VERSION ""

NS_ :

BS_:

BU_: BCMB_AUXM FCIM MRCMA_RSCM SCMJ BCMB_ALCM SCMB_PSM SCMD SCMC HVAC_RCCM MRCMB MRCMA DASM GFM_FTRM BCMB_CAPM DCMH SFMB SFMA SOBDMD_AHCM_FOH TRM GWM _delete BCMB_ABM SODL SCMF RTM RHVAC PDM DCMG DCMF DCME SCMH SCMG HSWM RSM SODR DDM RBM RGTM DSM SCME GENERIC TSTR

BO_ 1861 TesterPhysicalReqDASM: 8 TSTR
 SG_ TesterPhysicalReqDASM : 7|64@0+ (1,0) [0|1.84467E+019] "unitless"  DASM

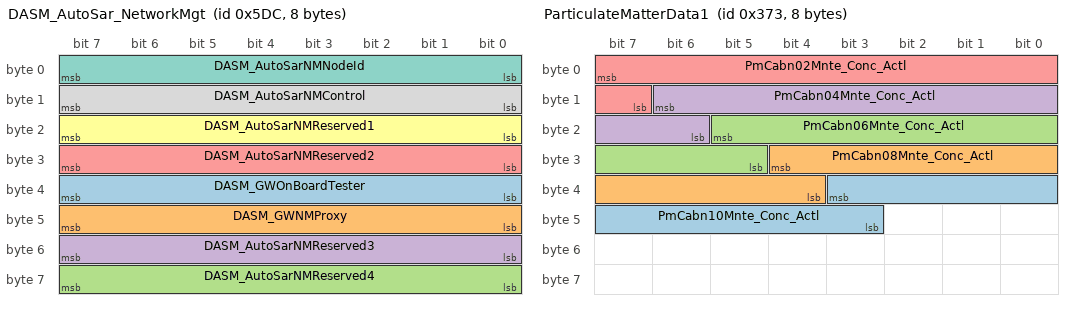
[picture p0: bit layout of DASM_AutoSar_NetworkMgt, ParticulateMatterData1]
BO_ 1500 DASM_AutoSar_NetworkMgt: 8 DASM
 SG_ DASM_GWOnBoardTester : 39|8@0+ (1,0) [0|255] "unitless"  GWM
 SG_ DASM_GWNMProxy : 47|8@0+ (1,0) [0|255] "unitless"  GWM
 SG_ DASM_AutoSarNMReserved4 : 63|8@0+ (1,0) [0|255] "unitless"  GWM
 SG_ DASM_AutoSarNMReserved3 : 55|8@0+ (1,0) [0|255] "unitless"  GWM
 SG_ DASM_AutoSarNMReserved2 : 31|8@0+ (1,0) [0|255] "unitless"  GWM
 SG_ DASM_AutoSarNMReserved1 : 23|8@0+ (1,0) [0|255] "unitless"  GWM
 SG_ DASM_AutoSarNMNodeId : 7|8@0+ (1,0) [0|255] "unitless"  GWM
 SG_ DASM_AutoSarNMControl : 15|8@0+ (1,0) [0|255] "unitless"  GWM

BO_ 1799 TesterPhysicalReqGFM3_MS1: 8 TSTR
 SG_ TesterPhysicalReqGFM3_FSLM : 7|64@0+ (1,0) [0|1.84467E+019] "unitless" Vector__XXX

BO_ 883 ParticulateMatterData1: 8 HVAC_RCCM
 SG_ PmCabn10Mnte_Conc_Actl : 35|9@0+ (1,0) [0|509] "parts/million"  GWM
 SG_ PmCabn08Mnte_Conc_Actl : 28|9@0+ (1,0) [0|509] "parts/million"  GWM
 SG_ PmCabn06Mnte_Conc_Actl : 21|9@0+ (1,0) [0|509] "parts/million"  GWM
 SG_ PmCabn04Mnte_Conc_Actl : 14|9@0+ (1,0) [0|509] "parts/million"  GWM
 SG_ PmCabn02Mnte_Conc_Actl : 7|9@0+ (1,0) [0|509] "parts/million"  GWM

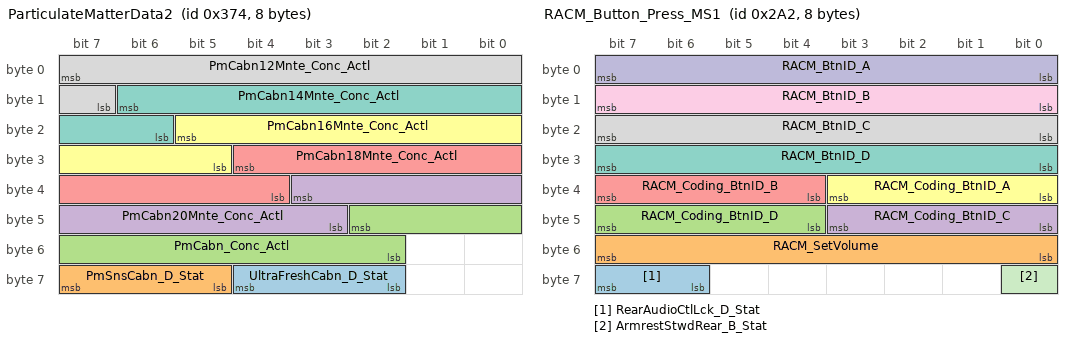
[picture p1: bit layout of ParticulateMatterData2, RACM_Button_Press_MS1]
BO_ 884 ParticulateMatterData2: 8 HVAC_RCCM
 SG_ UltraFreshCabn_D_Stat : 60|3@0+ (1,0) [0|7] "SED"  GWM
 SG_ PmSnsCabn_D_Stat : 63|3@0+ (1,0) [0|7] "SED"  GWM
 SG_ PmCabn_Conc_Actl : 42|9@0+ (1,0) [0|509] "parts/million"  GWM
 SG_ PmCabn20Mnte_Conc_Actl : 35|9@0+ (1,0) [0|509] "parts/million"  GWM
 SG_ PmCabn18Mnte_Conc_Actl : 28|9@0+ (1,0) [0|509] "parts/million"  GWM
 SG_ PmCabn16Mnte_Conc_Actl : 21|9@0+ (1,0) [0|509] "parts/million"  GWM
 SG_ PmCabn14Mnte_Conc_Actl : 14|9@0+ (1,0) [0|509] "parts/million"  GWM
 SG_ PmCabn12Mnte_Conc_Actl : 7|9@0+ (1,0) [0|509] "parts/million"  GWM

BO_ 674 RACM_Button_Press_MS1: 8 GWM
 SG_ RearAudioCtlLck_D_Stat : 63|2@0+ (1,0) [0|3] "SED"  GENERIC
 SG_ RACM_SetVolume : 55|8@0+ (1,-30) [-30|30] "unitless"  GENERIC
 SG_ RACM_Coding_BtnID_D : 47|4@0+ (1,0) [0|15] "SED"  GENERIC
 SG_ RACM_Coding_BtnID_C : 43|4@0+ (1,0) [0|15] "SED"  GENERIC
 SG_ RACM_Coding_BtnID_B : 39|4@0+ (1,0) [0|15] "SED"  GENERIC
 SG_ RACM_Coding_BtnID_A : 35|4@0+ (1,0) [0|15] "SED"  GENERIC
 SG_ RACM_BtnID_D : 31|8@0+ (1,0) [0|255] "unitless"  GENERIC
 SG_ RACM_BtnID_C : 23|8@0+ (1,0) [0|255] "unitless"  GENERIC
 SG_ RACM_BtnID_B : 15|8@0+ (1,0) [0|255] "unitless"  GENERIC
 SG_ RACM_BtnID_A : 7|8@0+ (1,0) [0|255] "unitless"  GENERIC
 SG_ ArmrestStwdRear_B_Stat : 56|1@0+ (1,0) [0|1] "SED"  RHVAC

BO_ 2611177688 PARSEDPhysGWM_ECGtoRTM: 8 GWM
 SG_ PARSEDPhysGWM_ECGtoRTM : 7|29@0+ (1,0) [0|536870911] "unitless"  RTM

BO_ 2611175642 PARSEDPhysRTMtoGWM_ECG: 8 RTM
 SG_ PARSEDPhysRTMtoGWM_ECG : 7|29@0+ (1,0) [0|536870911] "unitless"  GWM

BO_ 2612224218 PARSEDPushRTMtoGWM_ECG: 8 RTM
 SG_ PARSEDPushRTMtoGWM_ECG : 7|29@0+ (1,0) [0|536870911] "unitless"  GWM

BO_ 1349 RBM_Network_MgmtM: 8 RBM
 SG_ RBM_Network_Mgmt : 7|64@0+ (1,0) [0|1.84467440737096E+019] "unitless"  GENERIC

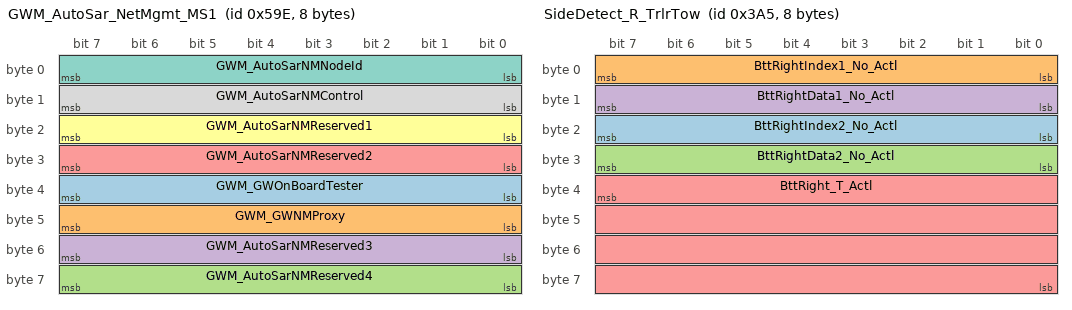
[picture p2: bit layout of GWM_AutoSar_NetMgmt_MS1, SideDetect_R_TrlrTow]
BO_ 1438 GWM_AutoSar_NetMgmt_MS1: 8 GWM
 SG_ GWM_GWOnBoardTester : 39|8@0+ (1,0) [0|255] "unitless"  RHVAC,FCIM,GFM_FTRM,RTM,DCMH,DCMG,DCMF,DCME,HVAC_RCCM,SCMJ,DDM,PDM,RGTM
 SG_ GWM_GWNMProxy : 47|8@0+ (1,0) [0|255] "unitless"  RHVAC,FCIM,GFM_FTRM,RTM,DCMH,DCMG,DCMF,DCME,HVAC_RCCM,SCMJ,DDM,PDM,RGTM
 SG_ GWM_AutoSarNMReserved4 : 63|8@0+ (1,0) [0|255] "unitless"  RHVAC,FCIM,GFM_FTRM,RTM,DCMH,DCMG,DCMF,DCME,HVAC_RCCM,SCMJ,DDM,PDM,RGTM
 SG_ GWM_AutoSarNMReserved3 : 55|8@0+ (1,0) [0|255] "unitless"  RHVAC,FCIM,GFM_FTRM,RTM,DCMH,DCMG,DCMF,DCME,HVAC_RCCM,SCMJ,DDM,PDM,RGTM
 SG_ GWM_AutoSarNMReserved2 : 31|8@0+ (1,0) [0|255] "unitless"  RHVAC,FCIM,GFM_FTRM,RTM,DCMH,DCMG,DCMF,DCME,HVAC_RCCM,SCMJ,DDM,PDM,RGTM
 SG_ GWM_AutoSarNMReserved1 : 23|8@0+ (1,0) [0|255] "unitless"  RHVAC,FCIM,GFM_FTRM,RTM,DCMH,DCMG,DCMF,DCME,HVAC_RCCM,SCMJ,DDM,PDM,RGTM
 SG_ GWM_AutoSarNMNodeId : 7|8@0+ (1,0) [0|255] "unitless"  RHVAC,FCIM,GFM_FTRM,DCMH,DCMG,DCMF,DCME,RTM,HVAC_RCCM,SCMJ,DDM,PDM,RGTM
 SG_ GWM_AutoSarNMControl : 15|8@0+ (1,0) [0|255] "unitless"  RHVAC,FCIM,GFM_FTRM,DCMH,DCMG,DCMF,DCME,RTM,HVAC_RCCM,SCMJ,DDM,PDM,RGTM

BO_ 933 SideDetect_R_TrlrTow: 8 SODR
 SG_ BttRightIndex2_No_Actl : 23|8@0+ (1,0) [0|255] "unitless"  GWM,SODL
 SG_ BttRightIndex1_No_Actl : 7|8@0+ (1,0) [0|255] "unitless"  GWM,SODL
 SG_ BttRightData2_No_Actl : 31|8@0+ (1,0) [0|255] "unitless"  GWM,SODL
 SG_ BttRightData1_No_Actl : 15|8@0+ (1,0) [0|255] "unitless"  GWM,SODL
 SG_ BttRight_T_Actl : 39|32@0+ (1,0) [0|4294967295] "ms"  GWM,SODL

BO_ 841 FuelOpHeater_Stat2: 8 SOBDMD_AHCM_FOH
 SG_ FohStrtDateDay_No_Stat : 7|16@0+ (1,0) [0|65535] "julian day"  GWM
 SG_ FohStrtDateYr_No_Stat : 23|8@0+ (1,2000) [2000|2255] "year"  GWM
 SG_ FohAddHeater_D_Stat : 31|2@0+ (1,0) [0|3] "SED"  GWM

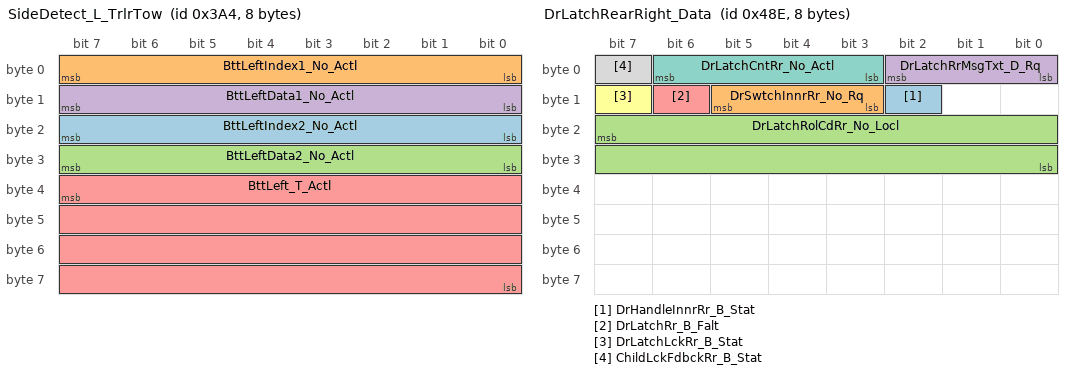
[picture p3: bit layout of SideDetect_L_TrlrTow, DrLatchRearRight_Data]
BO_ 932 SideDetect_L_TrlrTow: 8 SODL
 SG_ BttLeftIndex2_No_Actl : 23|8@0+ (1,0) [0|255] "unitless"  GWM,SODR
 SG_ BttLeftIndex1_No_Actl : 7|8@0+ (1,0) [0|255] "unitless"  GWM,SODR
 SG_ BttLeftData2_No_Actl : 31|8@0+ (1,0) [0|255] "unitless"  GWM,SODR
 SG_ BttLeftData1_No_Actl : 15|8@0+ (1,0) [0|255] "unitless"  GWM,SODR
 SG_ BttLeft_T_Actl : 39|32@0+ (1,0) [0|4294967295] "ms"  GWM,SODR

BO_ 1075 BodyGatewayData_3_MS1: 8 GWM
 SG_ ACU_RadioSeekMode2_St : 60|5@0+ (1,0) [0|31] "SED"  DCMH,DCMG,DDM,PDM,RGTM
 SG_ ACU_CurrTUBand_St : 45|4@0+ (1,0) [0|15] "SED"  DCMH,DCMG,DDM,PDM,RGTM
 SG_ ACU_CurrentFreq_St : 55|11@0+ (1,0) [0|1557] "unitless"  DCMH,DCMG,DDM,PDM,RGTM
 SG_ ACU_RadioSeekMode2_St_UB : 41|1@0+ (1,0) [0|1] "SED"  DCMH,DCMG,DDM,PDM,RGTM
 SG_ ACU_CurrTUBand_St_UB : 32|1@0+ (1,0) [0|1] "SED"  DCMH,DCMG,DDM,PDM,RGTM
 SG_ ACU_CurrentFreq_St_UB : 33|1@0+ (1,0) [0|1] "SED"  DCMH,DCMG,DDM,PDM,RGTM
 SG_ CtaBrk_D_Stat_UB : 40|1@0+ (1,0) [0|1] "SED"  SODR,SODL
 SG_ CtaBrk_D_Stat : 47|2@0+ (1,0) [0|3] "SED"  SODR,SODL
 SG_ SelDrvMdePt_D_Rq_UB : 34|1@0+ (1,0) [0|1] "SED"  FCIM,HVAC_RCCM
 SG_ SelDrvMdePt_D_Rq : 39|5@0+ (1,0) [0|31] "SED"  FCIM,HVAC_RCCM
 SG_ PrkAidSnsRrCrnr_D_Stat : 19|4@0+ (1,0) [0|15] "SED"  SODR,SODL
 SG_ PrkAidSnsRrCntr_D_Stat : 31|4@0+ (1,0) [0|15] "SED"  SODR,SODL
 SG_ PrkAidSnsRlCrnr_D_Stat : 13|4@0+ (1,0) [0|15] "SED"  SODR,SODL
 SG_ PrkAidSnsRlCntr_D_Stat : 23|4@0+ (1,0) [0|15] "SED"  SODR,SODL
 SG_ PrkAidSnsRrCrnr_D_Stat_UB : 27|1@0+ (1,0) [0|1] "SED"  SODR,SODL
 SG_ PrkAidSnsRrCntr_D_Stat_UB : 26|1@0+ (1,0) [0|1] "SED"  SODR,SODL
 SG_ PrkAidSnsRlCntr_D_Stat_UB : 8|1@0+ (1,0) [0|1] "SED"  SODR,SODL
 SG_ PrkAidSnsRlCrnr_D_Stat_UB : 9|1@0+ (1,0) [0|1] "SED"  SODR,SODL
 SG_ BttOn_B_Rq_UB : 14|1@0+ (1,0) [0|1] "SED"  SODR,SODL
 SG_ Btt_L_Actl_UB : 0|1@0+ (1,0) [0|1] "SED"  SODR,SODL
 SG_ BttOn_B_Rq : 15|1@0+ (1,0) [0|1] "SED"  SODR,SODL
 SG_ Btt_L_Actl : 7|7@0+ (0.1,0) [0|12.5] "meter"  SODR,SODL
 SG_ ArmrestStwdRear_B_Stat_UB : 24|1@0+ (1,0) [0|1] "SED"  RHVAC
 SG_ ArmrestStwdRear_B_Stat : 25|1@0+ (1,0) [0|1] "SED"  RHVAC

BO_ 1166 DrLatchRearRight_Data: 8 DCMH
 SG_ DrHandleInnrRr_B_Stat : 10|1@0+ (1,0) [0|1] "SED"  GWM
 SG_ DrSwtchInnrRr_No_Rq : 13|3@0+ (1,0) [0|7] "unitless"  GWM
 SG_ DrLatchRolCdRr_No_Locl : 23|16@0+ (1,0) [0|65535] "unitless"  GWM
 SG_ DrLatchRrMsgTxt_D_Rq : 2|3@0+ (1,0) [0|7] "SED"  GWM
 SG_ DrLatchRr_B_Falt : 14|1@0+ (1,0) [0|1] "SED"  GWM
 SG_ DrLatchLckRr_B_Stat : 15|1@0+ (1,0) [0|1] "SED"  GWM
 SG_ DrLatchCntRr_No_Actl : 6|4@0+ (1,0) [0|15] "unitless"  GWM
 SG_ ChildLckFdbckRr_B_Stat : 7|1@0+ (1,0) [0|1] "SED"  GWM

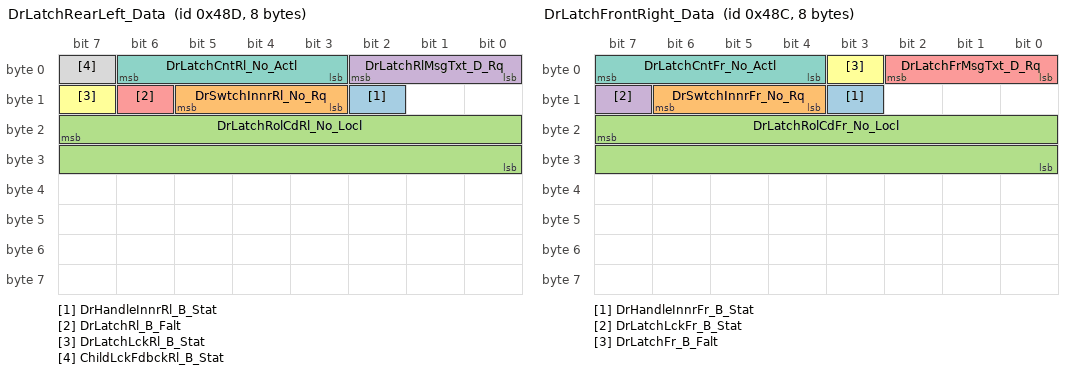
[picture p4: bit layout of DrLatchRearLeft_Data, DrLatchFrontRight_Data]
BO_ 1165 DrLatchRearLeft_Data: 8 DCMG
 SG_ DrHandleInnrRl_B_Stat : 10|1@0+ (1,0) [0|1] "SED"  GWM
 SG_ DrSwtchInnrRl_No_Rq : 13|3@0+ (1,0) [0|7] "unitless"  GWM
 SG_ DrLatchRolCdRl_No_Locl : 23|16@0+ (1,0) [0|65535] "unitless"  GWM
 SG_ DrLatchRlMsgTxt_D_Rq : 2|3@0+ (1,0) [0|7] "SED"  GWM
 SG_ DrLatchRl_B_Falt : 14|1@0+ (1,0) [0|1] "SED"  GWM
 SG_ DrLatchLckRl_B_Stat : 15|1@0+ (1,0) [0|1] "SED"  GWM
 SG_ DrLatchCntRl_No_Actl : 6|4@0+ (1,0) [0|15] "unitless"  GWM
 SG_ ChildLckFdbckRl_B_Stat : 7|1@0+ (1,0) [0|1] "SED"  GWM

BO_ 1164 DrLatchFrontRight_Data: 8 DCMF
 SG_ DrHandleInnrFr_B_Stat : 11|1@0+ (1,0) [0|1] "SED"  GWM
 SG_ DrSwtchInnrFr_No_Rq : 14|3@0+ (1,0) [0|7] "unitless"  GWM
 SG_ DrLatchRolCdFr_No_Locl : 23|16@0+ (1,0) [0|65535] "unitless"  GWM
 SG_ DrLatchLckFr_B_Stat : 15|1@0+ (1,0) [0|1] "SED"  GWM
 SG_ DrLatchFrMsgTxt_D_Rq : 2|3@0+ (1,0) [0|7] "SED"  GWM
 SG_ DrLatchFr_B_Falt : 3|1@0+ (1,0) [0|1] "SED"  GWM
 SG_ DrLatchCntFr_No_Actl : 7|4@0+ (1,0) [0|15] "unitless"  GWM

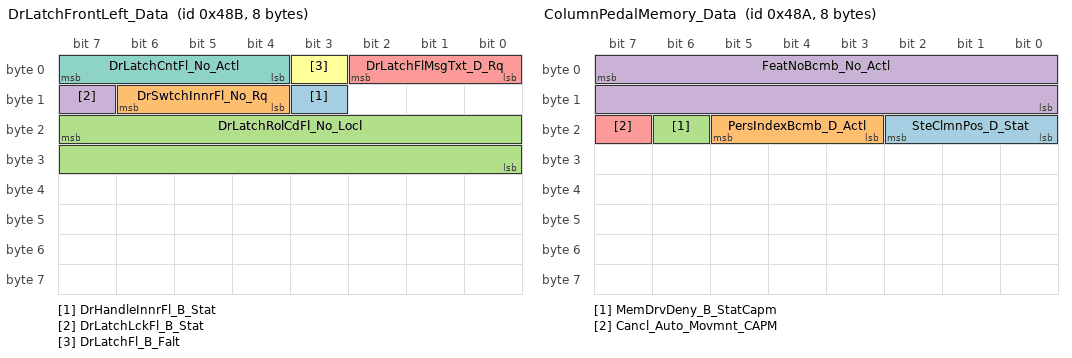
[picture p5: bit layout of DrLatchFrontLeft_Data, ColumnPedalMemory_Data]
BO_ 1163 DrLatchFrontLeft_Data: 8 DCME
 SG_ DrHandleInnrFl_B_Stat : 11|1@0+ (1,0) [0|1] "SED"  GWM
 SG_ DrSwtchInnrFl_No_Rq : 14|3@0+ (1,0) [0|7] "unitless"  GWM
 SG_ DrLatchRolCdFl_No_Locl : 23|16@0+ (1,0) [0|65535] "unitless"  GWM
 SG_ DrLatchLckFl_B_Stat : 15|1@0+ (1,0) [0|1] "SED"  GWM
 SG_ DrLatchFlMsgTxt_D_Rq : 2|3@0+ (1,0) [0|7] "SED"  GWM
 SG_ DrLatchFl_B_Falt : 3|1@0+ (1,0) [0|1] "SED"  GWM
 SG_ DrLatchCntFl_No_Actl : 7|4@0+ (1,0) [0|15] "unitless"  GWM

BO_ 1162 ColumnPedalMemory_Data: 8 BCMB_CAPM
 SG_ SteClmnPos_D_Stat : 18|3@0+ (1,0) [0|7] "SED"  DSM
 SG_ PersIndexBcmb_D_Actl : 21|3@0+ (1,0) [0|7] "SED"  DSM
 SG_ MemDrvDeny_B_StatCapm : 22|1@0+ (1,0) [0|1] "SED"  DSM
 SG_ FeatNoBcmb_No_Actl : 7|16@0+ (1,0) [0|65535] "Number"  DSM
 SG_ Cancl_Auto_Movmnt_CAPM : 23|1@0+ (1,0) [0|1] "SED"  DSM

BO_ 1961 TesterPhysicalResGFM_FTRM: 8 GFM_FTRM
 SG_ TesterPhysicalResGFM_FTRM : 7|64@0+ (1,0) [0|1.84467E+019] "unitless"  TSTR

BO_ 1954 TesterPhysicalReqDCME: 8 TSTR
 SG_ TesterPhysicalReqDCME : 7|64@0+ (1,0) [0|1.84467E+019] "unitless"  DCME

BO_ 1972 TesterPhysicalReqDCMH: 8 TSTR
 SG_ TesterPhysicalReqDCMH : 7|64@0+ (1,0) [0|1.84467E+019] "unitless"  DCMH

BO_ 1963 TesterPhysicalResSCMB_PSM: 8 SCMB_PSM
 SG_ TesterPhysicalResSCMB_PSM : 7|64@0+ (1,0) [0|1.84467E+019] "unitless"  TSTR

BO_ 1955 TesterPhysicalReqSCMB_PSM: 8 TSTR
 SG_ TesterPhysicalReqSCMB_PSM : 7|64@0+ (1,0) [0|1.84467E+019] "unitless"  SCMB_PSM

BO_ 1953 TesterPhysicalReqGFM_FTRM: 8 TSTR
 SG_ TesterPhysicalReqGFM_FTRM : 7|64@0+ (1,0) [0|1.84467E+019] "unitless"  GFM_FTRM,GENERIC

BO_ 1891 TesterPhysicalReqSCMD: 8 TSTR
 SG_ TesterPhysicalReqSCMD : 7|64@0+ (1,0) [0|1.84467E+019] "unitless"  SCMD

BO_ 1794 TesterPhysicalReqSCMC: 8 TSTR
 SG_ TesterPhysicalReqSCMC : 7|64@0+ (1,0) [0|1.84467E+019] "unitless"  SCMC

BO_ 1356 MRCMB_Network_MgmtM: 8 MRCMB
 SG_ MRCMB_Network_Mgmt : 7|64@0+ (1,0) [0|1.84467440737096E+019] "unitless"  GENERIC

BO_ 978 ConvertibleTop_Slave: 8 MRCMB
 SG_ CnvtTopTWarn_B_Falt : 25|1@0+ (1,0) [0|1] "SED"  MRCMA
 SG_ CnvtTopTOvr_B_Falt : 26|1@0+ (1,0) [0|1] "SED"  MRCMA
 SG_ CnvtTopTDir_B_Falt : 27|1@0+ (1,0) [0|1] "SED"  MRCMA
 SG_ CnvtTopStall_B_Falt : 28|1@0+ (1,0) [0|1] "SED"  MRCMA
 SG_ CnvtTopSns_B_Falt : 29|1@0+ (1,0) [0|1] "SED"  MRCMA
 SG_ CnvtTopRvrse_B_Stat : 30|1@0+ (1,0) [0|1] "SED"  MRCMA
 SG_ CnvtTopRngOpen_B_Stat : 31|1@0+ (1,0) [0|1] "SED"  MRCMA
 SG_ CnvtTopRngClose_B_Stat : 16|1@0+ (1,0) [0|1] "SED"  MRCMA
 SG_ CnvtTopRestrc_B_Falt : 17|1@0+ (1,0) [0|1] "SED"  MRCMA
 SG_ CnvtTopRdy_B_Stat : 18|1@0+ (1,0) [0|1] "SED"  MRCMA
 SG_ CnvtTopPosSet_B_Stat : 19|1@0+ (1,0) [0|1] "SED"  MRCMA
 SG_ CnvtTopPos_No_Actl : 39|16@0+ (1,0) [0|65535] "unitless"  MRCMA
 SG_ CnvtTopPos_D_Stat : 23|4@0+ (1,0) [0|15] "SED"  MRCMA
 SG_ CnvtTopPos_B_Falt : 8|1@0+ (1,0) [0|1] "SED"  MRCMA
 SG_ CnvtTopOut_B_Falt : 9|1@0+ (1,0) [0|1] "SED"  MRCMA
 SG_ CnvtTopOpen_D_Stat : 11|2@0+ (1,0) [0|3] "SED"  MRCMA
 SG_ CnvtTopOpen_B_Stat : 12|1@0+ (1,0) [0|1] "SED"  MRCMA
 SG_ CnvtTopNom_B_Stat : 13|1@0+ (1,0) [0|1] "SED"  MRCMA
 SG_ CnvtTopDir_B_Falt : 0|1@0+ (1,0) [0|1] "SED"  MRCMA
 SG_ CnvtTopComplt_No_Cnt : 15|2@0+ (1,0) [0|3] "unitless"  MRCMA
 SG_ CnvtTopComplt_D_Stat : 3|3@0+ (1,0) [0|7] "SED"  MRCMA
 SG_ CnvtTopCnfm_B_Stat : 4|1@0+ (1,0) [0|1] "SED"  MRCMA
 SG_ CnvtTopClose_D_Stat : 6|2@0+ (1,0) [0|3] "SED"  MRCMA
 SG_ CnvtTopActv_B_Stat : 7|1@0+ (1,0) [0|1] "SED"  MRCMA
 SG_ TonneuCapMde_D_Stat : 55|2@0+ (1,0) [0|3] "SED"  MRCMA

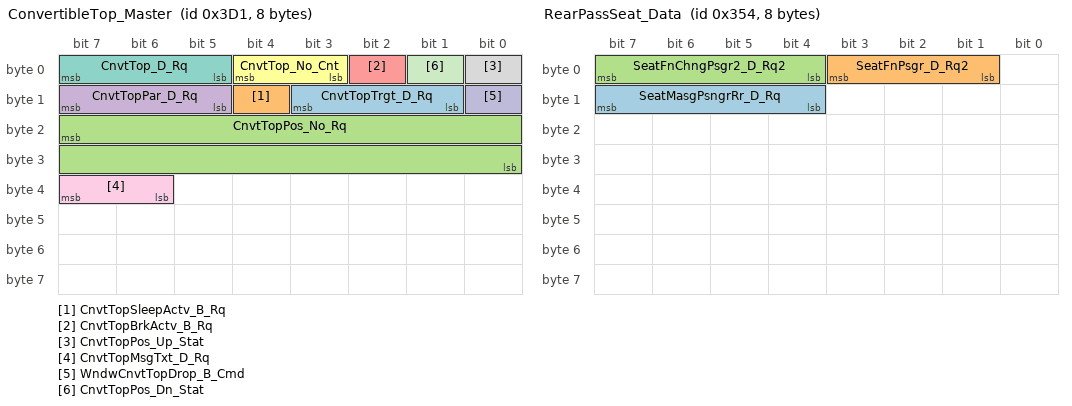
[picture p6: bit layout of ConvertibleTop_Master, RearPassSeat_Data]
BO_ 977 ConvertibleTop_Master: 8 MRCMA
 SG_ CnvtTopTrgt_D_Rq : 11|3@0+ (1,0) [0|7] "SED"  MRCMB
 SG_ CnvtTopSleepActv_B_Rq : 12|1@0+ (1,0) [0|1] "SED"  MRCMB
 SG_ CnvtTopPos_No_Rq : 23|16@0+ (1,0) [0|65535] "unitless"  MRCMB
 SG_ CnvtTopPar_D_Rq : 15|3@0+ (1,0) [0|7] "SED"  MRCMB
 SG_ CnvtTopBrkActv_B_Rq : 2|1@0+ (1,0) [0|1] "SED"  MRCMB
 SG_ CnvtTop_No_Cnt : 4|2@0+ (1,0) [0|3] "unitless"  MRCMB
 SG_ CnvtTop_D_Rq : 7|3@0+ (1,0) [0|7] "SED"  MRCMB
 SG_ CnvtTopPos_Up_Stat : 0|1@0+ (1,0) [0|1] "SED"  BCMB_ABM,GWM
 SG_ CnvtTopMsgTxt_D_Rq : 39|2@0+ (1,0) [0|3] "SED"  GWM
 SG_ WndwCnvtTopDrop_B_Cmd : 8|1@0+ (1,0) [0|1] "SED"  BCMB_ABM
 SG_ CnvtTopPos_Dn_Stat : 1|1@0+ (1,0) [0|1] "SED"  BCMB_ABM,GWM

BO_ 1976 TesterPhysicalResMRCMB: 8 MRCMB
 SG_ TesterPhysicalResMRCMB : 7|64@0+ (1,0) [0|1.84467E+019] "unitless"  TSTR

BO_ 1944 TesterPhysicalResMRCMA: 8 MRCMA
 SG_ TesterPhysicalResMRCMA : 7|64@0+ (1,0) [0|1.84467E+019] "unitless"  TSTR

BO_ 1968 TesterPhysicalReqMRCMB: 8 TSTR
 SG_ TesterPhysicalReqMRCMB : 7|64@0+ (1,0) [0|1.84467E+019] "unitless"  MRCMB

BO_ 1936 TesterPhysicalReqMRCMA: 8 TSTR
 SG_ TesterPhysicalReqMRCMA : 7|64@0+ (1,0) [0|1.84467E+019] "unitless"  MRCMA_RSCM,MRCMA

BO_ 968 Cluster_Lighting_Rq_MS1: 8 GWM
 SG_ BrkDrvMde_D_Rq : 18|3@0+ (1,0) [0|7] "SED"  GENERIC
 SG_ LnchCtl_N_Rq : 55|8@0+ (50,0) [0|12750] "rpm"  GENERIC
 SG_ LnchCtl_D_Rq : 63|2@0+ (1,0) [0|3] "SED"  GENERIC
 SG_ SlMde_D_Rq : 27|2@0+ (1,0) [0|3] "SED"  GENERIC
 SG_ IsaOffst_D_Rq : 31|4@0+ (1,0) [0|15] "SED"  GENERIC
 SG_ CurrentColor_CmdGage : 43|4@0+ (1,0) [0|15] "SED"  GENERIC
 SG_ BlendedColor_CmdGage : 25|2@0+ (1,0) [0|3] "SED"  GENERIC
 SG_ BlendColorRed_CmdGage : 47|4@0+ (1,0) [0|15] "SED"  GENERIC
 SG_ BlendColorGrn_CmdGage : 35|4@0+ (1,0) [0|15] "SED"  GENERIC
 SG_ BlendColorBlue_CmdGage : 39|4@0+ (1,0) [0|15] "SED"  GENERIC
 SG_ Dimming_Level_Cmd : 1|2@0+ (1,0) [0|3] "SED"  BCMB_ABM,BCMB_ALCM
 SG_ Current_Color_Cmd : 23|4@0+ (1,0) [0|15] "SED"  BCMB_ABM,BCMB_ALCM
 SG_ BlendedColorRed_Cmd : 11|4@0+ (1,0) [0|15] "SED"  BCMB_ABM,BCMB_ALCM
 SG_ BlendedColorGreen_Cmd : 15|4@0+ (1,0) [0|15] "SED"  BCMB_ABM,BCMB_ALCM
 SG_ BlendedColorBlue_Cmd : 5|4@0+ (1,0) [0|15] "SED"  BCMB_ABM,BCMB_ALCM
 SG_ BlendedColor_Cmd : 7|2@0+ (1,0) [0|3] "SED"  BCMB_ABM,BCMB_ALCM
 SG_ SuspDrvMde_D_Rq : 61|3@0+ (1,0) [0|7] "SED"  GENERIC

BO_ 1971 TesterPhysicalReqDCMG: 8 TSTR
 SG_ TesterPhysicalReqDCMG : 7|64@0+ (1,0) [0|1.84467E+019] "unitless"  DCMG

BO_ 1890 TesterPhysicalReqDCMF: 8 TSTR
 SG_ TesterPhysicalReqDCMF : 7|64@0+ (1,0) [0|1.84467E+019] "unitless"  DCMF

BO_ 1980 TesterPhysicalResDCMH: 8 DCMH
 SG_ TesterPhysicalResDCMH : 7|64@0+ (1,0) [0|1.84467E+019] "unitless"  TSTR

BO_ 1979 TesterPhysicalResDCMG: 8 DCMG
 SG_ TesterPhysicalResDCMG : 7|64@0+ (1,0) [0|1.84467E+019] "unitless"  TSTR

BO_ 852 RearPassSeat_Data: 8 SFMB
 SG_ SeatMasgPsngrRr_D_Rq : 15|4@0+ (1,0) [0|15] "SED"  SCMD
 SG_ SeatFnPsgr_D_Rq2 : 3|3@0+ (1,0) [0|7] "SED"  SCMD
 SG_ SeatFnChngPsgr2_D_Rq2 : 7|4@0+ (1,0) [0|15] "SED"  SCMD

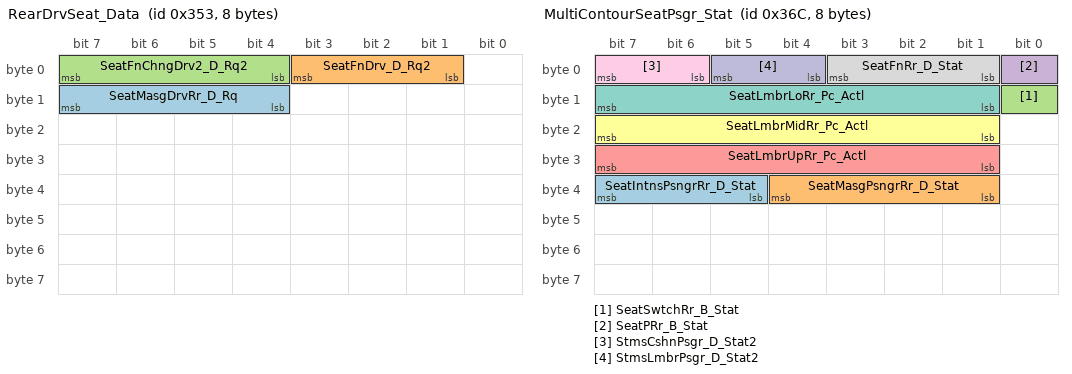
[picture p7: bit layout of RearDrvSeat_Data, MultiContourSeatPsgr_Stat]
BO_ 851 RearDrvSeat_Data: 8 SFMA
 SG_ SeatMasgDrvRr_D_Rq : 15|4@0+ (1,0) [0|15] "SED"  SCMC
 SG_ SeatFnDrv_D_Rq2 : 3|3@0+ (1,0) [0|7] "SED"  SCMC
 SG_ SeatFnChngDrv2_D_Rq2 : 7|4@0+ (1,0) [0|15] "SED"  SCMC

BO_ 876 MultiContourSeatPsgr_Stat: 8 SCMD
 SG_ SeatIntnsPsngrRr_D_Stat : 39|3@0+ (1,0) [0|7] "SED"  GWM
 SG_ SeatMasgPsngrRr_D_Stat : 36|4@0+ (1,0) [0|15] "SED"  GWM
 SG_ SeatSwtchRr_B_Stat : 8|1@0+ (1,0) [0|1] "SED"  GWM
 SG_ SeatPRr_B_Stat : 0|1@0+ (1,0) [0|1] "SED"  GWM
 SG_ SeatLmbrUpRr_Pc_Actl : 31|7@0+ (1,0) [0|127] "Percent"  GWM
 SG_ SeatLmbrMidRr_Pc_Actl : 23|7@0+ (1,0) [0|127] "Percent"  GWM
 SG_ SeatLmbrLoRr_Pc_Actl : 15|7@0+ (1,0) [0|127] "Percent"  GWM
 SG_ SeatFnRr_D_Stat : 3|3@0+ (1,0) [0|7] "SED"  GWM
 SG_ StmsCshnPsgr_D_Stat2 : 7|2@0+ (1,0) [0|3] "SED"  GWM,SFMB
 SG_ StmsLmbrPsgr_D_Stat2 : 5|2@0+ (1,0) [0|3] "SED"  SFMB,GWM

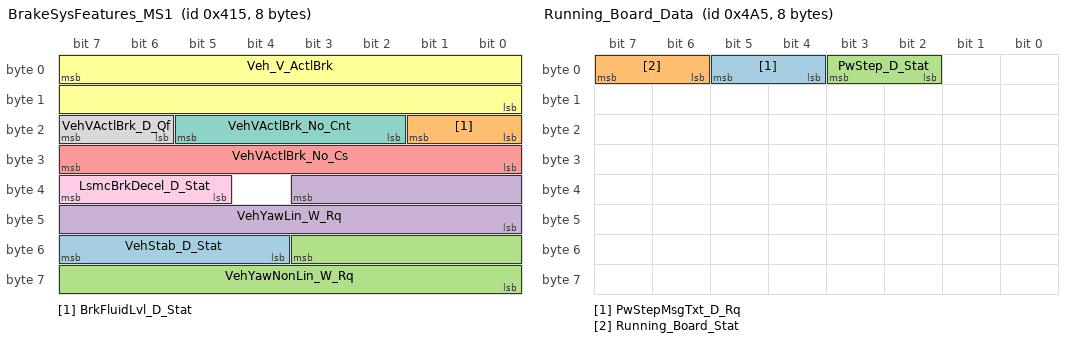
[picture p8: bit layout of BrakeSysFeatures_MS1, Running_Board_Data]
BO_ 1045 BrakeSysFeatures_MS1: 8 GWM
 SG_ VehStab_D_Stat : 55|4@0+ (1,0) [0|15] "SED"  GENERIC
 SG_ BrkFluidLvl_D_Stat : 17|2@0+ (1,0) [0|3] "SED"  GENERIC
 SG_ VehYawNonLin_W_Rq : 51|12@0+ (0.03663,-75) [-75|74.92659] "deg/s"  GENERIC
 SG_ VehYawLin_W_Rq : 35|12@0+ (0.03663,-75) [-75|74.92659] "deg/s"  GENERIC
 SG_ VehVActlBrk_No_Cs : 31|8@0+ (1,0) [0|255] "Unitless"  GFM_FTRM,DSM,TRM
 SG_ Veh_V_ActlBrk : 7|16@0+ (0.01,0) [0|655.35] "kph"  GFM_FTRM,DSM,TRM
 SG_ VehVActlBrk_No_Cnt : 21|4@0+ (1,0) [0|15] "Unitless"  GFM_FTRM,DSM,TRM
 SG_ VehVActlBrk_D_Qf : 23|2@0+ (1,0) [0|3] "SED"  GFM_FTRM,DSM,TRM
 SG_ LsmcBrkDecel_D_Stat : 39|3@0+ (1,0) [0|7] "SED"  GENERIC

BO_ 1189 Running_Board_Data: 8 RBM
 SG_ PwStepMsgTxt_D_Rq : 5|2@0+ (1,0) [0|3] "SED"  GWM
 SG_ Running_Board_Stat : 7|2@0+ (1,0) [0|3] "SED"  GWM
 SG_ PwStep_D_Stat : 3|2@0+ (1,0) [0|3] "SED"  GWM

BO_ 858 Rear_Climate_Data: 8 RHVAC
 SG_ ClimtSyncRear_B_Stat : 58|1@0+ (1,0) [0|1] "SED"  GWM,HVAC_RCCM
 SG_ ClimtSeatHeatRr_B_Stat : 54|1@0+ (1,0) [0|1] "SED"  GWM,HVAC_RCCM
 SG_ ClimtSeatHeatRl_B_Stat : 55|1@0+ (1,0) [0|1] "SED"  GWM,HVAC_RCCM
 SG_ ClimtSeatCoolRr_B_Stat : 52|1@0+ (1,0) [0|1] "SED"  GWM,HVAC_RCCM
 SG_ ClimtSeatCoolRl_B_Stat : 53|1@0+ (1,0) [0|1] "SED"  GWM,HVAC_RCCM
 SG_ ClimtRearTe3rd_D_Stat : 51|2@0+ (1,0) [0|3] "SED"  GWM,HVAC_RCCM
 SG_ ClimtRearPw3rd_B_Stat : 59|1@0+ (1,0) [0|1] "SED"  GWM,HVAC_RCCM
 SG_ ClimtRearPnl3rd_B_Stat : 62|1@0+ (1,0) [0|1] "SED"  GWM,HVAC_RCCM
 SG_ ClimtRearPf3rd_B_Stat : 63|1@0+ (1,0) [0|1] "SED"  GWM,HVAC_RCCM
 SG_ ClimtRearFlr3rd_B_Stat : 61|1@0+ (1,0) [0|1] "SED"  GWM,HVAC_RCCM
 SG_ ClimtRearBlwr3rd_D_Stat : 49|2@0+ (1,0) [0|3] "SED"  GWM,HVAC_RCCM
 SG_ ClimtRearAuto3rd_B_Stat : 60|1@0+ (1,0) [0|1] "SED"  GWM,HVAC_RCCM
 SG_ ClimtRearViewR_D_Stat : 57|2@0+ (1,0) [0|3] "SED"  GWM,HVAC_RCCM
 SG_ ClimtRearTe_D_Stat : 11|2@0+ (1,0) [0|3] "SED"  FCIM,GWM,HVAC_RCCM
 SG_ ClimtRearTe_An_Actl : 7|9@0+ (1,0) [0|510] "degrees"  FCIM,GWM,HVAC_RCCM
 SG_ ClimtRearPw_B_Stat : 29|1@0+ (1,0) [0|1] "SED"  FCIM,GWM,HVAC_RCCM
 SG_ ClimtRearPnlFlr_B_Stat : 13|1@0+ (1,0) [0|1] "SED"  FCIM,GWM,HVAC_RCCM
 SG_ ClimtRearPnl_B_Stat : 14|1@0+ (1,0) [0|1] "SED"  FCIM,GWM,HVAC_RCCM
 SG_ ClimtRearFlr_B_Stat : 12|1@0+ (1,0) [0|1] "SED"  FCIM,GWM,HVAC_RCCM
 SG_ ClimtRearBlwr_D_Stat : 9|2@0+ (1,0) [0|3] "SED"  FCIM,GWM,HVAC_RCCM
 SG_ ClimtRearBlwr_An_Actl : 23|9@0+ (1,0) [0|510] "degrees"  FCIM,GWM,HVAC_RCCM
 SG_ ClimtRearAuto_B_Stat : 30|1@0+ (1,0) [0|1] "SED"  FCIM,GWM,HVAC_RCCM

BO_ 1925 TesterPhysicalReqRHVAC: 8 TSTR
 SG_ TesterPhysicalReqRHVAC : 7|64@0+ (1,0) [0|1.84467E+019] "unitless"  RHVAC

BO_ 1933 TesterPhysicalResRHVAC: 8 RHVAC
 SG_ TesterPhysicalResRHVAC : 7|64@0+ (1,0) [0|1.84467E+019] "unitless"  TSTR

BO_ 2611120344 PARSEDPhysGWM_ECGtoDSM: 8 GWM
 SG_ PARSEDPhysGWM_ECGtoDSM : 7|29@0+ (1,0) [0|536870911] "unitless"  DSM

BO_ 2611175586 PARSEDPhysDSMtoGWM_ECG: 8 DSM
 SG_ PARSEDPhysDSMtoGWM_ECG : 7|29@0+ (1,0) [0|536870911] "unitless"  GWM

BO_ 2612224162 PARSEDPushDSMtoGWM_ECG: 8 DSM
 SG_ PARSEDPushDSMtoGWM_ECG : 7|29@0+ (1,0) [0|536870911] "unitless"  GWM

BO_ 2610129112 OTAPhysGWM_ECGtoRTM: 8 GWM
 SG_ OTAPhysGWM_ECGtoRTM : 7|29@0+ (1,0) [0|536870911] "unitless"  RTM

BO_ 2610127066 OTAPhysRTMoGWM_ECG: 8 RTM
 SG_ OTAPhysRTMtoGWM_ECG : 7|29@0+ (1,0) [0|536870911] "unitless"  GWM

BO_ 2610071768 OTAPhysGWM_ECGtoDSM: 8 GWM
 SG_ OTAPhysGWM_ECGtoDSM : 7|29@0+ (1,0) [0|536870911] "unitless"  DSM

BO_ 2610127010 OTAPhysDSMtoGWM_ECG: 8 DSM
 SG_ OTAPhysDSMtoGWM_ECG : 7|29@0+ (1,0) [0|536870911] "unitless"  GWM

BO_ 2611110104 PARSEDPhysGWMECGtoHVACRCCM: 8 GWM
 SG_ PARSEDPhysGWMECGtoHVACRCCM : 7|29@0+ (1,0) [0|536870911] "unitless"  HVAC_RCCM

BO_ 2612224152 PARSEDPushHVACRCCMtoGWM: 8 HVAC_RCCM
 SG_ PARSEPushHVACRCCMtoGWM : 7|29@0+ (1,0) [0|536870911] "unitless"  GWM

BO_ 2611175576 PARSEDPhysHVACRCCMtoGWMECG: 8 HVAC_RCCM
 SG_ PARSEDPhysHVACRCCMtoGWMECG : 7|29@0+ (1,0) [0|536870911] "unitless"  GWM

BO_ 2610061528 OTAPhysGWM_ECGtoHVAC_RCCM: 8 GWM
 SG_ OTAPhysGWM_ECGtoHVAC_RCCM : 7|29@0+ (1,0) [0|536870911] "unitless"  HVAC_RCCM

BO_ 2610127000 OTAPhysHVAC_RCCMtoGWM_ECG: 8 HVAC_RCCM
 SG_ OTAPhysHVAC_RCCMtoGWM_ECG : 7|29@0+ (1,0) [0|536870911] "unitless"  GWM

BO_ 959 GatewayData6_MS1: 8 GWM
 SG_ TrnPrkSys_D_Actl_UB : 3|1@0+ (1,0) [0|1] "SED"  GENERIC
 SG_ TrnPrkSys_D_Actl : 7|4@0+ (1,0) [0|15] "SED"  GENERIC

BO_ 2610126913 OTAPhysSCMJtoGWM_ECG: 8 SCMJ
 SG_ OTAPhysSCMJtoGWM_ECG : 7|29@0+ (1,0) [0|536870911] "unitless"  GWM

BO_ 2612002008 PARSEDFuncGWM_ECG_MS1: 8 GWM
 SG_ PARSEDFuncGWM_ECG : 7|29@0+ (1,0) [0|536870911] "unitless"  RGTM,RSM,HVAC_RCCM,MRCMA_RSCM,DSM,RTM,SCMJ,DDM,PDM

BO_ 2610953432 OTAFuncGWM_ECG_MS1: 8 GWM
 SG_ OTAFuncGWM_ECG : 7|29@0+ (1,0) [0|536870911] "unitless"  RGTM,RSM,HVAC_RCCM,MRCMA_RSCM,SCMJ,DDM,PDM,DSM,RTM

BO_ 2611175489 PARSEDPhysSCMJtoGWM_ECG: 8 SCMJ
 SG_ PARSEDPhysSCMJtoGWM_ECG : 7|29@0+ (1,0) [0|536870911] "Unitless"  GWM

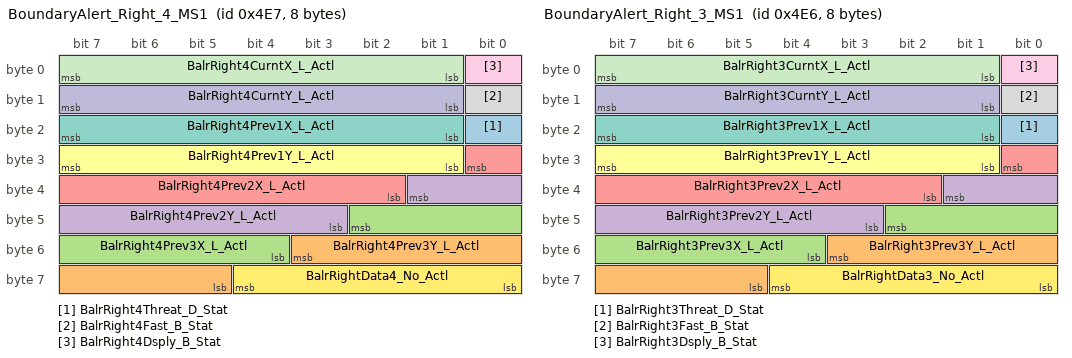
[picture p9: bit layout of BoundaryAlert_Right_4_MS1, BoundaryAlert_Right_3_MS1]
BO_ 1255 BoundaryAlert_Right_4_MS1: 8 SODR
 SG_ BalrRight4Threat_D_Stat : 16|1@0+ (1,0) [0|1] "SED"  GWM,SODL
 SG_ BalrRight4Prev3Y_L_Actl : 51|7@0+ (0.5,-32) [-32|31.5] "meter"  GWM,SODL
 SG_ BalrRight4Prev3X_L_Actl : 42|7@0+ (0.5,-32) [-32|31.5] "meter"  GWM,SODL
 SG_ BalrRight4Prev2Y_L_Actl : 33|7@0+ (0.5,-32) [-32|31.5] "meter"  GWM,SODL
 SG_ BalrRight4Prev2X_L_Actl : 24|7@0+ (0.5,-32) [-32|31.5] "meter"  GWM,SODL
 SG_ BalrRight4Prev1Y_L_Actl : 31|7@0+ (0.5,-32) [-32|31.5] "meter"  GWM,SODL
 SG_ BalrRight4Prev1X_L_Actl : 23|7@0+ (0.5,-32) [-32|31.5] "meter"  GWM,SODL
 SG_ BalrRight4Fast_B_Stat : 8|1@0+ (1,0) [0|1] "SED"  GWM,SODL
 SG_ BalrRight4Dsply_B_Stat : 0|1@0+ (1,0) [0|1] "SED"  GWM,SODL
 SG_ BalrRight4CurntY_L_Actl : 15|7@0+ (0.5,-32) [-32|31.5] "meter"  GWM,SODL
 SG_ BalrRight4CurntX_L_Actl : 7|7@0+ (0.5,-32) [-32|31.5] "meter"  GWM,SODL
 SG_ BalrRightData4_No_Actl : 60|5@0+ (1,0) [0|31] "unitless"  GWM,SODL

BO_ 1254 BoundaryAlert_Right_3_MS1: 8 SODR
 SG_ BalrRight3Threat_D_Stat : 16|1@0+ (1,0) [0|1] "SED"  GWM,SODL
 SG_ BalrRight3Prev3Y_L_Actl : 51|7@0+ (0.5,-32) [-32|31.5] "meter"  GWM,SODL
 SG_ BalrRight3Prev3X_L_Actl : 42|7@0+ (0.5,-32) [-32|31.5] "meter"  GWM,SODL
 SG_ BalrRight3Prev2Y_L_Actl : 33|7@0+ (0.5,-32) [-32|31.5] "meter"  GWM,SODL
 SG_ BalrRight3Prev2X_L_Actl : 24|7@0+ (0.5,-32) [-32|31.5] "meter"  GWM,SODL
 SG_ BalrRight3Prev1Y_L_Actl : 31|7@0+ (0.5,-32) [-32|31.5] "meter"  GWM,SODL
 SG_ BalrRight3Prev1X_L_Actl : 23|7@0+ (0.5,-32) [-32|31.5] "meter"  GWM,SODL
 SG_ BalrRight3Fast_B_Stat : 8|1@0+ (1,0) [0|1] "SED"  GWM,SODL
 SG_ BalrRight3Dsply_B_Stat : 0|1@0+ (1,0) [0|1] "SED"  GWM,SODL
 SG_ BalrRight3CurntY_L_Actl : 15|7@0+ (0.5,-32) [-32|31.5] "meter"  GWM,SODL
 SG_ BalrRight3CurntX_L_Actl : 7|7@0+ (0.5,-32) [-32|31.5] "meter"  GWM,SODL
 SG_ BalrRightData3_No_Actl : 60|5@0+ (1,0) [0|31] "unitless"  GWM,SODL

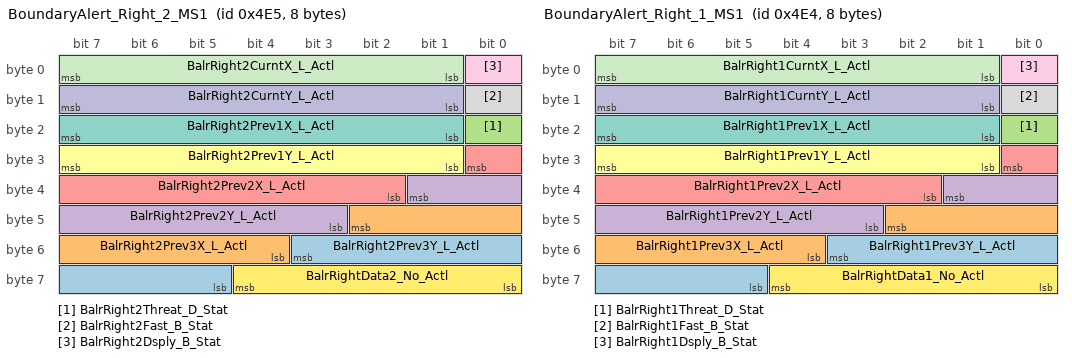
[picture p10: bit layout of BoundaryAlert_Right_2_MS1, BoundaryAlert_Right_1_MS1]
BO_ 1253 BoundaryAlert_Right_2_MS1: 8 SODR
 SG_ BalrRight2Prev3Y_L_Actl : 51|7@0+ (0.5,-32) [-32|31.5] "meter"  GWM,SODL
 SG_ BalrRight2Prev3X_L_Actl : 42|7@0+ (0.5,-32) [-32|31.5] "meter"  GWM,SODL
 SG_ BalrRight2Threat_D_Stat : 16|1@0+ (1,0) [0|1] "SED"  GWM,SODL
 SG_ BalrRight2Prev2Y_L_Actl : 33|7@0+ (0.5,-32) [-32|31.5] "meter"  GWM,SODL
 SG_ BalrRight2Prev2X_L_Actl : 24|7@0+ (0.5,-32) [-32|31.5] "meter"  GWM,SODL
 SG_ BalrRight2Prev1Y_L_Actl : 31|7@0+ (0.5,-32) [-32|31.5] "meter"  GWM,SODL
 SG_ BalrRight2Prev1X_L_Actl : 23|7@0+ (0.5,-32) [-32|31.5] "meter"  GWM,SODL
 SG_ BalrRight2Fast_B_Stat : 8|1@0+ (1,0) [0|1] "SED"  GWM,SODL
 SG_ BalrRight2Dsply_B_Stat : 0|1@0+ (1,0) [0|1] "SED"  GWM,SODL
 SG_ BalrRight2CurntY_L_Actl : 15|7@0+ (0.5,-32) [-32|31.5] "meter"  GWM,SODL
 SG_ BalrRight2CurntX_L_Actl : 7|7@0+ (0.5,-32) [-32|31.5] "meter"  GWM,SODL
 SG_ BalrRightData2_No_Actl : 60|5@0+ (1,0) [0|31] "unitless"  GWM,SODL

BO_ 1252 BoundaryAlert_Right_1_MS1: 8 SODR
 SG_ BalrRight1Prev3Y_L_Actl : 51|7@0+ (0.5,-32) [-32|31.5] "meter"  GWM,SODL
 SG_ BalrRight1Prev3X_L_Actl : 42|7@0+ (0.5,-32) [-32|31.5] "meter"  GWM,SODL
 SG_ BalrRight1Threat_D_Stat : 16|1@0+ (1,0) [0|1] "SED"  GWM,SODL
 SG_ BalrRight1Prev2Y_L_Actl : 33|7@0+ (0.5,-32) [-32|31.5] "meter"  GWM,SODL
 SG_ BalrRight1Prev2X_L_Actl : 24|7@0+ (0.5,-32) [-32|31.5] "meter"  GWM,SODL
 SG_ BalrRight1Prev1Y_L_Actl : 31|7@0+ (0.5,-32) [-32|31.5] "meter"  GWM,SODL
 SG_ BalrRight1Prev1X_L_Actl : 23|7@0+ (0.5,-32) [-32|31.5] "meter"  GWM,SODL
 SG_ BalrRight1Fast_B_Stat : 8|1@0+ (1,0) [0|1] "SED"  GWM,SODL
 SG_ BalrRight1Dsply_B_Stat : 0|1@0+ (1,0) [0|1] "SED"  GWM,SODL
 SG_ BalrRight1CurntY_L_Actl : 15|7@0+ (0.5,-32) [-32|31.5] "meter"  GWM,SODL
 SG_ BalrRight1CurntX_L_Actl : 7|7@0+ (0.5,-32) [-32|31.5] "meter"  GWM,SODL
 SG_ BalrRightData1_No_Actl : 60|5@0+ (1,0) [0|31] "unitless"  GWM,SODL

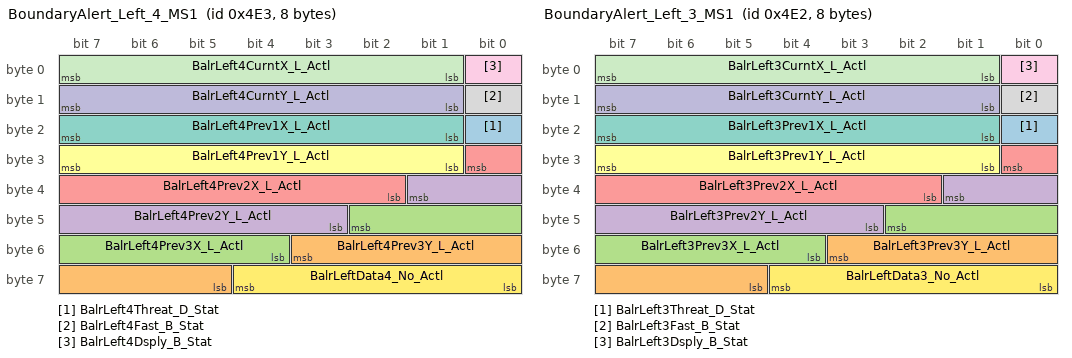
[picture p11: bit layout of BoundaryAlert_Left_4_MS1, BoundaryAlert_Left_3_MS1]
BO_ 1251 BoundaryAlert_Left_4_MS1: 8 SODL
 SG_ BalrLeft4Threat_D_Stat : 16|1@0+ (1,0) [0|1] "SED"  GWM,SODR
 SG_ BalrLeft4Prev3Y_L_Actl : 51|7@0+ (0.5,-32) [-32|31.5] "meter"  GWM,SODR
 SG_ BalrLeft4Prev3X_L_Actl : 42|7@0+ (0.5,-32) [-32|31.5] "meter"  GWM,SODR
 SG_ BalrLeft4Prev2Y_L_Actl : 33|7@0+ (0.5,-32) [-32|31.5] "meter"  GWM,SODR
 SG_ BalrLeft4Prev2X_L_Actl : 24|7@0+ (0.5,-32) [-32|31.5] "meter"  GWM,SODR
 SG_ BalrLeft4Prev1Y_L_Actl : 31|7@0+ (0.5,-32) [-32|31.5] "meter"  GWM,SODR
 SG_ BalrLeft4Prev1X_L_Actl : 23|7@0+ (0.5,-32) [-32|31.5] "meter"  GWM,SODR
 SG_ BalrLeft4Fast_B_Stat : 8|1@0+ (1,0) [0|1] "SED"  GWM,SODR
 SG_ BalrLeft4Dsply_B_Stat : 0|1@0+ (1,0) [0|1] "SED"  GWM,SODR
 SG_ BalrLeft4CurntY_L_Actl : 15|7@0+ (0.5,-32) [-32|31.5] "meter"  GWM,SODR
 SG_ BalrLeft4CurntX_L_Actl : 7|7@0+ (0.5,-32) [-32|31.5] "meter"  GWM,SODR
 SG_ BalrLeftData4_No_Actl : 60|5@0+ (1,0) [0|31] "unitless"  GWM,SODR

BO_ 1250 BoundaryAlert_Left_3_MS1: 8 SODL
 SG_ BalrLeft3Threat_D_Stat : 16|1@0+ (1,0) [0|1] "SED"  GWM,SODR
 SG_ BalrLeft3Prev3Y_L_Actl : 51|7@0+ (0.5,-32) [-32|31.5] "meter"  GWM,SODR
 SG_ BalrLeft3Prev3X_L_Actl : 42|7@0+ (0.5,-32) [-32|31.5] "meter"  GWM,SODR
 SG_ BalrLeft3Prev2Y_L_Actl : 33|7@0+ (0.5,-32) [-32|31.5] "meter"  GWM,SODR
 SG_ BalrLeft3Prev2X_L_Actl : 24|7@0+ (0.5,-32) [-32|31.5] "meter"  GWM,SODR
 SG_ BalrLeft3Prev1Y_L_Actl : 31|7@0+ (0.5,-32) [-32|31.5] "meter"  GWM,SODR
 SG_ BalrLeft3Prev1X_L_Actl : 23|7@0+ (0.5,-32) [-32|31.5] "meter"  GWM,SODR
 SG_ BalrLeft3Fast_B_Stat : 8|1@0+ (1,0) [0|1] "SED"  GWM,SODR
 SG_ BalrLeft3Dsply_B_Stat : 0|1@0+ (1,0) [0|1] "SED"  GWM,SODR
 SG_ BalrLeft3CurntY_L_Actl : 15|7@0+ (0.5,-32) [-32|31.5] "meter"  GWM,SODR
 SG_ BalrLeft3CurntX_L_Actl : 7|7@0+ (0.5,-32) [-32|31.5] "meter"  GWM,SODR
 SG_ BalrLeftData3_No_Actl : 60|5@0+ (1,0) [0|31] "unitless"  GWM,SODR

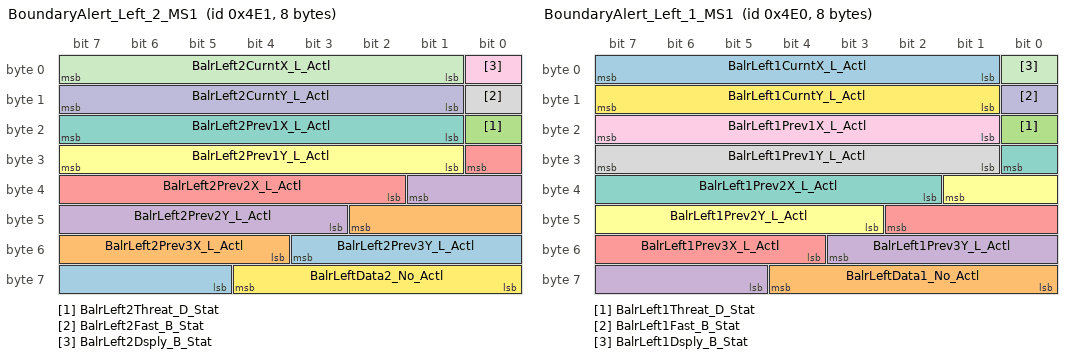
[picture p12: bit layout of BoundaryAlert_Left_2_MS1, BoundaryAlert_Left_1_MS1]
BO_ 1249 BoundaryAlert_Left_2_MS1: 8 SODL
 SG_ BalrLeft2Prev3Y_L_Actl : 51|7@0+ (0.5,-32) [-32|31.5] "meter"  GWM,SODR
 SG_ BalrLeft2Prev3X_L_Actl : 42|7@0+ (0.5,-32) [-32|31.5] "meter"  GWM,SODR
 SG_ BalrLeft2Threat_D_Stat : 16|1@0+ (1,0) [0|1] "SED"  GWM,SODR
 SG_ BalrLeft2Prev2Y_L_Actl : 33|7@0+ (0.5,-32) [-32|31.5] "meter"  GWM,SODR
 SG_ BalrLeft2Prev2X_L_Actl : 24|7@0+ (0.5,-32) [-32|31.5] "meter"  GWM,SODR
 SG_ BalrLeft2Prev1Y_L_Actl : 31|7@0+ (0.5,-32) [-32|31.5] "meter"  GWM,SODR
 SG_ BalrLeft2Prev1X_L_Actl : 23|7@0+ (0.5,-32) [-32|31.5] "meter"  GWM,SODR
 SG_ BalrLeft2Fast_B_Stat : 8|1@0+ (1,0) [0|1] "SED"  GWM,SODR
 SG_ BalrLeft2Dsply_B_Stat : 0|1@0+ (1,0) [0|1] "SED"  GWM,SODR
 SG_ BalrLeft2CurntY_L_Actl : 15|7@0+ (0.5,-32) [-32|31.5] "meter"  GWM,SODR
 SG_ BalrLeft2CurntX_L_Actl : 7|7@0+ (0.5,-32) [-32|31.5] "meter"  GWM,SODR
 SG_ BalrLeftData2_No_Actl : 60|5@0+ (1,0) [0|31] "unitless"  GWM,SODR

BO_ 1248 BoundaryAlert_Left_1_MS1: 8 SODL
 SG_ BalrLeft1CurntX_L_Actl : 7|7@0+ (0.5,-32) [-32|31.5] "meter"  GWM,SODR
 SG_ BalrLeftData1_No_Actl : 60|5@0+ (1,0) [0|31] "unitless"  GWM,SODR
 SG_ BalrLeft1Threat_D_Stat : 16|1@0+ (1,0) [0|1] "SED"  GWM,SODR
 SG_ BalrLeft1Prev3Y_L_Actl : 51|7@0+ (0.5,-32) [-32|31.5] "meter"  GWM,SODR
 SG_ BalrLeft1Prev3X_L_Actl : 42|7@0+ (0.5,-32) [-32|31.5] "meter"  GWM,SODR
 SG_ BalrLeft1Prev2Y_L_Actl : 33|7@0+ (0.5,-32) [-32|31.5] "meter"  GWM,SODR
 SG_ BalrLeft1Prev2X_L_Actl : 24|7@0+ (0.5,-32) [-32|31.5] "meter"  GWM,SODR
 SG_ BalrLeft1Prev1Y_L_Actl : 31|7@0+ (0.5,-32) [-32|31.5] "meter"  GWM,SODR
 SG_ BalrLeft1Prev1X_L_Actl : 23|7@0+ (0.5,-32) [-32|31.5] "meter"  GWM,SODR
 SG_ BalrLeft1Fast_B_Stat : 8|1@0+ (1,0) [0|1] "SED"  GWM,SODR
 SG_ BalrLeft1Dsply_B_Stat : 0|1@0+ (1,0) [0|1] "SED"  GWM,SODR
 SG_ BalrLeft1CurntY_L_Actl : 15|7@0+ (0.5,-32) [-32|31.5] "meter"  GWM,SODR

BO_ 1998 TesterPhysicalResSODR_MS1: 8 SODR
 SG_ TesterPhysicalResSODR : 7|64@0+ (1,0) [0|1.84467E+019] "unitless"  TSTR

BO_ 1996 TesterPhysicalResSODL_MS1: 8 SODL
 SG_ TesterPhysicalResSODL : 7|64@0+ (1,0) [0|1.84467E+019] "unitless"  TSTR

BO_ 1990 TesterPhysicalReqSODR_MS1: 8 TSTR
 SG_ TesterPhysicalReqSODR : 7|64@0+ (1,0) [0|1.84467E+019] "unitless"  SODR

BO_ 1988 TesterPhysicalReqSODL_MS1: 8 TSTR
 SG_ TesterPhysicalReqSODL : 7|64@0+ (1,0) [0|1.84467E+019] "unitless"  SODL

BO_ 798 GatewayData5_MS1: 8 GWM
 SG_ EmPrflNo_D_Rq_UB : 46|1@0+ (1,0) [0|1] "SED"  DDM
 SG_ EmPrflNo_D_Rq : 34|3@0+ (1,0) [0|7] "SED"  DDM
 SG_ EmPrflKeyAssoc_D_Rq_UB : 47|1@0+ (1,0) [0|1] "SED"  DDM
 SG_ EmPrflKeyAssoc_D_Rq : 37|3@0+ (1,0) [0|7] "SED"  DDM
 SG_ ExitNotClrRight_B_Stat_UB : 38|1@0+ (1,0) [0|1] "SED"  DCME,DCMF,DCMG,DCMH
 SG_ ExitNotClrLeft_B_Stat_UB : 39|1@0+ (1,0) [0|1] "SED"  DCME,DCMF,DCMG,DCMH
 SG_ ExitNotClrRight_B_Stat : 24|1@0+ (1,0) [0|1] "SED"  DCME,DCMF,DCMG,DCMH
 SG_ ExitNotClrLeft_B_Stat : 25|1@0+ (1,0) [0|1] "SED"  DCME,DCMF,DCMG,DCMH
 SG_ ClimtCool_D_RqPt_UB : 16|1@0+ (1,0) [0|1] "SED"  FCIM,HVAC_RCCM
 SG_ ClimtCool_D_RqPt : 27|2@0+ (1,0) [0|3] "SED"  FCIM,HVAC_RCCM
 SG_ PudSptLghtRight_D_Rq_UB : 2|1@0+ (1,0) [0|1] "SED"  DDM,PDM
 SG_ PudSptLghtLeft_D_Rq_UB : 3|1@0+ (1,0) [0|1] "SED"  DDM,PDM
 SG_ PudSptLghtRight_D_Rq : 5|2@0+ (1,0) [0|3] "SED"  DDM,PDM
 SG_ PwRnngBoardPoll_D_Stat_UB : 20|1@0+ (1,0) [0|1] "SED"  DDM,PDM,DSM
 SG_ PwRnngBoardPoll_D_Stat : 22|2@0+ (1,0) [0|3] "SED"  DDM,PDM,DSM
 SG_ AirCondRec_B_RqVehEl_UB : 18|1@0+ (1,0) [0|1] "SED"  HVAC_RCCM
 SG_ AirCondRec_B_RqVehEl : 19|1@0+ (1,0) [0|1] "SED"  HVAC_RCCM
 SG_ RmtCtl_D_Stat : 31|4@0+ (1,0) [0|15] "SED"  DDM,PDM
 SG_ RmtCtl_D_Stat_UB : 17|1@0+ (1,0) [0|1] "SED"  DDM,PDM
 SG_ PudSptLghtLeft_D_Rq : 7|2@0+ (1,0) [0|3] "SED"  DDM,PDM
 SG_ PoliceDmngLvl_D_Stat : 10|3@0+ (1,0) [0|7] "SED"  DDM,HVAC_RCCM,PDM
 SG_ VehWlcmFrwlMde_D_Stat_UB : 11|1@0+ (1,0) [0|1] "SED"  DDM,PDM,DCME,DCMF,DCMG,DCMH
 SG_ VehWlcmFrwl_D_Stat_UB : 12|1@0+ (1,0) [0|1] "SED"  DDM,PDM
 SG_ VehWlcmFrwlMde_D_Stat : 15|3@0+ (1,0) [0|7] "SED"  DDM,PDM,DCME,DCMF,DCMG,DCMH
 SG_ VehWlcmFrwl_D_Stat : 1|2@0+ (1,0) [0|3] "SED"  DDM,PDM
 SG_ PoliceDmngLvl_D_Stat_UB : 23|1@0+ (1,0) [0|1] "SED"  DDM,HVAC_RCCM,PDM

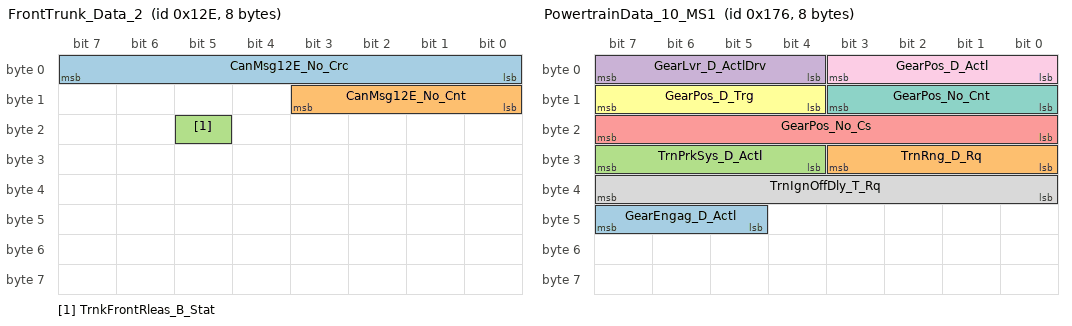
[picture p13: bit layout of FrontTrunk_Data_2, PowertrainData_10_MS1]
BO_ 302 FrontTrunk_Data_2: 8 GFM_FTRM
 SG_ CanMsg12E_No_Crc : 7|8@0+ (1,0) [0|255] "Unitless"  GWM
 SG_ CanMsg12E_No_Cnt : 11|4@0+ (1,0) [0|15] "Unitless"  GWM
 SG_ TrnkFrontRleas_B_Stat : 21|1@0+ (1,0) [0|1] "SED"  GWM

BO_ 374 PowertrainData_10_MS1: 8 GWM
 SG_ GearEngag_D_Actl : 47|3@0+ (1,0) [0|7] "SED"  GENERIC
 SG_ TrnRng_D_Rq : 27|4@0+ (1,0) [0|15] "SED"  GFM_FTRM
 SG_ TrnPrkSys_D_Actl : 31|4@0+ (1,0) [0|15] "SED"  GFM_FTRM
 SG_ GearLvr_D_ActlDrv : 7|4@0+ (1,0) [0|15] "SED"  GFM_FTRM
 SG_ GearPos_No_Cs : 23|8@0+ (1,0) [0|255] "unitless"  GFM_FTRM
 SG_ GearPos_D_Trg : 15|4@0+ (1,0) [0|15] "SED"  GFM_FTRM
 SG_ GearPos_No_Cnt : 11|4@0+ (1,0) [0|15] "unitless"  GFM_FTRM
 SG_ TrnIgnOffDly_T_Rq : 39|8@0+ (4,0) [0|1020] "ms"  GENERIC
 SG_ GearPos_D_Actl : 3|4@0+ (1,0) [0|15] "SED"  GFM_FTRM

BO_ 300 RollerShutterControlData: 8 MRCMA_RSCM
 SG_ TrukBedLght_B_Stat2 : 7|1@0+ (1,0) [0|1] "SED"  GWM

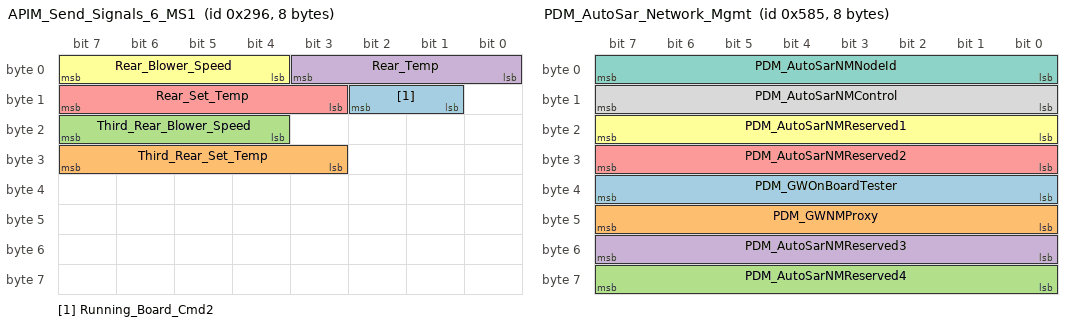
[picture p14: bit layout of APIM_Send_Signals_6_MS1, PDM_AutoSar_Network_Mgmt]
BO_ 662 APIM_Send_Signals_6_MS1: 8 GWM
 SG_ Running_Board_Cmd2 : 10|2@0+ (1,0) [0|3] "SED"  RBM
 SG_ Third_Rear_Set_Temp : 31|5@0+ (1,0) [0|31] "SED"  FCIM,HVAC_RCCM
 SG_ Third_Rear_Blower_Speed : 23|4@0+ (1,0) [0|15] "SED"  FCIM,HVAC_RCCM
 SG_ Rear_Temp : 3|4@0+ (1,0) [0|15] "SED"  FCIM,HVAC_RCCM
 SG_ Rear_Set_Temp : 15|5@0+ (1,0) [0|31] "SED"  FCIM,HVAC_RCCM
 SG_ Rear_Blower_Speed : 7|4@0+ (1,0) [0|15] "SED"  FCIM,HVAC_RCCM

BO_ 670 Driver_Dr_Stat2: 8 DDM
 SG_ DrHandleOuterRl_D_Stat : 4|3@0+ (1,0) [0|7] "SED"  GWM
 SG_ DrHandleOuterFl_D_Stat : 7|3@0+ (1,0) [0|7] "SED"  GWM

BO_ 669 Pass_Dr_Stat2: 8 PDM
 SG_ DrHandleOuterRr_D_Stat : 4|3@0+ (1,0) [0|7] "SED"  GWM
 SG_ DrHandleOuterFr_D_Stat : 7|3@0+ (1,0) [0|7] "SED"  GWM

BO_ 2612224065 PARSEDPushSCMJtoGWM_ECG: 8 SCMJ
 SG_ PARSEDPushSCMJtoGWM_ECG : 7|29@0+ (1,0) [0|536870911] "unitless"  GWM

BO_ 2612069592 PARSEDPushFcGWMtoSCMJ: 8 GWM
 SG_ PARSEDPushFcGWM_ECGtoSCMJ : 7|29@0+ (1,0) [0|536870911] "unitless"  SCMJ

BO_ 1413 PDM_AutoSar_Network_Mgmt: 8 PDM
 SG_ PDM_GWOnBoardTester : 39|8@0+ (1,0) [0|255] "unitless"  GWM
 SG_ PDM_GWNMProxy : 47|8@0+ (1,0) [0|255] "unitless"  GWM
 SG_ PDM_AutoSarNMReserved4 : 63|8@0+ (1,0) [0|255] "unitless"  GWM
 SG_ PDM_AutoSarNMReserved3 : 55|8@0+ (1,0) [0|255] "unitless"  GWM
 SG_ PDM_AutoSarNMReserved2 : 31|8@0+ (1,0) [0|255] "unitless"  GWM
 SG_ PDM_AutoSarNMReserved1 : 23|8@0+ (1,0) [0|255] "unitless"  GWM
 SG_ PDM_AutoSarNMNodeId : 7|8@0+ (1,0) [0|255] "unitless"  GWM
 SG_ PDM_AutoSarNMControl : 15|8@0+ (1,0) [0|255] "unitless"  GWM

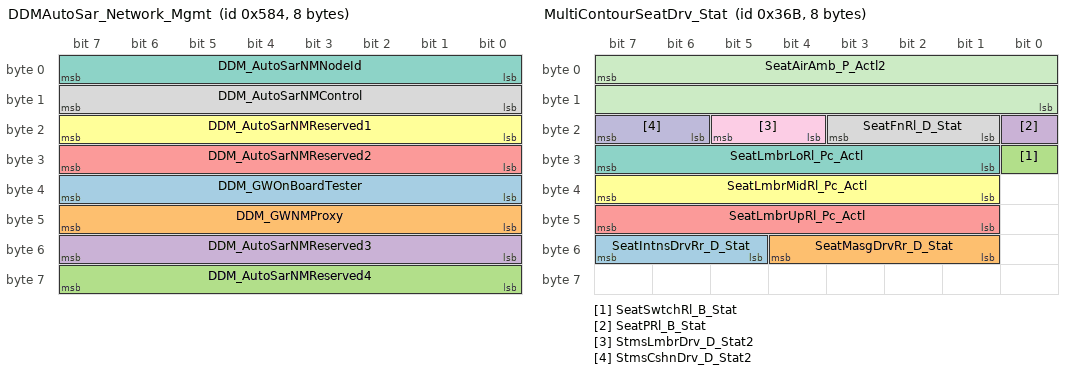
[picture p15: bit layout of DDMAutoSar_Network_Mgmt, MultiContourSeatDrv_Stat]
BO_ 1412 DDMAutoSar_Network_Mgmt: 8 DDM
 SG_ DDM_GWOnBoardTester : 39|8@0+ (1,0) [0|255] "unitless"  GWM
 SG_ DDM_GWNMProxy : 47|8@0+ (1,0) [0|255] "unitless"  GWM
 SG_ DDM_AutoSarNMReserved4 : 63|8@0+ (1,0) [0|255] "unitless"  GWM
 SG_ DDM_AutoSarNMReserved3 : 55|8@0+ (1,0) [0|255] "unitless"  GWM
 SG_ DDM_AutoSarNMReserved2 : 31|8@0+ (1,0) [0|255] "unitless"  GWM
 SG_ DDM_AutoSarNMReserved1 : 23|8@0+ (1,0) [0|255] "unitless"  GWM
 SG_ DDM_AutoSarNMNodeId : 7|8@0+ (1,0) [0|255] "unitless"  GWM
 SG_ DDM_AutoSarNMControl : 15|8@0+ (1,0) [0|255] "unitless"  GWM

BO_ 1079 GatewayData2_MS1: 8 GWM
 SG_ ApaMde_D_Stat_UB : 25|1@0+ (1,0) [0|1] "SED"  SODR,SODL
 SG_ ApaMde_D_Stat : 39|3@0+ (1,0) [0|7] "SED"  SODR,SODL
 SG_ TrlrAidEnbl_D2_Stat_UB : 58|1@0+ (1,0) [0|1] "SED"  TRM
 SG_ TrlrAidEnbl_D2_Stat : 61|3@0+ (1,0) [0|7] "SED"  TRM
 SG_ PoliceAux4Swtch_B_Stat_UB : 62|1@0+ (1,0) [0|1] "SED"  TRM
 SG_ PoliceAux3Swtch_B_Stat_UB : 63|1@0+ (1,0) [0|1] "SED"  TRM
 SG_ PoliceAux2Swtch_B_Stat_UB : 48|1@0+ (1,0) [0|1] "SED"  TRM
 SG_ PoliceAux1Swtch_B_Stat_UB : 49|1@0+ (1,0) [0|1] "SED"  TRM
 SG_ PoliceAux4Swtch_B_Stat : 50|1@0+ (1,0) [0|1] "SED"  TRM
 SG_ PoliceAux3Swtch_B_Stat : 51|1@0+ (1,0) [0|1] "SED"  TRM
 SG_ PoliceAux2Swtch_B_Stat : 52|1@0+ (1,0) [0|1] "SED"  TRM
 SG_ PoliceAux1Swtch_B_Stat : 40|1@0+ (1,0) [0|1] "SED"  TRM
 SG_ GenericSwtch3_No_Actl_UB : 41|1@0+ (1,0) [0|1] "SED"  TRM
 SG_ GenericSwtch3_No_Actl : 55|3@0+ (1,0) [0|7] "unitless"  TRM
 SG_ GenericSwtch2_No_Actl_UB : 32|1@0+ (1,0) [0|1] "SED"  TRM
 SG_ GenericSwtch2_No_Actl : 44|3@0+ (1,0) [0|7] "unitless"  TRM
 SG_ GenericSwtch1_No_Actl_UB : 33|1@0+ (1,0) [0|1] "SED"  TRM
 SG_ GenericSwtch1_No_Actl : 47|3@0+ (1,0) [0|7] "unitless"  TRM
 SG_ RbaSys_D_Stat_UB : 8|1@0+ (1,0) [0|1] "SED"  SODR,SODL
 SG_ RbaSys_D_Stat : 4|2@0+ (1,0) [0|3] "SED"  SODR,SODL
 SG_ HybMdeStat_D_Dsply_UB : 9|1@0+ (1,0) [0|1] "SED"  FCIM,HVAC_RCCM
 SG_ Rba_D_Stat : 12|2@0+ (1,0) [0|3] "SED"  SODR,SODL
 SG_ Rba_D_Stat_UB : 10|1@0+ (1,0) [0|1] "SED"  SODR,SODL
 SG_ BalrMde_D_Rq_UB : 20|1@0+ (1,0) [0|1] "SED"  SODR,SODL
 SG_ BalrSwtch_D_Stat_UB : 17|1@0+ (1,0) [0|1] "SED"  SODR,SODL
 SG_ BalrMde_D_Rq : 22|2@0+ (1,0) [0|3] "SED"  SODR,SODL
 SG_ ChrgGoTTouchEnbl_B_Rq : 1|1@0+ (1,0) [0|1] "SED"  FCIM,HVAC_RCCM
 SG_ ChrgGoTExtHtrEnbl_B_Rq : 2|1@0+ (1,0) [0|1] "SED"  FCIM,HVAC_RCCM
 SG_ ChrgGoTTouchEnbl_B_Rq_UB : 23|1@0+ (1,0) [0|1] "SED"  FCIM,HVAC_RCCM
 SG_ ChrgGoTExtHtrEnbl_B_Rq_UB : 0|1@0+ (1,0) [0|1] "SED"  FCIM,HVAC_RCCM
 SG_ LcwaAlrtRight_B_Rq_UB : 34|1@0+ (1,0) [0|1] "SED"  SODR
 SG_ LcwaAlrtLeft_B_Rq_UB : 36|1@0+ (1,0) [0|1] "SED"  SODL
 SG_ LcwaAlrtRight_B_Rq : 35|1@0+ (1,0) [0|1] "SED"  SODR
 SG_ LcwaAlrtLeft_B_Rq : 24|1@0+ (1,0) [0|1] "SED"  SODL
 SG_ ApaSteScanMde_D_Stat : 15|2@0+ (1,0) [0|3] "SED"  SODR,SODL
 SG_ ApaSteScanMde_D_Stat_UB : 13|1@0+ (1,0) [0|1] "SED"  SODR,SODL
 SG_ BattTracClimtDis_B_Stat_UB : 56|1@0+ (1,0) [0|1] "SED"  HVAC_RCCM
 SG_ BattTracClimtDis_B_Stat : 57|1@0+ (1,0) [0|1] "SED"  HVAC_RCCM
 SG_ BalrSwtch_D_Stat : 19|2@0+ (1,0) [0|3] "SED"  SODR,SODL
 SG_ TrlrAidMsgTxt_D2_Rq_UB : 16|1@0+ (1,0) [0|1] "SED"  TRM
 SG_ TrlrAidMsgTxt_D2_Rq : 31|6@0+ (1,0) [0|63] "SED"  TRM
 SG_ HybMdeStat_D_Dsply : 7|3@0+ (1,0) [0|7] "SED"  FCIM,HVAC_RCCM

BO_ 875 MultiContourSeatDrv_Stat: 8 SCMC
 SG_ SeatIntnsDrvRr_D_Stat : 55|3@0+ (1,0) [0|7] "SED"  GWM
 SG_ SeatMasgDrvRr_D_Stat : 52|4@0+ (1,0) [0|15] "SED"  GWM
 SG_ SeatSwtchRl_B_Stat : 24|1@0+ (1,0) [0|1] "SED"  GWM
 SG_ SeatPRl_B_Stat : 16|1@0+ (1,0) [0|1] "SED"  GWM
 SG_ SeatLmbrUpRl_Pc_Actl : 47|7@0+ (1,0) [0|127] "Percent"  GWM
 SG_ SeatLmbrMidRl_Pc_Actl : 39|7@0+ (1,0) [0|127] "Percent"  GWM
 SG_ SeatLmbrLoRl_Pc_Actl : 31|7@0+ (1,0) [0|127] "Percent"  GWM
 SG_ SeatFnRl_D_Stat : 19|3@0+ (1,0) [0|7] "SED"  GWM
 SG_ StmsLmbrDrv_D_Stat2 : 21|2@0+ (1,0) [0|3] "SED"  GWM,SFMA
 SG_ StmsCshnDrv_D_Stat2 : 23|2@0+ (1,0) [0|3] "SED"  GWM,SFMA
 SG_ SeatAirAmb_P_Actl2 : 7|16@0+ (0.01,0) [0|655.35] "kilopascal"  SCMD,GWM

BO_ 1797 TesterPhysicalReqSFMB: 8 TSTR
 SG_ TesterPhysicalReqSFMB : 7|64@0+ (1,0) [0|1.84467E+019] "unitless"  SFMB

BO_ 941 Extended_CTA_Data_Right: 8 SODR
 SG_ CtaTrgtRightY_V_Actl : 55|16@0+ (0.001526,-50) [-50|50.00641] "meters/sec"  SODL
 SG_ CtaTrgtRightY_L_Actl : 23|16@0+ (0.0030519,-100) [-100|100.0062665] "meter"  SODL
 SG_ CtaTrgtRightX_V_Actl : 39|16@0+ (0.001526,-50) [-50|50.00641] "meters/sec"  SODL
 SG_ CtaTrgtRightX_L_Actl : 7|16@0+ (0.0021363,-120) [-120|20.0024205] "meter"  SODL

BO_ 940 Extended_CTA_Data_Left: 8 SODL
 SG_ CtaTrgtLeftY_V_Actl : 55|16@0+ (0.001526,-50) [-50|50.00641] "meters/sec"  GWM,SODR
 SG_ CtaTrgtLeftY_L_Actl : 23|16@0+ (0.0030519,-100) [-100|100.0062665] "meter"  GWM,SODR
 SG_ CtaTrgtLeftX_V_Actl : 39|16@0+ (0.001526,-50) [-50|50.00641] "meters/sec"  GWM,SODR
 SG_ CtaTrgtLeftX_L_Actl : 7|16@0+ (0.0021363,-120) [-120|20.0024205] "meter"  GWM,SODR

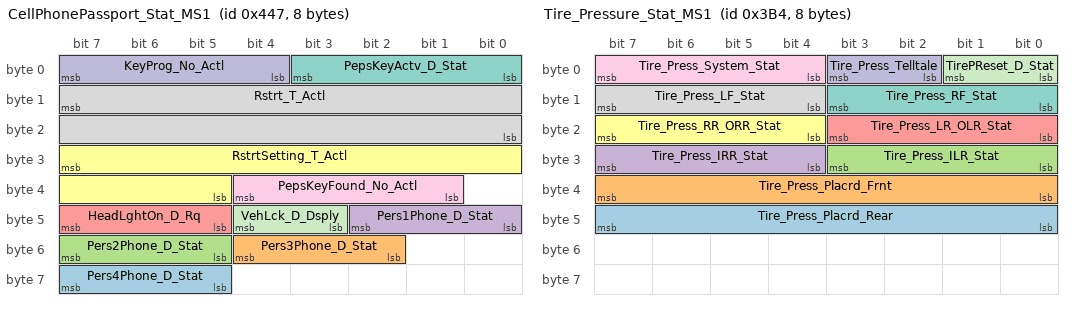
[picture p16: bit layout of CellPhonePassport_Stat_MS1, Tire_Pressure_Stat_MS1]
BO_ 1095 CellPhonePassport_Stat_MS1: 8 GWM
 SG_ Pers4Phone_D_Stat : 63|3@0+ (1,0) [0|7] "SED"  GENERIC
 SG_ Pers3Phone_D_Stat : 52|3@0+ (1,0) [0|7] "SED"  GENERIC
 SG_ Pers2Phone_D_Stat : 55|3@0+ (1,0) [0|7] "SED"  GENERIC
 SG_ Pers1Phone_D_Stat : 42|3@0+ (1,0) [0|7] "SED"  GENERIC
 SG_ HeadLghtOn_D_Rq : 47|3@0+ (1,0) [0|7] "SED"  BCMB_ALCM
 SG_ RstrtSetting_T_Actl : 31|11@0+ (1,0) [0|2047] "second"  RSM
 SG_ PepsKeyActv_D_Stat : 3|4@0+ (1,0) [0|15] "SED"  GENERIC
 SG_ Rstrt_T_Actl : 15|16@0+ (1,0) [0|65535] "seconds"  RSM
 SG_ PepsKeyFound_No_Actl : 36|4@0+ (1,0) [0|15] "unitless"  GENERIC
 SG_ KeyProg_No_Actl : 7|4@0+ (1,0) [0|15] "unitless"  GENERIC
 SG_ VehLck_D_Dsply : 44|2@0+ (1,0) [0|3] "SED"  DCME,DCMF,DCMG,DCMH

BO_ 948 Tire_Pressure_Stat_MS1: 8 GWM
 SG_ Tire_Press_Placrd_Rear : 47|8@0+ (1,0) [0|255] "pounds/inch^2"  GENERIC
 SG_ Tire_Press_Placrd_Frnt : 39|8@0+ (1,0) [0|255] "pounds/inch^2"  GENERIC
 SG_ Tire_Press_ILR_Stat : 27|4@0+ (1,0) [0|15] "SED"  RTM
 SG_ Tire_Press_IRR_Stat : 31|4@0+ (1,0) [0|15] "SED"  RTM
 SG_ Tire_Press_LR_OLR_Stat : 19|4@0+ (1,0) [0|15] "SED"  RTM
 SG_ Tire_Press_RR_ORR_Stat : 23|4@0+ (1,0) [0|15] "SED"  RTM
 SG_ Tire_Press_RF_Stat : 11|4@0+ (1,0) [0|15] "SED"  RTM
 SG_ Tire_Press_LF_Stat : 15|4@0+ (1,0) [0|15] "SED"  RTM
 SG_ Tire_Press_System_Stat : 7|4@0+ (1,0) [0|15] "SED"  RTM
 SG_ Tire_Press_Telltale : 3|2@0+ (1,0) [0|3] "SED"  RTM
 SG_ TirePReset_D_Stat : 1|2@0+ (1,0) [0|3] "Discrete"  RTM

BO_ 1361 BCMB_Network_MgmtM: 8 BCMB_ABM
 SG_ BCMB_Network_Mgmt : 7|64@0+ (1,0) [0|1.84467440737096E+019] "unitless"  GENERIC

BO_ 840 FoH_Day_Req_MS1: 8 GWM
 SG_ FohAddHeater_D_Rq : 9|2@0+ (1,0) [0|3] "SED"  SOBDMD_AHCM_FOH
 SG_ FohStrtDateYr_No_Rq : 39|8@0+ (1,2000) [2000|2255] "year"  SOBDMD_AHCM_FOH
 SG_ FohStrtDateDay_No_Rq : 23|16@0+ (1,0) [0|65535] "julian day"  SOBDMD_AHCM_FOH
 SG_ FohT2Friday_T_Rq : 0|1@0+ (1,0) [0|1] "SED"  SOBDMD_AHCM_FOH
 SG_ FohT1Friday_T_Rq : 7|1@0+ (1,0) [0|1] "SED"  SOBDMD_AHCM_FOH
 SG_ FohT2Wednesday_T_Rq : 10|1@0+ (1,0) [0|1] "SED"  SOBDMD_AHCM_FOH
 SG_ FohT2Tuesday_T_Rq : 11|1@0+ (1,0) [0|1] "SED"  SOBDMD_AHCM_FOH
 SG_ FohT2Thursday_T_Rq : 12|1@0+ (1,0) [0|1] "SED"  SOBDMD_AHCM_FOH
 SG_ FohT2Sunday_T_Rq : 13|1@0+ (1,0) [0|1] "SED"  SOBDMD_AHCM_FOH
 SG_ FohT2Saturday_T_Rq : 14|1@0+ (1,0) [0|1] "SED"  SOBDMD_AHCM_FOH
 SG_ FohT2Monday_T_Rq : 15|1@0+ (1,0) [0|1] "SED"  SOBDMD_AHCM_FOH
 SG_ FohT1Wednesday_T_Rq : 1|1@0+ (1,0) [0|1] "SED"  SOBDMD_AHCM_FOH
 SG_ FohT1Tuesday_T_Rq : 2|1@0+ (1,0) [0|1] "SED"  SOBDMD_AHCM_FOH
 SG_ FohT1Thursday_T_Rq : 3|1@0+ (1,0) [0|1] "SED"  SOBDMD_AHCM_FOH
 SG_ FohT1Sunday_T_Rq : 4|1@0+ (1,0) [0|1] "SED"  SOBDMD_AHCM_FOH
 SG_ FohT1Saturday_T_Rq : 5|1@0+ (1,0) [0|1] "SED"  SOBDMD_AHCM_FOH
 SG_ FohT1Monday_T_Rq : 6|1@0+ (1,0) [0|1] "SED"  SOBDMD_AHCM_FOH

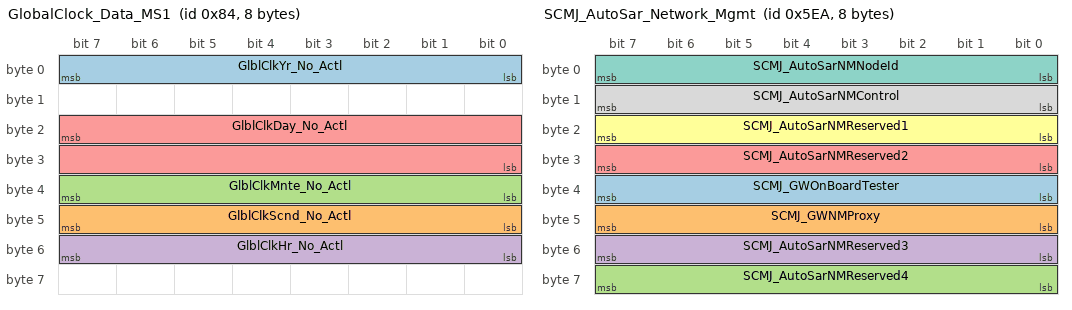
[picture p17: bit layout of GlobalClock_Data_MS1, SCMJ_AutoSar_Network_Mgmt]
BO_ 132 GlobalClock_Data_MS1: 8 GWM
 SG_ GlblClkYr_No_Actl : 7|8@0+ (1,2000) [2000|2255] "year"  TRM,SOBDMD_AHCM_FOH
 SG_ GlblClkScnd_No_Actl : 47|8@0+ (1,0) [0|255] "second"  TRM,SOBDMD_AHCM_FOH
 SG_ GlblClkMnte_No_Actl : 39|8@0+ (1,0) [0|255] "minute"  TRM,SOBDMD_AHCM_FOH
 SG_ GlblClkHr_No_Actl : 55|8@0+ (1,0) [0|255] "hour"  TRM,SOBDMD_AHCM_FOH
 SG_ GlblClkDay_No_Actl : 23|16@0+ (1,0) [0|65535] "julian day"  TRM,SOBDMD_AHCM_FOH

BO_ 1796 TesterPhysicalReqSFMA: 8 TSTR
 SG_ TesterPhysicalReqSFMA : 7|64@0+ (1,0) [0|1.84467E+019] "unitless"  SFMA

BO_ 1927 TesterPhysicalReqSCMJ: 8 TSTR
 SG_ TesterPhysicalReqSCMJ : 7|64@0+ (1,0) [0|1.84467E+019] "unitless"  SCMJ

BO_ 1935 TesterPhysicalResSCMJ: 8 SCMJ
 SG_ TesterPhysicalResSCMJ : 7|64@0+ (1,0) [0|1.84467E+019] "unitless"  TSTR

BO_ 1514 SCMJ_AutoSar_Network_Mgmt: 8 SCMJ
 SG_ SCMJ_GWOnBoardTester : 39|8@0+ (1,0) [0|255] "unitless"  GWM
 SG_ SCMJ_GWNMProxy : 47|8@0+ (1,0) [0|255] "unitless"  GWM
 SG_ SCMJ_AutoSarNMReserved4 : 63|8@0+ (1,0) [0|255] "unitless"  GWM
 SG_ SCMJ_AutoSarNMReserved3 : 55|8@0+ (1,0) [0|255] "unitless"  GWM
 SG_ SCMJ_AutoSarNMReserved2 : 31|8@0+ (1,0) [0|255] "unitless"  GWM
 SG_ SCMJ_AutoSarNMReserved1 : 23|8@0+ (1,0) [0|255] "unitless"  GWM
 SG_ SCMJ_AutoSarNMNodeId : 7|8@0+ (1,0) [0|255] "unitless"  GWM
 SG_ SCMJ_AutoSarNMControl : 15|8@0+ (1,0) [0|255] "unitless"  GWM

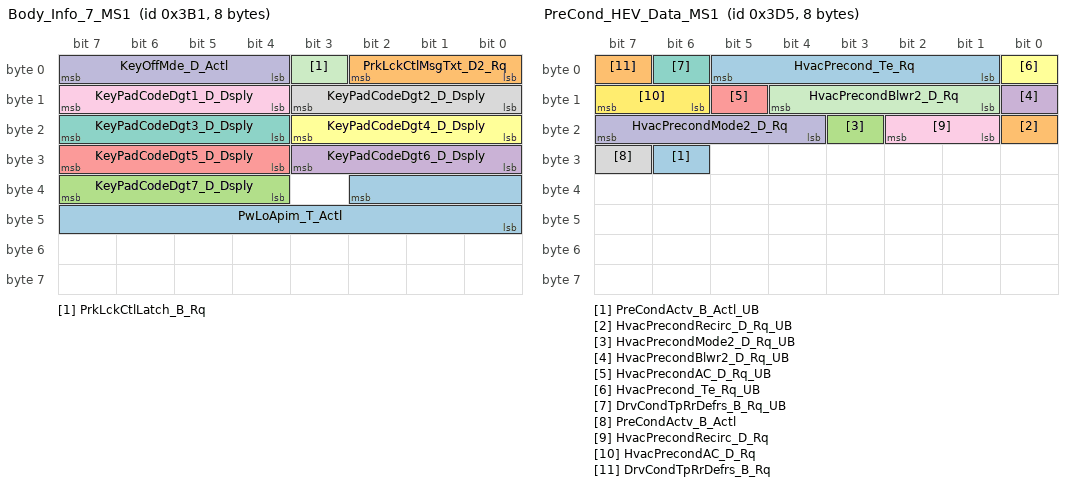
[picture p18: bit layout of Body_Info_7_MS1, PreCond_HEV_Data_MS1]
BO_ 945 Body_Info_7_MS1: 8 GWM
 SG_ PwLoApim_T_Actl : 34|11@0+ (1,0) [0|2047] "minute"  GENERIC
 SG_ PrkLckCtlMsgTxt_D2_Rq : 2|3@0+ (1,0) [0|7] "SED"  GENERIC
 SG_ KeyPadCodeDgt7_D_Dsply : 39|4@0+ (1,0) [0|15] "SED"  GENERIC
 SG_ KeyPadCodeDgt6_D_Dsply : 27|4@0+ (1,0) [0|15] "SED"  GENERIC
 SG_ KeyPadCodeDgt5_D_Dsply : 31|4@0+ (1,0) [0|15] "SED"  GENERIC
 SG_ KeyPadCodeDgt4_D_Dsply : 19|4@0+ (1,0) [0|15] "SED"  GENERIC
 SG_ KeyPadCodeDgt3_D_Dsply : 23|4@0+ (1,0) [0|15] "SED"  GENERIC
 SG_ KeyPadCodeDgt2_D_Dsply : 11|4@0+ (1,0) [0|15] "SED"  GENERIC
 SG_ KeyPadCodeDgt1_D_Dsply : 15|4@0+ (1,0) [0|15] "SED"  GENERIC
 SG_ KeyOffMde_D_Actl : 7|4@0+ (1,0) [0|15] "SED"  SCMB_PSM,GFM_FTRM,PDM,RTM,BCMB_ABM,BCMB_ALCM,BCMB_CAPM,DCME,DCMF,DCMG,DCMH,DDM,DSM,HVAC_RCCM,RBM,RGTM,RHVAC
 SG_ PrkLckCtlLatch_B_Rq : 3|1@0+ (1,0) [0|1] "SED"  GENERIC

BO_ 1804 TesterPhysicalResSFMA: 8 SFMA
 SG_ TesterPhysicalResSFMA : 7|64@0+ (1,0) [0|1.84467E+019] "unitless"  TSTR

BO_ 981 PreCond_HEV_Data_MS1: 8 GWM
 SG_ PreCondActv_B_Actl_UB : 30|1@0+ (1,0) [0|1] "SED"  HVAC_RCCM,GENERIC
 SG_ HvacPrecondRecirc_D_Rq_UB : 16|1@0+ (1,0) [0|1] "SED"  FCIM,GENERIC,HVAC_RCCM
 SG_ HvacPrecondMode2_D_Rq_UB : 19|1@0+ (1,0) [0|1] "SED"  FCIM,GENERIC,HVAC_RCCM
 SG_ HvacPrecondBlwr2_D_Rq_UB : 8|1@0+ (1,0) [0|1] "SED"  FCIM,HVAC_RCCM,GENERIC
 SG_ HvacPrecondAC_D_Rq_UB : 13|1@0+ (1,0) [0|1] "SED"  FCIM,GENERIC,HVAC_RCCM
 SG_ HvacPrecond_Te_Rq_UB : 0|1@0+ (1,0) [0|1] "SED"  FCIM,GENERIC,HVAC_RCCM
 SG_ DrvCondTpRrDefrs_B_Rq_UB : 6|1@0+ (1,0) [0|1] "SED"  FCIM,HVAC_RCCM,GENERIC
 SG_ PreCondActv_B_Actl : 31|1@0+ (1,0) [0|1] "SED"  GENERIC,HVAC_RCCM
 SG_ HvacPrecondRecirc_D_Rq : 18|2@0+ (1,0) [0|3] "SED"  FCIM,GENERIC,HVAC_RCCM
 SG_ HvacPrecondMode2_D_Rq : 23|4@0+ (1,0) [0|15] "SED"  FCIM,GENERIC,HVAC_RCCM
 SG_ HvacPrecondBlwr2_D_Rq : 12|4@0+ (1,0) [0|15] "SED"  FCIM,GENERIC,HVAC_RCCM
 SG_ HvacPrecondAC_D_Rq : 15|2@0+ (1,0) [0|3] "SED"  FCIM,GENERIC,HVAC_RCCM
 SG_ HvacPrecond_Te_Rq : 5|5@0+ (0.5,14.5) [14.5|30] "deg C"  FCIM,GENERIC,HVAC_RCCM
 SG_ DrvCondTpRrDefrs_B_Rq : 7|1@0+ (1,0) [0|1] "SED"  FCIM,HVAC_RCCM,GENERIC

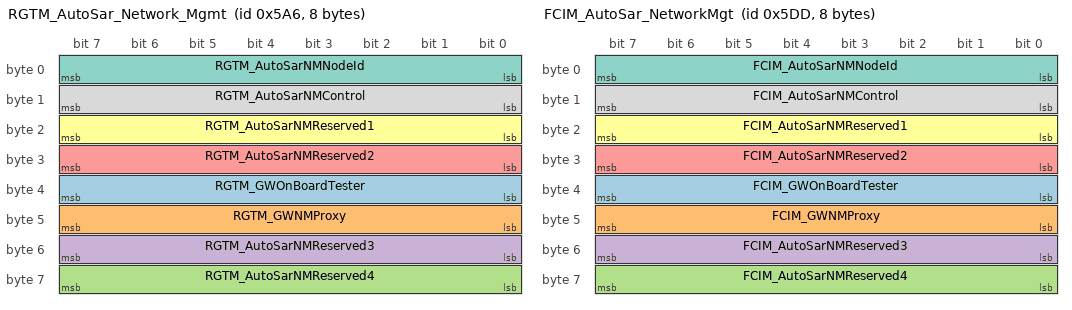
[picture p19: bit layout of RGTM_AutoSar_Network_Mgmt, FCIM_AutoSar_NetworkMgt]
BO_ 1446 RGTM_AutoSar_Network_Mgmt: 8 RGTM
 SG_ RGTM_GWOnBoardTester : 39|8@0+ (1,0) [0|255] "unitless"  DDM,GWM
 SG_ RGTM_GWNMProxy : 47|8@0+ (1,0) [0|255] "unitless"  DDM,GWM
 SG_ RGTM_AutoSarNMReserved4 : 63|8@0+ (1,0) [0|255] "unitless"  DDM,GWM
 SG_ RGTM_AutoSarNMReserved3 : 55|8@0+ (1,0) [0|255] "unitless"  DDM,GWM
 SG_ RGTM_AutoSarNMReserved2 : 31|8@0+ (1,0) [0|255] "unitless"  DDM,GWM
 SG_ RGTM_AutoSarNMReserved1 : 23|8@0+ (1,0) [0|255] "unitless"  DDM,GWM
 SG_ RGTM_AutoSarNMNodeId : 7|8@0+ (1,0) [0|255] "unitless"  DDM,GWM
 SG_ RGTM_AutoSarNMControl : 15|8@0+ (1,0) [0|255] "unitless"  DDM,GWM

BO_ 1898 TesterPhysicalResDCMF: 8 DCMF
 SG_ TesterPhysicalResDCMF : 7|64@0+ (1,0) [0|1.84467E+019] "unitless"  TSTR

BO_ 1959 TesterPhysicalReqFCIM: 8 TSTR
 SG_ TesterPhysicalReqFCIM : 7|64@0+ (1,0) [0|1.84467E+019] "unitless"  FCIM

BO_ 1967 TesterPhysicalResFCIM: 8 FCIM
 SG_ TesterPhysicalResFCIM : 7|64@0+ (1,0) [0|1.84467E+019] "unitless"  TSTR

BO_ 1501 FCIM_AutoSar_NetworkMgt: 8 FCIM
 SG_ FCIM_GWOnBoardTester : 39|8@0+ (1,0) [0|255] "unitless"  GWM
 SG_ FCIM_GWNMProxy : 47|8@0+ (1,0) [0|255] "unitless"  GWM
 SG_ FCIM_AutoSarNMReserved4 : 63|8@0+ (1,0) [0|255] "unitless"  GWM
 SG_ FCIM_AutoSarNMReserved3 : 55|8@0+ (1,0) [0|255] "unitless"  GWM
 SG_ FCIM_AutoSarNMReserved2 : 31|8@0+ (1,0) [0|255] "unitless"  GWM
 SG_ FCIM_AutoSarNMReserved1 : 23|8@0+ (1,0) [0|255] "unitless"  GWM
 SG_ FCIM_AutoSarNMNodeId : 7|8@0+ (1,0) [0|255] "unitless"  GWM
 SG_ FCIM_AutoSarNMControl : 15|8@0+ (1,0) [0|255] "unitless"  GWM

BO_TX_BU_ 1189 : GWM,RBM;
BO_TX_BU_ 1361 : BCMB_ALCM,BCMB_AUXM,BCMB_CAPM,BCMB_ABM;
CM_ SG_ 674 RearAudioCtlLck_D_Stat "RACLockout_St";
CM_ SG_ 674 RACM_SetVolume "Object CAN Button Strategy.BCP_Button_Press.SetVolume";
CM_ SG_ 674 RACM_Coding_BtnID_D "Object InputControlInterface ICI ButtonCoding_D
Object InputControlInterface ICI ButtonID_D";
CM_ SG_ 674 RACM_Coding_BtnID_C "Object InputControlInterface.ICI ButtonCoding_C
Object InputControlInterface.ICI ButtonID_C";
CM_ SG_ 674 RACM_Coding_BtnID_B "Object InputControlInterface ICI ButtonCoding_B
Object InputControlInterface.ICI ButtonID_B";
CM_ SG_ 674 RACM_Coding_BtnID_A "Object InputControlInterface ICI ButtonCoding_A
Object InputControlInterface.ICI ButtonID A";
CM_ SG_ 674 RACM_BtnID_D "Object InputControlInterface ICI ButtonID_D... 0xFF: Inactive";
CM_ SG_ 674 RACM_BtnID_C "Object InputControlInterface ICI ButtonID_D... 0xFF: Inactive";
CM_ SG_ 674 RACM_BtnID_B "Object InputControlInterface ICI ButtonID_D... 0xFF: Inactive";
CM_ SG_ 674 RACM_BtnID_A "Object InputControlInterface ICI ButtonID_D... 0xFF: Inactive";
CM_ SG_ 1075 ACU_RadioSeekMode2_St "Object Tuner.RadioSeekMode2";
CM_ SG_ 1075 ACU_CurrTUBand_St "Object.Tuner.CurrentTUBand";
CM_ SG_ 1075 ACU_CurrentFreq_St "Object Tuner.CurrentFreq

AM: Freq = 153+ Offset kHz.
Offset 0..1557 

FM: Freq = 76+ Offset*0.05 MHz. Offset 0..640
Selected tuned band determine frequency (kHz or MHz).";
CM_ SG_ 1166 DrLatchCntRr_No_Actl "Rolling counts indicate fresh data (DrLatchCntxx) are updated each time new data is sent from a latch to BCM thru the GW. UBs not required.";
CM_ SG_ 1165 DrLatchCntRl_No_Actl "Rolling counts indicate fresh data (DrLatchCntxx) are updated each time new data is sent from a latch to BCM thru the GW. UBs not required.";
CM_ SG_ 1164 DrLatchCntFr_No_Actl "Rolling counts indicate fresh data (DrLatchCntxx) are updated each time new data is sent from a latch to BCM thru the GW. UBs not required.";
CM_ SG_ 1163 DrLatchCntFl_No_Actl "Rolling counts indicate fresh data (DrLatchCntxx) are updated each time new data is sent from a latch to BCM thru the GW. UBs not required.";
CM_ SG_ 1162 MemDrvDeny_B_StatCapm "Updated to 1 bit for CGEA, Not backwards compatible";
CM_ SG_ 978 CnvtTopRngOpen_B_Stat "Signal not transmitted on gas and HEV variants.";
CM_ SG_ 978 CnvtTopRngClose_B_Stat "Signal not transmitted on gas and HEV variants.";
CM_ SG_ 977 CnvtTopSleepActv_B_Rq "Signal not transmitted on gas and HEV variants.";
CM_ SG_ 977 CnvtTopBrkActv_B_Rq "Signal not transmitted on gas and HEV variants.";
CM_ SG_ 977 CnvtTopPos_Up_Stat "Signal not transmitted on vehicles without convertible tops.";
CM_ SG_ 977 CnvtTopPos_Dn_Stat "Signal not transmitted on vehicles without convertible tops.";
CM_ SG_ 1189 Running_Board_Stat "Update msg. $115 to Event @ INIT in CMDB v4.06, 5/27/05.";
CM_ SG_ 959 TrnPrkSys_D_Actl "Powersplit HEVs with HF45, HPCM will Tx  this message.  For all other programs it will be Tx by PCM or TCM. ";
CM_ BO_ 374 "Programs w/o HS1 0x172 will need HS1 0x176 for GearPos_D_Actl.  Future MY Programs that choose c/o still require HS1 0x172. ";
CM_ SG_ 374 TrnRng_D_Rq "Powersplit HEVs with HF45, HPCM will Tx  this message.  For all other programs it will be Tx by PCM or TCM. ";
CM_ SG_ 374 TrnPrkSys_D_Actl "Powersplit HEVs with HF45, HPCM will Tx  this message.  For all other programs it will be Tx by PCM or TCM. ";
CM_ SG_ 374 GearLvr_D_ActlDrv "Powersplit HEVs with HF45, HPCM will Tx  this message.  For all other programs it will be Tx by PCM or TCM. ";
CM_ SG_ 374 GearPos_No_Cs "Powersplit HEVs with HF45, HPCM will Tx  this message.  For all other programs it will be Tx by PCM or TCM. ";
CM_ SG_ 374 GearPos_D_Trg "Powersplit HEVs with HF45, HPCM will Tx  this message.  For all other programs it will be Tx by PCM or TCM. ";
CM_ SG_ 374 GearPos_No_Cnt "Powersplit HEVs with HF45, HPCM will Tx  this message.  For all other programs it will be Tx by PCM or TCM. ";
CM_ SG_ 374 GearPos_D_Actl "Powersplit HEVs with HF45, HPCM will Tx  this message.  For all other programs it will be Tx by PCM or TCM. ";
CM_ SG_ 1079 GenericSwtch2_No_Actl "U625 Police Wig Wag feature";
CM_ BO_ 948 "$3B4 used by CGEA SPDJB";
CM_ SG_ 840 FohT2Friday_T_Rq "Signal not transmitted on vehicles that do not have the Fuel operated heater feature.";
CM_ SG_ 840 FohT1Friday_T_Rq "Signal not transmitted on vehicles that do not have the Fuel operated heater feature.";
CM_ SG_ 840 FohT2Wednesday_T_Rq "Signal not transmitted on vehicles that do not have the Fuel operated heater feature.";
CM_ SG_ 840 FohT2Tuesday_T_Rq "Signal not transmitted on vehicles that do not have the Fuel operated heater feature.";
CM_ SG_ 840 FohT2Thursday_T_Rq "Signal not transmitted on vehicles that do not have the Fuel operated heater feature.";
CM_ SG_ 840 FohT2Sunday_T_Rq "Signal not transmitted on vehicles that do not have the Fuel operated heater feature.";
CM_ SG_ 840 FohT2Saturday_T_Rq "Signal not transmitted on vehicles that do not have the Fuel operated heater feature.";
CM_ SG_ 840 FohT2Monday_T_Rq "Signal not transmitted on vehicles that do not have the Fuel operated heater feature.";
CM_ SG_ 840 FohT1Wednesday_T_Rq "Signal not transmitted on vehicles that do not have the Fuel operated heater feature.";
CM_ SG_ 840 FohT1Tuesday_T_Rq "Signal not transmitted on vehicles that do not have the Fuel operated heater feature.";
CM_ SG_ 840 FohT1Thursday_T_Rq "Signal not transmitted on vehicles that do not have the Fuel operated heater feature.";
CM_ SG_ 840 FohT1Sunday_T_Rq "Signal not transmitted on vehicles that do not have the Fuel operated heater feature.";
CM_ SG_ 840 FohT1Saturday_T_Rq "Signal not transmitted on vehicles that do not have the Fuel operated heater feature.";
CM_ SG_ 840 FohT1Monday_T_Rq "Signal not transmitted on vehicles that do not have the Fuel operated heater feature.";
CM_ SG_ 981 HvacPrecondMode2_D_Rq "Signal not transmitted on vehicles that do not have the Fuel operated heater feature.";
CM_ SG_ 981 HvacPrecondBlwr2_D_Rq "Signal not transmitted on vehicles that do not have the Fuel operated heater feature.";
BA_DEF_ BO_  "FrameRouting" STRING ;
BA_DEF_ BO_  "FrameGatewayNetwork" STRING ;
BA_DEF_ BO_  "NetworkInitialization" ENUM  "No","Yes";
BA_DEF_ BO_  "FrameGatewayId" HEX 0 1407;
BA_DEF_ BO_  "EventRateOfChange" INT 10 10000;
BA_DEF_ BO_  "GenMsgStartDelayTime" INT 0 10000;
BA_DEF_ BO_  "GenMsgNrOfRepetition" INT 0 100;
BA_DEF_ BO_  "GenMsgDelayTime" INT 0 1000;
BA_DEF_ BO_  "GenMsgCycleTime" INT 0 100000;
BA_DEF_ BO_  "GenMsgSendType" ENUM  "FixedPeriodic","Event","EnabledPeriodic","NotUsed","NotUsed","EventPeriodic","NotUsed","NotUsed","NoMsgSendType";
BA_DEF_ SG_  "U_CD764_MY2022_Tx" ENUM  "No","Yes";
BA_DEF_ SG_  "U_U55X_MY2022_Tx" ENUM  "No","Yes";
BA_DEF_ SG_  "U_CD542_MY2021_Tx" ENUM  "No","Yes";
BA_DEF_ SG_  "ECGUsedTxSignal" ENUM  "No","Yes";
BA_DEF_ SG_  "U_T6_MCA_MY2020_Tx" ENUM  "No","Yes";
BA_DEF_ SG_  "U_P702_MY2021_Tx" ENUM  "No","Yes";
BA_DEF_ SG_  "U_CX727_MY2021_Tx" ENUM  "No","Yes";
BA_DEF_ SG_  "U_CD764_MY2022_Rx" ENUM  "No","Yes";
BA_DEF_ SG_  "U_U55X_MY2022_Rx" ENUM  "No","Yes";
BA_DEF_ SG_  "U_CD542_MY2021_Rx" ENUM  "No","Yes";
BA_DEF_ SG_  "ECGUsedRxSignal" ENUM  "No","Yes";
BA_DEF_ SG_  "U_T6_MCA_MY2020_Rx" ENUM  "No","Yes";
BA_DEF_ SG_  "U_P702_MY2021_Rx" ENUM  "No","Yes";
BA_DEF_ SG_  "U_CX727_MY2021_Rx" ENUM  "No","Yes";
BA_DEF_ SG_  "GenSigStartValue" HEX 0 268435455;
BA_DEF_ SG_  "MetaData" ENUM  "No","Yes";
BA_DEF_ SG_  "ContentDependant" ENUM  "No","Yes";
BA_DEF_ SG_  "GenSigStartValueInteger" INT 0 1000000000;
BA_DEF_ SG_  "UsedOnPgmDBC" ENUM  "No","Yes";
BA_DEF_ SG_  "WakeupSignal" ENUM  "No","Yes";
BA_DEF_ SG_  "GenSigInactiveValue" INT 0 100000;
BA_DEF_ SG_  "GenSigSendType" ENUM  "Cyclic","OnWrite","vector_leerstring","OnChange","vector_leerstring","IfActive","vector_leerstring","NoSigSendType";
BA_DEF_ BO_  "OvtpPushApplication" ENUM  "FALSE","TRUE";
BA_DEF_ BO_  "SCP_FreshnessValueLength" INT 0 512;
BA_DEF_ BO_  "SCP_FreshnessValueTxLength" INT 0 512;
BA_DEF_ BO_  "SCP_AuthInfoTxLength" INT 0 512;
BA_DEF_ BO_  "GenMsgRoutingTimeoutTime" INT 0 5000;
BA_DEF_ BO_  "MessageGateway" ENUM  "No","Yes";
BA_DEF_ BO_  "NmAsrMessage" ENUM  "No","Yes";
BA_DEF_ BO_  "DiagState" ENUM  "No","Yes";
BA_DEF_ BO_  "TpTxIndex" INT 0 536870911;
BA_DEF_ BO_  "DiagRequest" ENUM  "No","Yes";
BA_DEF_ BO_  "DiagResponse" ENUM  "No","Yes";
BA_DEF_ BO_  "NmMessage" ENUM  "No","Yes";
BA_DEF_ BO_  "GenMsgILSupport" ENUM  "No","Yes";
BA_DEF_DEF_  "FrameRouting" "";
BA_DEF_DEF_  "FrameGatewayNetwork" "NONE";
BA_DEF_DEF_  "NetworkInitialization" "Yes";
BA_DEF_DEF_  "FrameGatewayId" 0;
BA_DEF_DEF_  "EventRateOfChange" 10000;
BA_DEF_DEF_  "GenMsgStartDelayTime" 0;
BA_DEF_DEF_  "GenMsgNrOfRepetition" 1;
BA_DEF_DEF_  "GenMsgDelayTime" 20;
BA_DEF_DEF_  "GenMsgCycleTime" 0;
BA_DEF_DEF_  "GenMsgSendType" "NoMsgSendType";
BA_DEF_DEF_  "U_CD764_MY2022_Tx" "No";
BA_DEF_DEF_  "U_U55X_MY2022_Tx" "No";
BA_DEF_DEF_  "U_CD542_MY2021_Tx" "No";
BA_DEF_DEF_  "ECGUsedTxSignal" "No";
BA_DEF_DEF_  "U_T6_MCA_MY2020_Tx" "No";
BA_DEF_DEF_  "U_P702_MY2021_Tx" "No";
BA_DEF_DEF_  "U_CX727_MY2021_Tx" "No";
BA_DEF_DEF_  "U_CD764_MY2022_Rx" "No";
BA_DEF_DEF_  "U_U55X_MY2022_Rx" "No";
BA_DEF_DEF_  "U_CD542_MY2021_Rx" "No";
BA_DEF_DEF_  "ECGUsedRxSignal" "No";
BA_DEF_DEF_  "U_T6_MCA_MY2020_Rx" "No";
BA_DEF_DEF_  "U_P702_MY2021_Rx" "No";
BA_DEF_DEF_  "U_CX727_MY2021_Rx" "No";
BA_DEF_DEF_  "GenSigStartValue" 0;
BA_DEF_DEF_  "MetaData" "No";
BA_DEF_DEF_  "ContentDependant" "No";
BA_DEF_DEF_  "GenSigStartValueInteger" 0;
BA_DEF_DEF_  "UsedOnPgmDBC" "Yes";
BA_DEF_DEF_  "WakeupSignal" "No";
BA_DEF_DEF_  "GenSigInactiveValue" 0;
BA_DEF_DEF_  "GenSigSendType" "NoSigSendType";
BA_DEF_DEF_  "OvtpPushApplication" "FALSE";
BA_DEF_DEF_  "SCP_FreshnessValueLength" 64;
BA_DEF_DEF_  "SCP_FreshnessValueTxLength" 11;
BA_DEF_DEF_  "SCP_AuthInfoTxLength" 53;
BA_DEF_DEF_  "GenMsgRoutingTimeoutTime" 0;
BA_DEF_DEF_  "MessageGateway" "No";
BA_DEF_DEF_  "NmAsrMessage" "No";
BA_DEF_DEF_  "DiagState" "No";
BA_DEF_DEF_  "TpTxIndex" 0;
BA_DEF_DEF_  "DiagRequest" "No";
BA_DEF_DEF_  "DiagResponse" "No";
BA_DEF_DEF_  "NmMessage" "No";
BA_DEF_DEF_  "GenMsgILSupport" "Yes";
BA_ "NetworkInitialization" BO_ 1861 0;
BA_ "GenMsgDelayTime" BO_ 1861 0;
BA_ "GenMsgSendType" BO_ 1861 1;
BA_ "DiagRequest" BO_ 1861 1;
BA_ "GenMsgILSupport" BO_ 1861 0;
BA_ "NetworkInitialization" BO_ 1500 0;
BA_ "GenMsgCycleTime" BO_ 1500 1000;
BA_ "GenMsgSendType" BO_ 1500 0;
BA_ "NmAsrMessage" BO_ 1500 1;
BA_ "GenMsgILSupport" BO_ 1500 0;
BA_ "NetworkInitialization" BO_ 1799 0;
BA_ "GenMsgDelayTime" BO_ 1799 0;
BA_ "GenMsgSendType" BO_ 1799 1;
BA_ "DiagRequest" BO_ 1799 1;
BA_ "GenMsgILSupport" BO_ 1799 0;
BA_ "GenMsgCycleTime" BO_ 883 1000;
BA_ "GenMsgSendType" BO_ 883 0;
BA_ "GenMsgCycleTime" BO_ 884 1000;
BA_ "GenMsgSendType" BO_ 884 0;
BA_ "FrameRouting" BO_ 674 "HS3_CAN,0x2A2;";
BA_ "FrameGatewayNetwork" BO_ 674 "HS3_CAN";
BA_ "FrameGatewayId" BO_ 674 674;
BA_ "GenMsgStartDelayTime" BO_ 674 150;
BA_ "GenMsgDelayTime" BO_ 674 10;
BA_ "NetworkInitialization" BO_ 2611177688 0;
BA_ "GenMsgDelayTime" BO_ 2611177688 0;
BA_ "GenMsgSendType" BO_ 2611177688 1;
BA_ "TpTxIndex" BO_ 2611177688 463694040;
BA_ "NetworkInitialization" BO_ 2611175642 0;
BA_ "GenMsgDelayTime" BO_ 2611175642 0;
BA_ "GenMsgSendType" BO_ 2611175642 1;
BA_ "TpTxIndex" BO_ 2611175642 463694040;
BA_ "NetworkInitialization" BO_ 2612224218 0;
BA_ "GenMsgDelayTime" BO_ 2612224218 0;
BA_ "GenMsgSendType" BO_ 2612224218 1;
BA_ "OvtpPushApplication" BO_ 2612224218 1;
BA_ "TpTxIndex" BO_ 2612224218 464742616;
BA_ "GenMsgSendType" BO_ 1349 1;
BA_ "NmMessage" BO_ 1349 1;
BA_ "GenMsgILSupport" BO_ 1349 0;
BA_ "NetworkInitialization" BO_ 1438 0;
BA_ "GenMsgCycleTime" BO_ 1438 1000;
BA_ "GenMsgSendType" BO_ 1438 0;
BA_ "NmAsrMessage" BO_ 1438 1;
BA_ "GenMsgILSupport" BO_ 1438 0;
BA_ "GenMsgCycleTime" BO_ 933 50;
BA_ "GenMsgSendType" BO_ 933 0;
BA_ "GenMsgCycleTime" BO_ 841 1000;
BA_ "GenMsgSendType" BO_ 841 5;
BA_ "GenMsgCycleTime" BO_ 932 50;
BA_ "GenMsgSendType" BO_ 932 0;
BA_ "GenMsgCycleTime" BO_ 1075 1000;
BA_ "GenMsgSendType" BO_ 1075 5;
BA_ "GenMsgCycleTime" BO_ 1166 1000;
BA_ "GenMsgSendType" BO_ 1166 5;
BA_ "GenMsgCycleTime" BO_ 1165 1000;
BA_ "GenMsgSendType" BO_ 1165 5;
BA_ "GenMsgCycleTime" BO_ 1164 1000;
BA_ "GenMsgSendType" BO_ 1164 5;
BA_ "GenMsgCycleTime" BO_ 1163 1000;
BA_ "GenMsgSendType" BO_ 1163 5;
BA_ "GenMsgCycleTime" BO_ 1162 1000;
BA_ "GenMsgSendType" BO_ 1162 5;
BA_ "NetworkInitialization" BO_ 1961 0;
BA_ "GenMsgDelayTime" BO_ 1961 0;
BA_ "GenMsgSendType" BO_ 1961 1;
BA_ "DiagResponse" BO_ 1961 1;
BA_ "GenMsgILSupport" BO_ 1961 0;
BA_ "NetworkInitialization" BO_ 1954 0;
BA_ "GenMsgDelayTime" BO_ 1954 0;
BA_ "GenMsgSendType" BO_ 1954 1;
BA_ "DiagRequest" BO_ 1954 1;
BA_ "GenMsgILSupport" BO_ 1954 0;
BA_ "NetworkInitialization" BO_ 1972 0;
BA_ "GenMsgDelayTime" BO_ 1972 0;
BA_ "GenMsgSendType" BO_ 1972 1;
BA_ "DiagRequest" BO_ 1972 1;
BA_ "GenMsgILSupport" BO_ 1972 0;
BA_ "NetworkInitialization" BO_ 1963 0;
BA_ "GenMsgDelayTime" BO_ 1963 0;
BA_ "GenMsgSendType" BO_ 1963 1;
BA_ "DiagResponse" BO_ 1963 1;
BA_ "GenMsgILSupport" BO_ 1963 0;
BA_ "NetworkInitialization" BO_ 1955 0;
BA_ "GenMsgDelayTime" BO_ 1955 0;
BA_ "GenMsgSendType" BO_ 1955 1;
BA_ "DiagRequest" BO_ 1955 1;
BA_ "GenMsgILSupport" BO_ 1955 0;
BA_ "NetworkInitialization" BO_ 1953 0;
BA_ "GenMsgDelayTime" BO_ 1953 0;
BA_ "GenMsgSendType" BO_ 1953 1;
BA_ "DiagRequest" BO_ 1953 1;
BA_ "GenMsgILSupport" BO_ 1953 0;
BA_ "NetworkInitialization" BO_ 1891 0;
BA_ "GenMsgDelayTime" BO_ 1891 0;
BA_ "GenMsgSendType" BO_ 1891 1;
BA_ "DiagRequest" BO_ 1891 1;
BA_ "GenMsgILSupport" BO_ 1891 0;
BA_ "NetworkInitialization" BO_ 1794 0;
BA_ "GenMsgDelayTime" BO_ 1794 0;
BA_ "GenMsgSendType" BO_ 1794 1;
BA_ "DiagRequest" BO_ 1794 1;
BA_ "GenMsgILSupport" BO_ 1794 0;
BA_ "GenMsgSendType" BO_ 1356 1;
BA_ "NmMessage" BO_ 1356 1;
BA_ "GenMsgILSupport" BO_ 1356 0;
BA_ "GenMsgCycleTime" BO_ 978 100;
BA_ "GenMsgSendType" BO_ 978 5;
BA_ "GenMsgCycleTime" BO_ 977 100;
BA_ "GenMsgSendType" BO_ 977 5;
BA_ "NetworkInitialization" BO_ 1976 0;
BA_ "GenMsgDelayTime" BO_ 1976 0;
BA_ "GenMsgSendType" BO_ 1976 1;
BA_ "DiagResponse" BO_ 1976 1;
BA_ "GenMsgILSupport" BO_ 1976 0;
BA_ "NetworkInitialization" BO_ 1944 0;
BA_ "GenMsgDelayTime" BO_ 1944 0;
BA_ "GenMsgSendType" BO_ 1944 1;
BA_ "DiagResponse" BO_ 1944 1;
BA_ "GenMsgILSupport" BO_ 1944 0;
BA_ "NetworkInitialization" BO_ 1968 0;
BA_ "GenMsgDelayTime" BO_ 1968 0;
BA_ "GenMsgSendType" BO_ 1968 1;
BA_ "DiagRequest" BO_ 1968 1;
BA_ "GenMsgILSupport" BO_ 1968 0;
BA_ "NetworkInitialization" BO_ 1936 0;
BA_ "GenMsgDelayTime" BO_ 1936 0;
BA_ "GenMsgSendType" BO_ 1936 1;
BA_ "DiagRequest" BO_ 1936 1;
BA_ "GenMsgILSupport" BO_ 1936 0;
BA_ "FrameRouting" BO_ 968 "HS3_CAN,0x3C8;";
BA_ "FrameGatewayNetwork" BO_ 968 "HS3_CAN";
BA_ "FrameGatewayId" BO_ 968 968;
BA_ "NetworkInitialization" BO_ 1971 0;
BA_ "GenMsgDelayTime" BO_ 1971 0;
BA_ "GenMsgSendType" BO_ 1971 1;
BA_ "DiagRequest" BO_ 1971 1;
BA_ "GenMsgILSupport" BO_ 1971 0;
BA_ "NetworkInitialization" BO_ 1890 0;
BA_ "GenMsgDelayTime" BO_ 1890 0;
BA_ "GenMsgSendType" BO_ 1890 1;
BA_ "DiagRequest" BO_ 1890 1;
BA_ "GenMsgILSupport" BO_ 1890 0;
BA_ "NetworkInitialization" BO_ 1980 0;
BA_ "GenMsgDelayTime" BO_ 1980 0;
BA_ "GenMsgSendType" BO_ 1980 1;
BA_ "DiagResponse" BO_ 1980 1;
BA_ "GenMsgILSupport" BO_ 1980 0;
BA_ "NetworkInitialization" BO_ 1979 0;
BA_ "GenMsgDelayTime" BO_ 1979 0;
BA_ "GenMsgSendType" BO_ 1979 1;
BA_ "DiagResponse" BO_ 1979 1;
BA_ "GenMsgILSupport" BO_ 1979 0;
BA_ "GenMsgCycleTime" BO_ 852 1000;
BA_ "GenMsgSendType" BO_ 852 5;
BA_ "GenMsgCycleTime" BO_ 851 1000;
BA_ "GenMsgSendType" BO_ 851 5;
BA_ "GenMsgCycleTime" BO_ 876 1000;
BA_ "GenMsgSendType" BO_ 876 5;
BA_ "GenMsgCycleTime" BO_ 1045 100;
BA_ "GenMsgSendType" BO_ 1045 0;
BA_ "GenMsgRoutingTimeoutTime" BO_ 1045 60;
BA_ "MessageGateway" BO_ 1045 1;
BA_ "GenMsgCycleTime" BO_ 1189 1000;
BA_ "GenMsgSendType" BO_ 1189 5;
BA_ "GenMsgDelayTime" BO_ 858 50;
BA_ "GenMsgCycleTime" BO_ 858 1000;
BA_ "GenMsgSendType" BO_ 858 5;
BA_ "NetworkInitialization" BO_ 1925 0;
BA_ "GenMsgDelayTime" BO_ 1925 0;
BA_ "GenMsgSendType" BO_ 1925 1;
BA_ "DiagRequest" BO_ 1925 1;
BA_ "GenMsgILSupport" BO_ 1925 0;
BA_ "NetworkInitialization" BO_ 1933 0;
BA_ "GenMsgDelayTime" BO_ 1933 0;
BA_ "GenMsgSendType" BO_ 1933 1;
BA_ "DiagResponse" BO_ 1933 1;
BA_ "GenMsgILSupport" BO_ 1933 0;
BA_ "NetworkInitialization" BO_ 2611120344 0;
BA_ "GenMsgDelayTime" BO_ 2611120344 0;
BA_ "GenMsgSendType" BO_ 2611120344 1;
BA_ "TpTxIndex" BO_ 2611120344 463636696;
BA_ "NetworkInitialization" BO_ 2611175586 0;
BA_ "GenMsgDelayTime" BO_ 2611175586 0;
BA_ "GenMsgSendType" BO_ 2611175586 1;
BA_ "TpTxIndex" BO_ 2611175586 463636696;
BA_ "NetworkInitialization" BO_ 2612224162 0;
BA_ "GenMsgDelayTime" BO_ 2612224162 0;
BA_ "GenMsgSendType" BO_ 2612224162 1;
BA_ "OvtpPushApplication" BO_ 2612224162 1;
BA_ "TpTxIndex" BO_ 2612224162 464685272;
BA_ "NetworkInitialization" BO_ 2610129112 0;
BA_ "GenMsgDelayTime" BO_ 2610129112 0;
BA_ "GenMsgSendType" BO_ 2610129112 1;
BA_ "TpTxIndex" BO_ 2610129112 462645464;
BA_ "NetworkInitialization" BO_ 2610127066 0;
BA_ "GenMsgDelayTime" BO_ 2610127066 0;
BA_ "GenMsgSendType" BO_ 2610127066 1;
BA_ "TpTxIndex" BO_ 2610127066 462645464;
BA_ "NetworkInitialization" BO_ 2610071768 0;
BA_ "GenMsgDelayTime" BO_ 2610071768 0;
BA_ "GenMsgSendType" BO_ 2610071768 1;
BA_ "TpTxIndex" BO_ 2610071768 462588120;
BA_ "NetworkInitialization" BO_ 2610127010 0;
BA_ "GenMsgDelayTime" BO_ 2610127010 0;
BA_ "GenMsgSendType" BO_ 2610127010 1;
BA_ "TpTxIndex" BO_ 2610127010 462588120;
BA_ "NetworkInitialization" BO_ 2611110104 0;
BA_ "GenMsgDelayTime" BO_ 2611110104 0;
BA_ "GenMsgSendType" BO_ 2611110104 1;
BA_ "TpTxIndex" BO_ 2611110104 463626456;
BA_ "NetworkInitialization" BO_ 2612224152 0;
BA_ "GenMsgDelayTime" BO_ 2612224152 0;
BA_ "GenMsgSendType" BO_ 2612224152 1;
BA_ "OvtpPushApplication" BO_ 2612224152 1;
BA_ "TpTxIndex" BO_ 2612224152 464675032;
BA_ "NetworkInitialization" BO_ 2611175576 0;
BA_ "GenMsgDelayTime" BO_ 2611175576 0;
BA_ "GenMsgSendType" BO_ 2611175576 1;
BA_ "TpTxIndex" BO_ 2611175576 463626456;
BA_ "NetworkInitialization" BO_ 2610061528 0;
BA_ "GenMsgDelayTime" BO_ 2610061528 0;
BA_ "GenMsgSendType" BO_ 2610061528 1;
BA_ "TpTxIndex" BO_ 2610061528 462577880;
BA_ "NetworkInitialization" BO_ 2610127000 0;
BA_ "GenMsgDelayTime" BO_ 2610127000 0;
BA_ "GenMsgSendType" BO_ 2610127000 1;
BA_ "TpTxIndex" BO_ 2610127000 462577880;
BA_ "GenMsgCycleTime" BO_ 959 100;
BA_ "GenMsgSendType" BO_ 959 5;
BA_ "GenMsgDelayTime" BO_ 2610126913 0;
BA_ "GenMsgSendType" BO_ 2610126913 1;
BA_ "TpTxIndex" BO_ 2610126913 462488792;
BA_ "NetworkInitialization" BO_ 2612002008 0;
BA_ "GenMsgDelayTime" BO_ 2612002008 0;
BA_ "GenMsgSendType" BO_ 2612002008 1;
BA_ "TpTxIndex" BO_ 2612002008 464518360;
BA_ "NetworkInitialization" BO_ 2610953432 0;
BA_ "GenMsgDelayTime" BO_ 2610953432 0;
BA_ "GenMsgSendType" BO_ 2610953432 1;
BA_ "TpTxIndex" BO_ 2610953432 463469784;
BA_ "GenMsgDelayTime" BO_ 2611175489 0;
BA_ "GenMsgSendType" BO_ 2611175489 1;
BA_ "TpTxIndex" BO_ 2611175489 463537368;
BA_ "GenMsgCycleTime" BO_ 1255 50;
BA_ "GenMsgSendType" BO_ 1255 0;
BA_ "GenMsgCycleTime" BO_ 1254 50;
BA_ "GenMsgSendType" BO_ 1254 0;
BA_ "GenMsgCycleTime" BO_ 1253 50;
BA_ "GenMsgSendType" BO_ 1253 0;
BA_ "GenMsgCycleTime" BO_ 1252 50;
BA_ "GenMsgSendType" BO_ 1252 0;
BA_ "GenMsgCycleTime" BO_ 1251 200;
BA_ "GenMsgSendType" BO_ 1251 0;
BA_ "GenMsgCycleTime" BO_ 1250 200;
BA_ "GenMsgSendType" BO_ 1250 0;
BA_ "GenMsgCycleTime" BO_ 1249 200;
BA_ "GenMsgSendType" BO_ 1249 0;
BA_ "GenMsgCycleTime" BO_ 1248 200;
BA_ "GenMsgSendType" BO_ 1248 0;
BA_ "NetworkInitialization" BO_ 1998 0;
BA_ "GenMsgDelayTime" BO_ 1998 0;
BA_ "GenMsgSendType" BO_ 1998 1;
BA_ "DiagResponse" BO_ 1998 1;
BA_ "GenMsgILSupport" BO_ 1998 0;
BA_ "NetworkInitialization" BO_ 1996 0;
BA_ "GenMsgDelayTime" BO_ 1996 0;
BA_ "GenMsgSendType" BO_ 1996 1;
BA_ "DiagResponse" BO_ 1996 1;
BA_ "GenMsgILSupport" BO_ 1996 0;
BA_ "NetworkInitialization" BO_ 1990 0;
BA_ "GenMsgDelayTime" BO_ 1990 0;
BA_ "GenMsgSendType" BO_ 1990 1;
BA_ "DiagRequest" BO_ 1990 1;
BA_ "GenMsgILSupport" BO_ 1990 0;
BA_ "NetworkInitialization" BO_ 1988 0;
BA_ "GenMsgDelayTime" BO_ 1988 0;
BA_ "GenMsgSendType" BO_ 1988 1;
BA_ "DiagRequest" BO_ 1988 1;
BA_ "GenMsgILSupport" BO_ 1988 0;
BA_ "GenMsgCycleTime" BO_ 798 1000;
BA_ "GenMsgSendType" BO_ 798 5;
BA_ "GenMsgCycleTime" BO_ 302 100;
BA_ "GenMsgSendType" BO_ 302 0;
BA_ "FrameRouting" BO_ 374 "FD1_CAN,0x176;";
BA_ "FrameGatewayNetwork" BO_ 374 "FD1_CAN";
BA_ "FrameGatewayId" BO_ 374 374;
BA_ "GenMsgCycleTime" BO_ 300 1000;
BA_ "GenMsgSendType" BO_ 300 5;
BA_ "FrameRouting" BO_ 662 "HS3_CAN,0x296;";
BA_ "FrameGatewayNetwork" BO_ 662 "HS3_CAN";
BA_ "FrameGatewayId" BO_ 662 662;
BA_ "GenMsgCycleTime" BO_ 670 500;
BA_ "GenMsgSendType" BO_ 670 5;
BA_ "GenMsgCycleTime" BO_ 669 500;
BA_ "GenMsgSendType" BO_ 669 5;
BA_ "GenMsgDelayTime" BO_ 2612224065 0;
BA_ "GenMsgSendType" BO_ 2612224065 1;
BA_ "OvtpPushApplication" BO_ 2612224065 1;
BA_ "TpTxIndex" BO_ 2612224065 464585944;
BA_ "GenMsgDelayTime" BO_ 2612069592 0;
BA_ "GenMsgSendType" BO_ 2612069592 1;
BA_ "OvtpPushApplication" BO_ 2612069592 1;
BA_ "TpTxIndex" BO_ 2612069592 464585944;
BA_ "NetworkInitialization" BO_ 1413 0;
BA_ "GenMsgCycleTime" BO_ 1413 1000;
BA_ "GenMsgSendType" BO_ 1413 0;
BA_ "NmAsrMessage" BO_ 1413 1;
BA_ "GenMsgILSupport" BO_ 1413 0;
BA_ "NetworkInitialization" BO_ 1412 0;
BA_ "GenMsgCycleTime" BO_ 1412 1000;
BA_ "GenMsgSendType" BO_ 1412 0;
BA_ "NmAsrMessage" BO_ 1412 1;
BA_ "GenMsgILSupport" BO_ 1412 0;
BA_ "GenMsgCycleTime" BO_ 1079 1000;
BA_ "GenMsgSendType" BO_ 1079 5;
BA_ "GenMsgCycleTime" BO_ 875 1000;
BA_ "GenMsgSendType" BO_ 875 5;
BA_ "NetworkInitialization" BO_ 1797 0;
BA_ "GenMsgDelayTime" BO_ 1797 0;
BA_ "GenMsgSendType" BO_ 1797 1;
BA_ "DiagRequest" BO_ 1797 1;
BA_ "GenMsgILSupport" BO_ 1797 0;
BA_ "GenMsgCycleTime" BO_ 941 50;
BA_ "GenMsgSendType" BO_ 941 0;
BA_ "GenMsgCycleTime" BO_ 940 50;
BA_ "GenMsgSendType" BO_ 940 0;
BA_ "FrameRouting" BO_ 1095 "HS1_CAN,0x447;";
BA_ "FrameGatewayNetwork" BO_ 1095 "HS1_CAN";
BA_ "FrameGatewayId" BO_ 1095 1095;
BA_ "FrameRouting" BO_ 948 "HS1_CAN,0x3B4;";
BA_ "FrameGatewayNetwork" BO_ 948 "HS1_CAN";
BA_ "FrameGatewayId" BO_ 948 948;
BA_ "GenMsgSendType" BO_ 1361 1;
BA_ "NmMessage" BO_ 1361 1;
BA_ "GenMsgILSupport" BO_ 1361 0;
BA_ "FrameRouting" BO_ 840 "HS3_CAN,0x348;";
BA_ "FrameGatewayNetwork" BO_ 840 "HS3_CAN";
BA_ "FrameGatewayId" BO_ 840 840;
BA_ "FrameRouting" BO_ 132 "HS1_CAN,0x84;";
BA_ "FrameGatewayNetwork" BO_ 132 "HS1_CAN";
BA_ "FrameGatewayId" BO_ 132 132;
BA_ "NetworkInitialization" BO_ 1796 0;
BA_ "GenMsgDelayTime" BO_ 1796 0;
BA_ "GenMsgSendType" BO_ 1796 1;
BA_ "DiagRequest" BO_ 1796 1;
BA_ "GenMsgILSupport" BO_ 1796 0;
BA_ "NetworkInitialization" BO_ 1927 0;
BA_ "GenMsgDelayTime" BO_ 1927 0;
BA_ "GenMsgSendType" BO_ 1927 1;
BA_ "DiagRequest" BO_ 1927 1;
BA_ "GenMsgILSupport" BO_ 1927 0;
BA_ "NetworkInitialization" BO_ 1935 0;
BA_ "GenMsgDelayTime" BO_ 1935 0;
BA_ "GenMsgSendType" BO_ 1935 1;
BA_ "DiagResponse" BO_ 1935 1;
BA_ "GenMsgILSupport" BO_ 1935 0;
BA_ "NetworkInitialization" BO_ 1514 0;
BA_ "GenMsgCycleTime" BO_ 1514 1000;
BA_ "GenMsgSendType" BO_ 1514 0;
BA_ "NmAsrMessage" BO_ 1514 1;
BA_ "GenMsgILSupport" BO_ 1514 0;
BA_ "FrameRouting" BO_ 945 "HS1_CAN,0x3B1;";
BA_ "FrameGatewayNetwork" BO_ 945 "HS1_CAN";
BA_ "FrameGatewayId" BO_ 945 945;
BA_ "NetworkInitialization" BO_ 1804 0;
BA_ "GenMsgDelayTime" BO_ 1804 0;
BA_ "GenMsgSendType" BO_ 1804 1;
BA_ "DiagResponse" BO_ 1804 1;
BA_ "GenMsgILSupport" BO_ 1804 0;
BA_ "GenMsgCycleTime" BO_ 981 1000;
BA_ "GenMsgSendType" BO_ 981 0;
BA_ "NetworkInitialization" BO_ 1446 0;
BA_ "GenMsgCycleTime" BO_ 1446 1000;
BA_ "GenMsgSendType" BO_ 1446 0;
BA_ "NmAsrMessage" BO_ 1446 1;
BA_ "GenMsgILSupport" BO_ 1446 0;
BA_ "NetworkInitialization" BO_ 1898 0;
BA_ "GenMsgDelayTime" BO_ 1898 0;
BA_ "GenMsgSendType" BO_ 1898 1;
BA_ "DiagResponse" BO_ 1898 1;
BA_ "GenMsgILSupport" BO_ 1898 0;
BA_ "NetworkInitialization" BO_ 1959 0;
BA_ "GenMsgDelayTime" BO_ 1959 0;
BA_ "GenMsgSendType" BO_ 1959 1;
BA_ "DiagRequest" BO_ 1959 1;
BA_ "GenMsgILSupport" BO_ 1959 0;
BA_ "NetworkInitialization" BO_ 1967 0;
BA_ "GenMsgDelayTime" BO_ 1967 0;
BA_ "GenMsgSendType" BO_ 1967 1;
BA_ "DiagResponse" BO_ 1967 1;
BA_ "GenMsgILSupport" BO_ 1967 0;
BA_ "NetworkInitialization" BO_ 1501 0;
BA_ "GenMsgCycleTime" BO_ 1501 1000;
BA_ "GenMsgSendType" BO_ 1501 0;
BA_ "NmAsrMessage" BO_ 1501 1;
BA_ "GenMsgILSupport" BO_ 1501 0;
BA_ "GenSigSendType" SG_ 1861 TesterPhysicalReqDASM 3;
BA_ "GenSigStartValue" SG_ 1500 DASM_GWOnBoardTester 255;
BA_ "ContentDependant" SG_ 1500 DASM_GWOnBoardTester 1;
BA_ "GenSigStartValueInteger" SG_ 1500 DASM_GWOnBoardTester 255;
BA_ "GenSigStartValue" SG_ 1500 DASM_GWNMProxy 255;
BA_ "ContentDependant" SG_ 1500 DASM_GWNMProxy 1;
BA_ "GenSigStartValueInteger" SG_ 1500 DASM_GWNMProxy 255;
BA_ "GenSigStartValue" SG_ 1500 DASM_AutoSarNMReserved4 255;
BA_ "ContentDependant" SG_ 1500 DASM_AutoSarNMReserved4 1;
BA_ "GenSigStartValueInteger" SG_ 1500 DASM_AutoSarNMReserved4 255;
BA_ "GenSigStartValue" SG_ 1500 DASM_AutoSarNMReserved3 255;
BA_ "ContentDependant" SG_ 1500 DASM_AutoSarNMReserved3 1;
BA_ "GenSigStartValueInteger" SG_ 1500 DASM_AutoSarNMReserved3 255;
BA_ "GenSigStartValue" SG_ 1500 DASM_AutoSarNMReserved2 255;
BA_ "ContentDependant" SG_ 1500 DASM_AutoSarNMReserved2 1;
BA_ "GenSigStartValueInteger" SG_ 1500 DASM_AutoSarNMReserved2 255;
BA_ "GenSigStartValue" SG_ 1500 DASM_AutoSarNMReserved1 255;
BA_ "ContentDependant" SG_ 1500 DASM_AutoSarNMReserved1 1;
BA_ "GenSigStartValueInteger" SG_ 1500 DASM_AutoSarNMReserved1 255;
BA_ "GenSigStartValue" SG_ 1500 DASM_AutoSarNMNodeId 220;
BA_ "ContentDependant" SG_ 1500 DASM_AutoSarNMNodeId 1;
BA_ "GenSigStartValueInteger" SG_ 1500 DASM_AutoSarNMNodeId 150;
BA_ "ContentDependant" SG_ 1500 DASM_AutoSarNMControl 1;
BA_ "GenSigSendType" SG_ 1799 TesterPhysicalReqGFM3_FSLM 3;
BA_ "U_CD764_MY2022_Tx" SG_ 883 PmCabn10Mnte_Conc_Actl 1;
BA_ "U_U55X_MY2022_Tx" SG_ 883 PmCabn10Mnte_Conc_Actl 1;
BA_ "U_CD542_MY2021_Tx" SG_ 883 PmCabn10Mnte_Conc_Actl 1;
BA_ "U_T6_MCA_MY2020_Tx" SG_ 883 PmCabn10Mnte_Conc_Actl 1;
BA_ "U_P702_MY2021_Tx" SG_ 883 PmCabn10Mnte_Conc_Actl 1;
BA_ "U_CX727_MY2021_Tx" SG_ 883 PmCabn10Mnte_Conc_Actl 1;
BA_ "GenSigStartValue" SG_ 883 PmCabn10Mnte_Conc_Actl 510;
BA_ "GenSigStartValueInteger" SG_ 883 PmCabn10Mnte_Conc_Actl 510;
BA_ "U_CD764_MY2022_Tx" SG_ 883 PmCabn08Mnte_Conc_Actl 1;
BA_ "U_U55X_MY2022_Tx" SG_ 883 PmCabn08Mnte_Conc_Actl 1;
BA_ "U_CD542_MY2021_Tx" SG_ 883 PmCabn08Mnte_Conc_Actl 1;
BA_ "U_T6_MCA_MY2020_Tx" SG_ 883 PmCabn08Mnte_Conc_Actl 1;
BA_ "U_P702_MY2021_Tx" SG_ 883 PmCabn08Mnte_Conc_Actl 1;
BA_ "U_CX727_MY2021_Tx" SG_ 883 PmCabn08Mnte_Conc_Actl 1;
BA_ "GenSigStartValue" SG_ 883 PmCabn08Mnte_Conc_Actl 510;
BA_ "GenSigStartValueInteger" SG_ 883 PmCabn08Mnte_Conc_Actl 510;
BA_ "U_CD764_MY2022_Tx" SG_ 883 PmCabn06Mnte_Conc_Actl 1;
BA_ "U_U55X_MY2022_Tx" SG_ 883 PmCabn06Mnte_Conc_Actl 1;
BA_ "U_CD542_MY2021_Tx" SG_ 883 PmCabn06Mnte_Conc_Actl 1;
BA_ "U_T6_MCA_MY2020_Tx" SG_ 883 PmCabn06Mnte_Conc_Actl 1;
BA_ "U_P702_MY2021_Tx" SG_ 883 PmCabn06Mnte_Conc_Actl 1;
BA_ "U_CX727_MY2021_Tx" SG_ 883 PmCabn06Mnte_Conc_Actl 1;
BA_ "GenSigStartValue" SG_ 883 PmCabn06Mnte_Conc_Actl 510;
BA_ "GenSigStartValueInteger" SG_ 883 PmCabn06Mnte_Conc_Actl 510;
BA_ "U_CD764_MY2022_Tx" SG_ 883 PmCabn04Mnte_Conc_Actl 1;
BA_ "U_U55X_MY2022_Tx" SG_ 883 PmCabn04Mnte_Conc_Actl 1;
BA_ "U_CD542_MY2021_Tx" SG_ 883 PmCabn04Mnte_Conc_Actl 1;
BA_ "U_T6_MCA_MY2020_Tx" SG_ 883 PmCabn04Mnte_Conc_Actl 1;
BA_ "U_P702_MY2021_Tx" SG_ 883 PmCabn04Mnte_Conc_Actl 1;
BA_ "U_CX727_MY2021_Tx" SG_ 883 PmCabn04Mnte_Conc_Actl 1;
BA_ "GenSigStartValue" SG_ 883 PmCabn04Mnte_Conc_Actl 510;
BA_ "GenSigStartValueInteger" SG_ 883 PmCabn04Mnte_Conc_Actl 510;
BA_ "U_CD764_MY2022_Tx" SG_ 883 PmCabn02Mnte_Conc_Actl 1;
BA_ "U_U55X_MY2022_Tx" SG_ 883 PmCabn02Mnte_Conc_Actl 1;
BA_ "U_CD542_MY2021_Tx" SG_ 883 PmCabn02Mnte_Conc_Actl 1;
BA_ "U_T6_MCA_MY2020_Tx" SG_ 883 PmCabn02Mnte_Conc_Actl 1;
BA_ "U_P702_MY2021_Tx" SG_ 883 PmCabn02Mnte_Conc_Actl 1;
BA_ "U_CX727_MY2021_Tx" SG_ 883 PmCabn02Mnte_Conc_Actl 1;
BA_ "GenSigStartValue" SG_ 883 PmCabn02Mnte_Conc_Actl 510;
BA_ "GenSigStartValueInteger" SG_ 883 PmCabn02Mnte_Conc_Actl 510;
BA_ "U_CD764_MY2022_Tx" SG_ 884 UltraFreshCabn_D_Stat 1;
BA_ "U_CD542_MY2021_Tx" SG_ 884 UltraFreshCabn_D_Stat 1;
BA_ "U_CD764_MY2022_Tx" SG_ 884 PmSnsCabn_D_Stat 1;
BA_ "U_U55X_MY2022_Tx" SG_ 884 PmSnsCabn_D_Stat 1;
BA_ "U_CD542_MY2021_Tx" SG_ 884 PmSnsCabn_D_Stat 1;
BA_ "U_T6_MCA_MY2020_Tx" SG_ 884 PmSnsCabn_D_Stat 1;
BA_ "U_P702_MY2021_Tx" SG_ 884 PmSnsCabn_D_Stat 1;
BA_ "U_CX727_MY2021_Tx" SG_ 884 PmSnsCabn_D_Stat 1;
BA_ "GenSigStartValue" SG_ 884 PmSnsCabn_D_Stat 5;
BA_ "GenSigStartValueInteger" SG_ 884 PmSnsCabn_D_Stat 5;
BA_ "U_CD764_MY2022_Tx" SG_ 884 PmCabn_Conc_Actl 1;
BA_ "U_U55X_MY2022_Tx" SG_ 884 PmCabn_Conc_Actl 1;
BA_ "U_CD542_MY2021_Tx" SG_ 884 PmCabn_Conc_Actl 1;
BA_ "U_T6_MCA_MY2020_Tx" SG_ 884 PmCabn_Conc_Actl 1;
BA_ "U_P702_MY2021_Tx" SG_ 884 PmCabn_Conc_Actl 1;
BA_ "U_CX727_MY2021_Tx" SG_ 884 PmCabn_Conc_Actl 1;
BA_ "GenSigStartValue" SG_ 884 PmCabn_Conc_Actl 510;
BA_ "GenSigStartValueInteger" SG_ 884 PmCabn_Conc_Actl 510;
BA_ "U_CD764_MY2022_Tx" SG_ 884 PmCabn20Mnte_Conc_Actl 1;
BA_ "U_U55X_MY2022_Tx" SG_ 884 PmCabn20Mnte_Conc_Actl 1;
BA_ "U_CD542_MY2021_Tx" SG_ 884 PmCabn20Mnte_Conc_Actl 1;
BA_ "U_T6_MCA_MY2020_Tx" SG_ 884 PmCabn20Mnte_Conc_Actl 1;
BA_ "U_P702_MY2021_Tx" SG_ 884 PmCabn20Mnte_Conc_Actl 1;
BA_ "U_CX727_MY2021_Tx" SG_ 884 PmCabn20Mnte_Conc_Actl 1;
BA_ "GenSigStartValue" SG_ 884 PmCabn20Mnte_Conc_Actl 510;
BA_ "GenSigStartValueInteger" SG_ 884 PmCabn20Mnte_Conc_Actl 510;
BA_ "U_CD764_MY2022_Tx" SG_ 884 PmCabn18Mnte_Conc_Actl 1;
BA_ "U_U55X_MY2022_Tx" SG_ 884 PmCabn18Mnte_Conc_Actl 1;
BA_ "U_CD542_MY2021_Tx" SG_ 884 PmCabn18Mnte_Conc_Actl 1;
BA_ "U_T6_MCA_MY2020_Tx" SG_ 884 PmCabn18Mnte_Conc_Actl 1;
BA_ "U_P702_MY2021_Tx" SG_ 884 PmCabn18Mnte_Conc_Actl 1;
BA_ "U_CX727_MY2021_Tx" SG_ 884 PmCabn18Mnte_Conc_Actl 1;
BA_ "GenSigStartValue" SG_ 884 PmCabn18Mnte_Conc_Actl 510;
BA_ "GenSigStartValueInteger" SG_ 884 PmCabn18Mnte_Conc_Actl 510;
BA_ "U_CD764_MY2022_Tx" SG_ 884 PmCabn16Mnte_Conc_Actl 1;
BA_ "U_U55X_MY2022_Tx" SG_ 884 PmCabn16Mnte_Conc_Actl 1;
BA_ "U_CD542_MY2021_Tx" SG_ 884 PmCabn16Mnte_Conc_Actl 1;
BA_ "U_T6_MCA_MY2020_Tx" SG_ 884 PmCabn16Mnte_Conc_Actl 1;
BA_ "U_P702_MY2021_Tx" SG_ 884 PmCabn16Mnte_Conc_Actl 1;
BA_ "U_CX727_MY2021_Tx" SG_ 884 PmCabn16Mnte_Conc_Actl 1;
BA_ "GenSigStartValue" SG_ 884 PmCabn16Mnte_Conc_Actl 510;
BA_ "GenSigStartValueInteger" SG_ 884 PmCabn16Mnte_Conc_Actl 510;
BA_ "U_CD764_MY2022_Tx" SG_ 884 PmCabn14Mnte_Conc_Actl 1;
BA_ "U_U55X_MY2022_Tx" SG_ 884 PmCabn14Mnte_Conc_Actl 1;
BA_ "U_CD542_MY2021_Tx" SG_ 884 PmCabn14Mnte_Conc_Actl 1;
BA_ "U_T6_MCA_MY2020_Tx" SG_ 884 PmCabn14Mnte_Conc_Actl 1;
BA_ "U_P702_MY2021_Tx" SG_ 884 PmCabn14Mnte_Conc_Actl 1;
BA_ "U_CX727_MY2021_Tx" SG_ 884 PmCabn14Mnte_Conc_Actl 1;
BA_ "GenSigStartValue" SG_ 884 PmCabn14Mnte_Conc_Actl 510;
BA_ "GenSigStartValueInteger" SG_ 884 PmCabn14Mnte_Conc_Actl 510;
BA_ "U_CD764_MY2022_Tx" SG_ 884 PmCabn12Mnte_Conc_Actl 1;
BA_ "U_U55X_MY2022_Tx" SG_ 884 PmCabn12Mnte_Conc_Actl 1;
BA_ "U_CD542_MY2021_Tx" SG_ 884 PmCabn12Mnte_Conc_Actl 1;
BA_ "U_T6_MCA_MY2020_Tx" SG_ 884 PmCabn12Mnte_Conc_Actl 1;
BA_ "U_P702_MY2021_Tx" SG_ 884 PmCabn12Mnte_Conc_Actl 1;
BA_ "U_CX727_MY2021_Tx" SG_ 884 PmCabn12Mnte_Conc_Actl 1;
BA_ "GenSigStartValue" SG_ 884 PmCabn12Mnte_Conc_Actl 510;
BA_ "GenSigStartValueInteger" SG_ 884 PmCabn12Mnte_Conc_Actl 510;
BA_ "GenSigStartValue" SG_ 674 ArmrestStwdRear_B_Stat 1;
BA_ "GenSigStartValueInteger" SG_ 674 ArmrestStwdRear_B_Stat 1;
BA_ "U_U55X_MY2022_Tx" SG_ 2611177688 PARSEDPhysGWM_ECGtoRTM 1;
BA_ "U_CD542_MY2021_Tx" SG_ 2611177688 PARSEDPhysGWM_ECGtoRTM 1;
BA_ "ECGUsedTxSignal" SG_ 2611177688 PARSEDPhysGWM_ECGtoRTM 1;
BA_ "GenSigSendType" SG_ 2611177688 PARSEDPhysGWM_ECGtoRTM 3;
BA_ "U_U55X_MY2022_Rx" SG_ 2611175642 PARSEDPhysRTMtoGWM_ECG 1;
BA_ "U_CD542_MY2021_Rx" SG_ 2611175642 PARSEDPhysRTMtoGWM_ECG 1;
BA_ "ECGUsedRxSignal" SG_ 2611175642 PARSEDPhysRTMtoGWM_ECG 1;
BA_ "GenSigSendType" SG_ 2611175642 PARSEDPhysRTMtoGWM_ECG 3;
BA_ "U_U55X_MY2022_Rx" SG_ 2612224218 PARSEDPushRTMtoGWM_ECG 1;
BA_ "U_CD542_MY2021_Rx" SG_ 2612224218 PARSEDPushRTMtoGWM_ECG 1;
BA_ "ECGUsedRxSignal" SG_ 2612224218 PARSEDPushRTMtoGWM_ECG 1;
BA_ "GenSigSendType" SG_ 2612224218 PARSEDPushRTMtoGWM_ECG 3;
BA_ "U_U55X_MY2022_Tx" SG_ 1349 RBM_Network_Mgmt 1;
BA_ "U_P702_MY2021_Tx" SG_ 1349 RBM_Network_Mgmt 1;
BA_ "GenSigSendType" SG_ 1349 RBM_Network_Mgmt 3;
BA_ "U_CD764_MY2022_Tx" SG_ 1438 GWM_GWOnBoardTester 1;
BA_ "U_U55X_MY2022_Tx" SG_ 1438 GWM_GWOnBoardTester 1;
BA_ "U_CD542_MY2021_Tx" SG_ 1438 GWM_GWOnBoardTester 1;
BA_ "ECGUsedTxSignal" SG_ 1438 GWM_GWOnBoardTester 1;
BA_ "U_T6_MCA_MY2020_Tx" SG_ 1438 GWM_GWOnBoardTester 1;
BA_ "U_CD764_MY2022_Rx" SG_ 1438 GWM_GWOnBoardTester 1;
BA_ "U_CD542_MY2021_Rx" SG_ 1438 GWM_GWOnBoardTester 1;
BA_ "U_P702_MY2021_Rx" SG_ 1438 GWM_GWOnBoardTester 1;
BA_ "U_CX727_MY2021_Rx" SG_ 1438 GWM_GWOnBoardTester 1;
BA_ "U_U55X_MY2022_Rx" SG_ 1438 GWM_GWOnBoardTester 1;
BA_ "U_T6_MCA_MY2020_Rx" SG_ 1438 GWM_GWOnBoardTester 1;
BA_ "GenSigStartValue" SG_ 1438 GWM_GWOnBoardTester 255;
BA_ "ContentDependant" SG_ 1438 GWM_GWOnBoardTester 1;
BA_ "GenSigStartValueInteger" SG_ 1438 GWM_GWOnBoardTester 255;
BA_ "U_CD764_MY2022_Tx" SG_ 1438 GWM_GWNMProxy 1;
BA_ "U_U55X_MY2022_Tx" SG_ 1438 GWM_GWNMProxy 1;
BA_ "U_CD542_MY2021_Tx" SG_ 1438 GWM_GWNMProxy 1;
BA_ "ECGUsedTxSignal" SG_ 1438 GWM_GWNMProxy 1;
BA_ "U_T6_MCA_MY2020_Tx" SG_ 1438 GWM_GWNMProxy 1;
BA_ "U_CD764_MY2022_Rx" SG_ 1438 GWM_GWNMProxy 1;
BA_ "U_CD542_MY2021_Rx" SG_ 1438 GWM_GWNMProxy 1;
BA_ "U_P702_MY2021_Rx" SG_ 1438 GWM_GWNMProxy 1;
BA_ "U_CX727_MY2021_Rx" SG_ 1438 GWM_GWNMProxy 1;
BA_ "U_U55X_MY2022_Rx" SG_ 1438 GWM_GWNMProxy 1;
BA_ "U_T6_MCA_MY2020_Rx" SG_ 1438 GWM_GWNMProxy 1;
BA_ "GenSigStartValue" SG_ 1438 GWM_GWNMProxy 255;
BA_ "ContentDependant" SG_ 1438 GWM_GWNMProxy 1;
BA_ "GenSigStartValueInteger" SG_ 1438 GWM_GWNMProxy 255;
BA_ "U_CD764_MY2022_Tx" SG_ 1438 GWM_AutoSarNMReserved4 1;
BA_ "U_U55X_MY2022_Tx" SG_ 1438 GWM_AutoSarNMReserved4 1;
BA_ "U_CD542_MY2021_Tx" SG_ 1438 GWM_AutoSarNMReserved4 1;
BA_ "ECGUsedTxSignal" SG_ 1438 GWM_AutoSarNMReserved4 1;
BA_ "U_T6_MCA_MY2020_Tx" SG_ 1438 GWM_AutoSarNMReserved4 1;
BA_ "U_CD764_MY2022_Rx" SG_ 1438 GWM_AutoSarNMReserved4 1;
BA_ "U_CD542_MY2021_Rx" SG_ 1438 GWM_AutoSarNMReserved4 1;
BA_ "U_P702_MY2021_Rx" SG_ 1438 GWM_AutoSarNMReserved4 1;
BA_ "U_CX727_MY2021_Rx" SG_ 1438 GWM_AutoSarNMReserved4 1;
BA_ "U_U55X_MY2022_Rx" SG_ 1438 GWM_AutoSarNMReserved4 1;
BA_ "U_T6_MCA_MY2020_Rx" SG_ 1438 GWM_AutoSarNMReserved4 1;
BA_ "GenSigStartValue" SG_ 1438 GWM_AutoSarNMReserved4 255;
BA_ "ContentDependant" SG_ 1438 GWM_AutoSarNMReserved4 1;
BA_ "GenSigStartValueInteger" SG_ 1438 GWM_AutoSarNMReserved4 255;
BA_ "U_CD764_MY2022_Tx" SG_ 1438 GWM_AutoSarNMReserved3 1;
BA_ "U_U55X_MY2022_Tx" SG_ 1438 GWM_AutoSarNMReserved3 1;
BA_ "U_CD542_MY2021_Tx" SG_ 1438 GWM_AutoSarNMReserved3 1;
BA_ "ECGUsedTxSignal" SG_ 1438 GWM_AutoSarNMReserved3 1;
BA_ "U_T6_MCA_MY2020_Tx" SG_ 1438 GWM_AutoSarNMReserved3 1;
BA_ "U_CD764_MY2022_Rx" SG_ 1438 GWM_AutoSarNMReserved3 1;
BA_ "U_CD542_MY2021_Rx" SG_ 1438 GWM_AutoSarNMReserved3 1;
BA_ "U_P702_MY2021_Rx" SG_ 1438 GWM_AutoSarNMReserved3 1;
BA_ "U_CX727_MY2021_Rx" SG_ 1438 GWM_AutoSarNMReserved3 1;
BA_ "U_U55X_MY2022_Rx" SG_ 1438 GWM_AutoSarNMReserved3 1;
BA_ "U_T6_MCA_MY2020_Rx" SG_ 1438 GWM_AutoSarNMReserved3 1;
BA_ "GenSigStartValue" SG_ 1438 GWM_AutoSarNMReserved3 255;
BA_ "ContentDependant" SG_ 1438 GWM_AutoSarNMReserved3 1;
BA_ "GenSigStartValueInteger" SG_ 1438 GWM_AutoSarNMReserved3 255;
BA_ "U_CD764_MY2022_Tx" SG_ 1438 GWM_AutoSarNMReserved2 1;
BA_ "U_U55X_MY2022_Tx" SG_ 1438 GWM_AutoSarNMReserved2 1;
BA_ "U_CD542_MY2021_Tx" SG_ 1438 GWM_AutoSarNMReserved2 1;
BA_ "ECGUsedTxSignal" SG_ 1438 GWM_AutoSarNMReserved2 1;
BA_ "U_T6_MCA_MY2020_Tx" SG_ 1438 GWM_AutoSarNMReserved2 1;
BA_ "U_CD764_MY2022_Rx" SG_ 1438 GWM_AutoSarNMReserved2 1;
BA_ "U_CD542_MY2021_Rx" SG_ 1438 GWM_AutoSarNMReserved2 1;
BA_ "U_P702_MY2021_Rx" SG_ 1438 GWM_AutoSarNMReserved2 1;
BA_ "U_CX727_MY2021_Rx" SG_ 1438 GWM_AutoSarNMReserved2 1;
BA_ "U_U55X_MY2022_Rx" SG_ 1438 GWM_AutoSarNMReserved2 1;
BA_ "U_T6_MCA_MY2020_Rx" SG_ 1438 GWM_AutoSarNMReserved2 1;
BA_ "GenSigStartValue" SG_ 1438 GWM_AutoSarNMReserved2 255;
BA_ "ContentDependant" SG_ 1438 GWM_AutoSarNMReserved2 1;
BA_ "GenSigStartValueInteger" SG_ 1438 GWM_AutoSarNMReserved2 255;
BA_ "U_CD764_MY2022_Tx" SG_ 1438 GWM_AutoSarNMReserved1 1;
BA_ "U_U55X_MY2022_Tx" SG_ 1438 GWM_AutoSarNMReserved1 1;
BA_ "U_CD542_MY2021_Tx" SG_ 1438 GWM_AutoSarNMReserved1 1;
BA_ "ECGUsedTxSignal" SG_ 1438 GWM_AutoSarNMReserved1 1;
BA_ "U_T6_MCA_MY2020_Tx" SG_ 1438 GWM_AutoSarNMReserved1 1;
BA_ "U_CD764_MY2022_Rx" SG_ 1438 GWM_AutoSarNMReserved1 1;
BA_ "U_CD542_MY2021_Rx" SG_ 1438 GWM_AutoSarNMReserved1 1;
BA_ "U_P702_MY2021_Rx" SG_ 1438 GWM_AutoSarNMReserved1 1;
BA_ "U_CX727_MY2021_Rx" SG_ 1438 GWM_AutoSarNMReserved1 1;
BA_ "U_U55X_MY2022_Rx" SG_ 1438 GWM_AutoSarNMReserved1 1;
BA_ "U_T6_MCA_MY2020_Rx" SG_ 1438 GWM_AutoSarNMReserved1 1;
BA_ "GenSigStartValue" SG_ 1438 GWM_AutoSarNMReserved1 255;
BA_ "ContentDependant" SG_ 1438 GWM_AutoSarNMReserved1 1;
BA_ "GenSigStartValueInteger" SG_ 1438 GWM_AutoSarNMReserved1 255;
BA_ "U_CD764_MY2022_Tx" SG_ 1438 GWM_AutoSarNMNodeId 1;
BA_ "U_U55X_MY2022_Tx" SG_ 1438 GWM_AutoSarNMNodeId 1;
BA_ "U_CD542_MY2021_Tx" SG_ 1438 GWM_AutoSarNMNodeId 1;
BA_ "ECGUsedTxSignal" SG_ 1438 GWM_AutoSarNMNodeId 1;
BA_ "U_T6_MCA_MY2020_Tx" SG_ 1438 GWM_AutoSarNMNodeId 1;
BA_ "U_CD764_MY2022_Rx" SG_ 1438 GWM_AutoSarNMNodeId 1;
BA_ "U_CD542_MY2021_Rx" SG_ 1438 GWM_AutoSarNMNodeId 1;
BA_ "U_P702_MY2021_Rx" SG_ 1438 GWM_AutoSarNMNodeId 1;
BA_ "U_CX727_MY2021_Rx" SG_ 1438 GWM_AutoSarNMNodeId 1;
BA_ "U_U55X_MY2022_Rx" SG_ 1438 GWM_AutoSarNMNodeId 1;
BA_ "U_T6_MCA_MY2020_Rx" SG_ 1438 GWM_AutoSarNMNodeId 1;
BA_ "GenSigStartValue" SG_ 1438 GWM_AutoSarNMNodeId 158;
BA_ "ContentDependant" SG_ 1438 GWM_AutoSarNMNodeId 1;
BA_ "GenSigStartValueInteger" SG_ 1438 GWM_AutoSarNMNodeId 158;
BA_ "U_CD764_MY2022_Tx" SG_ 1438 GWM_AutoSarNMControl 1;
BA_ "U_U55X_MY2022_Tx" SG_ 1438 GWM_AutoSarNMControl 1;
BA_ "U_CD542_MY2021_Tx" SG_ 1438 GWM_AutoSarNMControl 1;
BA_ "ECGUsedTxSignal" SG_ 1438 GWM_AutoSarNMControl 1;
BA_ "U_T6_MCA_MY2020_Tx" SG_ 1438 GWM_AutoSarNMControl 1;
BA_ "U_CD764_MY2022_Rx" SG_ 1438 GWM_AutoSarNMControl 1;
BA_ "U_CD542_MY2021_Rx" SG_ 1438 GWM_AutoSarNMControl 1;
BA_ "U_P702_MY2021_Rx" SG_ 1438 GWM_AutoSarNMControl 1;
BA_ "U_CX727_MY2021_Rx" SG_ 1438 GWM_AutoSarNMControl 1;
BA_ "U_U55X_MY2022_Rx" SG_ 1438 GWM_AutoSarNMControl 1;
BA_ "U_T6_MCA_MY2020_Rx" SG_ 1438 GWM_AutoSarNMControl 1;
BA_ "ContentDependant" SG_ 1438 GWM_AutoSarNMControl 1;
BA_ "GenSigSendType" SG_ 841 FohStrtDateDay_No_Stat 3;
BA_ "GenSigSendType" SG_ 841 FohStrtDateYr_No_Stat 3;
BA_ "GenSigSendType" SG_ 841 FohAddHeater_D_Stat 3;
BA_ "U_CD764_MY2022_Rx" SG_ 1075 ACU_RadioSeekMode2_St 1;
BA_ "U_P702_MY2021_Rx" SG_ 1075 ACU_RadioSeekMode2_St 1;
BA_ "U_U55X_MY2022_Rx" SG_ 1075 ACU_RadioSeekMode2_St 1;
BA_ "U_CD542_MY2021_Rx" SG_ 1075 ACU_RadioSeekMode2_St 1;
BA_ "U_T6_MCA_MY2020_Rx" SG_ 1075 ACU_RadioSeekMode2_St 1;
BA_ "U_CX727_MY2021_Rx" SG_ 1075 ACU_RadioSeekMode2_St 1;
BA_ "GenSigSendType" SG_ 1075 ACU_RadioSeekMode2_St 3;
BA_ "U_CD764_MY2022_Rx" SG_ 1075 ACU_CurrTUBand_St 1;
BA_ "U_P702_MY2021_Rx" SG_ 1075 ACU_CurrTUBand_St 1;
BA_ "U_U55X_MY2022_Rx" SG_ 1075 ACU_CurrTUBand_St 1;
BA_ "U_CD542_MY2021_Rx" SG_ 1075 ACU_CurrTUBand_St 1;
BA_ "U_T6_MCA_MY2020_Rx" SG_ 1075 ACU_CurrTUBand_St 1;
BA_ "U_CX727_MY2021_Rx" SG_ 1075 ACU_CurrTUBand_St 1;
BA_ "GenSigSendType" SG_ 1075 ACU_CurrTUBand_St 3;
BA_ "U_CD764_MY2022_Rx" SG_ 1075 ACU_CurrentFreq_St 1;
BA_ "U_P702_MY2021_Rx" SG_ 1075 ACU_CurrentFreq_St 1;
BA_ "U_U55X_MY2022_Rx" SG_ 1075 ACU_CurrentFreq_St 1;
BA_ "U_CD542_MY2021_Rx" SG_ 1075 ACU_CurrentFreq_St 1;
BA_ "U_T6_MCA_MY2020_Rx" SG_ 1075 ACU_CurrentFreq_St 1;
BA_ "U_CX727_MY2021_Rx" SG_ 1075 ACU_CurrentFreq_St 1;
BA_ "U_CD764_MY2022_Rx" SG_ 1075 ACU_RadioSeekMode2_St_UB 1;
BA_ "U_P702_MY2021_Rx" SG_ 1075 ACU_RadioSeekMode2_St_UB 1;
BA_ "U_U55X_MY2022_Rx" SG_ 1075 ACU_RadioSeekMode2_St_UB 1;
BA_ "U_CD542_MY2021_Rx" SG_ 1075 ACU_RadioSeekMode2_St_UB 1;
BA_ "U_T6_MCA_MY2020_Rx" SG_ 1075 ACU_RadioSeekMode2_St_UB 1;
BA_ "U_CX727_MY2021_Rx" SG_ 1075 ACU_RadioSeekMode2_St_UB 1;
BA_ "U_CD764_MY2022_Rx" SG_ 1075 ACU_CurrTUBand_St_UB 1;
BA_ "U_P702_MY2021_Rx" SG_ 1075 ACU_CurrTUBand_St_UB 1;
BA_ "U_U55X_MY2022_Rx" SG_ 1075 ACU_CurrTUBand_St_UB 1;
BA_ "U_CD542_MY2021_Rx" SG_ 1075 ACU_CurrTUBand_St_UB 1;
BA_ "U_T6_MCA_MY2020_Rx" SG_ 1075 ACU_CurrTUBand_St_UB 1;
BA_ "U_CX727_MY2021_Rx" SG_ 1075 ACU_CurrTUBand_St_UB 1;
BA_ "U_CD764_MY2022_Rx" SG_ 1075 ACU_CurrentFreq_St_UB 1;
BA_ "U_P702_MY2021_Rx" SG_ 1075 ACU_CurrentFreq_St_UB 1;
BA_ "U_U55X_MY2022_Rx" SG_ 1075 ACU_CurrentFreq_St_UB 1;
BA_ "U_CD542_MY2021_Rx" SG_ 1075 ACU_CurrentFreq_St_UB 1;
BA_ "U_T6_MCA_MY2020_Rx" SG_ 1075 ACU_CurrentFreq_St_UB 1;
BA_ "U_CX727_MY2021_Rx" SG_ 1075 ACU_CurrentFreq_St_UB 1;
BA_ "U_CX727_MY2021_Rx" SG_ 1075 CtaBrk_D_Stat_UB 1;
BA_ "U_CX727_MY2021_Rx" SG_ 1075 CtaBrk_D_Stat 1;
BA_ "GenSigSendType" SG_ 1075 CtaBrk_D_Stat 3;
BA_ "U_CD764_MY2022_Rx" SG_ 1075 SelDrvMdePt_D_Rq_UB 1;
BA_ "U_U55X_MY2022_Rx" SG_ 1075 SelDrvMdePt_D_Rq_UB 1;
BA_ "U_CD542_MY2021_Rx" SG_ 1075 SelDrvMdePt_D_Rq_UB 1;
BA_ "U_CX727_MY2021_Rx" SG_ 1075 SelDrvMdePt_D_Rq_UB 1;
BA_ "U_CD764_MY2022_Rx" SG_ 1075 SelDrvMdePt_D_Rq 1;
BA_ "U_U55X_MY2022_Rx" SG_ 1075 SelDrvMdePt_D_Rq 1;
BA_ "U_CD542_MY2021_Rx" SG_ 1075 SelDrvMdePt_D_Rq 1;
BA_ "U_CX727_MY2021_Rx" SG_ 1075 SelDrvMdePt_D_Rq 1;
BA_ "GenSigSendType" SG_ 1075 SelDrvMdePt_D_Rq 3;
BA_ "GenSigSendType" SG_ 1075 PrkAidSnsRrCrnr_D_Stat 3;
BA_ "GenSigSendType" SG_ 1075 PrkAidSnsRrCntr_D_Stat 3;
BA_ "GenSigSendType" SG_ 1075 PrkAidSnsRlCrnr_D_Stat 3;
BA_ "GenSigSendType" SG_ 1075 PrkAidSnsRlCntr_D_Stat 3;
BA_ "GenSigSendType" SG_ 1075 BttOn_B_Rq 3;
BA_ "GenSigStartValue" SG_ 1075 Btt_L_Actl 126;
BA_ "GenSigStartValueInteger" SG_ 1075 Btt_L_Actl 126;
BA_ "GenSigSendType" SG_ 1075 ArmrestStwdRear_B_Stat 3;
BA_ "GenSigStartValue" SG_ 1075 ArmrestStwdRear_B_Stat 1;
BA_ "GenSigStartValueInteger" SG_ 1075 ArmrestStwdRear_B_Stat 1;
BA_ "GenSigSendType" SG_ 1166 DrHandleInnrRr_B_Stat 3;
BA_ "GenSigSendType" SG_ 1166 DrSwtchInnrRr_No_Rq 3;
BA_ "WakeupSignal" SG_ 1166 DrSwtchInnrRr_No_Rq 1;
BA_ "GenSigSendType" SG_ 1166 DrLatchRolCdRr_No_Locl 3;
BA_ "GenSigSendType" SG_ 1166 DrLatchRrMsgTxt_D_Rq 3;
BA_ "GenSigSendType" SG_ 1166 DrLatchRr_B_Falt 3;
BA_ "GenSigSendType" SG_ 1166 DrLatchLckRr_B_Stat 3;
BA_ "GenSigSendType" SG_ 1166 ChildLckFdbckRr_B_Stat 3;
BA_ "GenSigSendType" SG_ 1165 DrHandleInnrRl_B_Stat 3;
BA_ "GenSigSendType" SG_ 1165 DrSwtchInnrRl_No_Rq 3;
BA_ "WakeupSignal" SG_ 1165 DrSwtchInnrRl_No_Rq 1;
BA_ "GenSigSendType" SG_ 1165 DrLatchRolCdRl_No_Locl 3;
BA_ "GenSigSendType" SG_ 1165 DrLatchRlMsgTxt_D_Rq 3;
BA_ "GenSigSendType" SG_ 1165 DrLatchRl_B_Falt 3;
BA_ "GenSigSendType" SG_ 1165 DrLatchLckRl_B_Stat 3;
BA_ "GenSigSendType" SG_ 1165 ChildLckFdbckRl_B_Stat 3;
BA_ "GenSigSendType" SG_ 1164 DrHandleInnrFr_B_Stat 3;
BA_ "GenSigSendType" SG_ 1164 DrSwtchInnrFr_No_Rq 3;
BA_ "WakeupSignal" SG_ 1164 DrSwtchInnrFr_No_Rq 1;
BA_ "GenSigSendType" SG_ 1164 DrLatchRolCdFr_No_Locl 3;
BA_ "GenSigSendType" SG_ 1164 DrLatchLckFr_B_Stat 3;
BA_ "GenSigSendType" SG_ 1164 DrLatchFrMsgTxt_D_Rq 3;
BA_ "GenSigSendType" SG_ 1164 DrLatchFr_B_Falt 3;
BA_ "GenSigSendType" SG_ 1163 DrHandleInnrFl_B_Stat 3;
BA_ "GenSigSendType" SG_ 1163 DrSwtchInnrFl_No_Rq 3;
BA_ "WakeupSignal" SG_ 1163 DrSwtchInnrFl_No_Rq 1;
BA_ "GenSigSendType" SG_ 1163 DrLatchRolCdFl_No_Locl 3;
BA_ "GenSigSendType" SG_ 1163 DrLatchLckFl_B_Stat 3;
BA_ "GenSigSendType" SG_ 1163 DrLatchFlMsgTxt_D_Rq 3;
BA_ "GenSigSendType" SG_ 1163 DrLatchFl_B_Falt 3;
BA_ "U_U55X_MY2022_Tx" SG_ 1162 SteClmnPos_D_Stat 1;
BA_ "GenSigSendType" SG_ 1162 SteClmnPos_D_Stat 3;
BA_ "GenSigSendType" SG_ 1162 PersIndexBcmb_D_Actl 3;
BA_ "GenSigStartValue" SG_ 1162 PersIndexBcmb_D_Actl 4;
BA_ "GenSigStartValueInteger" SG_ 1162 PersIndexBcmb_D_Actl 4;
BA_ "GenSigSendType" SG_ 1162 MemDrvDeny_B_StatCapm 3;
BA_ "WakeupSignal" SG_ 1162 MemDrvDeny_B_StatCapm 1;
BA_ "U_U55X_MY2022_Tx" SG_ 1162 Cancl_Auto_Movmnt_CAPM 1;
BA_ "GenSigSendType" SG_ 1162 Cancl_Auto_Movmnt_CAPM 3;
BA_ "WakeupSignal" SG_ 1162 Cancl_Auto_Movmnt_CAPM 1;
BA_ "GenSigSendType" SG_ 1961 TesterPhysicalResGFM_FTRM 3;
BA_ "GenSigSendType" SG_ 1954 TesterPhysicalReqDCME 3;
BA_ "GenSigSendType" SG_ 1972 TesterPhysicalReqDCMH 3;
BA_ "U_U55X_MY2022_Tx" SG_ 1963 TesterPhysicalResSCMB_PSM 1;
BA_ "GenSigSendType" SG_ 1963 TesterPhysicalResSCMB_PSM 3;
BA_ "U_U55X_MY2022_Rx" SG_ 1955 TesterPhysicalReqSCMB_PSM 1;
BA_ "GenSigSendType" SG_ 1955 TesterPhysicalReqSCMB_PSM 3;
BA_ "GenSigSendType" SG_ 1953 TesterPhysicalReqGFM_FTRM 3;
BA_ "U_U55X_MY2022_Rx" SG_ 1891 TesterPhysicalReqSCMD 1;
BA_ "GenSigSendType" SG_ 1891 TesterPhysicalReqSCMD 3;
BA_ "U_U55X_MY2022_Rx" SG_ 1794 TesterPhysicalReqSCMC 1;
BA_ "GenSigSendType" SG_ 1794 TesterPhysicalReqSCMC 3;
BA_ "GenSigSendType" SG_ 1356 MRCMB_Network_Mgmt 3;
BA_ "GenSigSendType" SG_ 978 CnvtTopTWarn_B_Falt 3;
BA_ "GenSigSendType" SG_ 978 CnvtTopTOvr_B_Falt 3;
BA_ "GenSigSendType" SG_ 978 CnvtTopTDir_B_Falt 3;
BA_ "GenSigSendType" SG_ 978 CnvtTopStall_B_Falt 3;
BA_ "GenSigSendType" SG_ 978 CnvtTopSns_B_Falt 3;
BA_ "GenSigSendType" SG_ 978 CnvtTopRvrse_B_Stat 3;
BA_ "GenSigSendType" SG_ 978 CnvtTopRngOpen_B_Stat 3;
BA_ "ContentDependant" SG_ 978 CnvtTopRngOpen_B_Stat 1;
BA_ "GenSigSendType" SG_ 978 CnvtTopRngClose_B_Stat 3;
BA_ "ContentDependant" SG_ 978 CnvtTopRngClose_B_Stat 1;
BA_ "GenSigSendType" SG_ 978 CnvtTopRestrc_B_Falt 3;
BA_ "GenSigSendType" SG_ 978 CnvtTopRdy_B_Stat 3;
BA_ "GenSigSendType" SG_ 978 CnvtTopPosSet_B_Stat 3;
BA_ "GenSigSendType" SG_ 978 CnvtTopPos_No_Actl 3;
BA_ "GenSigSendType" SG_ 978 CnvtTopPos_D_Stat 3;
BA_ "GenSigStartValue" SG_ 978 CnvtTopPos_D_Stat 7;
BA_ "GenSigStartValueInteger" SG_ 978 CnvtTopPos_D_Stat 7;
BA_ "GenSigSendType" SG_ 978 CnvtTopPos_B_Falt 3;
BA_ "GenSigSendType" SG_ 978 CnvtTopOut_B_Falt 3;
BA_ "GenSigSendType" SG_ 978 CnvtTopOpen_D_Stat 3;
BA_ "GenSigSendType" SG_ 978 CnvtTopOpen_B_Stat 3;
BA_ "GenSigSendType" SG_ 978 CnvtTopNom_B_Stat 3;
BA_ "GenSigSendType" SG_ 978 CnvtTopDir_B_Falt 3;
BA_ "GenSigSendType" SG_ 978 CnvtTopComplt_No_Cnt 3;
BA_ "GenSigSendType" SG_ 978 CnvtTopComplt_D_Stat 3;
BA_ "GenSigSendType" SG_ 978 CnvtTopCnfm_B_Stat 3;
BA_ "GenSigSendType" SG_ 978 CnvtTopClose_D_Stat 3;
BA_ "GenSigSendType" SG_ 978 CnvtTopActv_B_Stat 3;
BA_ "GenSigSendType" SG_ 978 TonneuCapMde_D_Stat 3;
BA_ "GenSigSendType" SG_ 977 CnvtTopTrgt_D_Rq 3;
BA_ "GenSigSendType" SG_ 977 CnvtTopSleepActv_B_Rq 3;
BA_ "ContentDependant" SG_ 977 CnvtTopSleepActv_B_Rq 1;
BA_ "GenSigSendType" SG_ 977 CnvtTopPos_No_Rq 3;
BA_ "GenSigSendType" SG_ 977 CnvtTopPar_D_Rq 3;
BA_ "GenSigSendType" SG_ 977 CnvtTopBrkActv_B_Rq 3;
BA_ "ContentDependant" SG_ 977 CnvtTopBrkActv_B_Rq 1;
BA_ "GenSigSendType" SG_ 977 CnvtTop_No_Cnt 3;
BA_ "GenSigSendType" SG_ 977 CnvtTop_D_Rq 3;
BA_ "GenSigSendType" SG_ 977 CnvtTopPos_Up_Stat 3;
BA_ "ContentDependant" SG_ 977 CnvtTopPos_Up_Stat 1;
BA_ "WakeupSignal" SG_ 977 CnvtTopPos_Up_Stat 1;
BA_ "GenSigSendType" SG_ 977 CnvtTopMsgTxt_D_Rq 3;
BA_ "WakeupSignal" SG_ 977 CnvtTopMsgTxt_D_Rq 1;
BA_ "GenSigSendType" SG_ 977 WndwCnvtTopDrop_B_Cmd 3;
BA_ "GenSigSendType" SG_ 977 CnvtTopPos_Dn_Stat 3;
BA_ "ContentDependant" SG_ 977 CnvtTopPos_Dn_Stat 1;
BA_ "WakeupSignal" SG_ 977 CnvtTopPos_Dn_Stat 1;
BA_ "GenSigSendType" SG_ 1976 TesterPhysicalResMRCMB 3;
BA_ "U_T6_MCA_MY2020_Tx" SG_ 1944 TesterPhysicalResMRCMA 1;
BA_ "GenSigSendType" SG_ 1944 TesterPhysicalResMRCMA 3;
BA_ "GenSigSendType" SG_ 1968 TesterPhysicalReqMRCMB 3;
BA_ "U_T6_MCA_MY2020_Rx" SG_ 1936 TesterPhysicalReqMRCMA 1;
BA_ "GenSigSendType" SG_ 1936 TesterPhysicalReqMRCMA 3;
BA_ "GenSigStartValue" SG_ 968 SlMde_D_Rq 2;
BA_ "GenSigStartValueInteger" SG_ 968 SlMde_D_Rq 2;
BA_ "GenSigStartValue" SG_ 968 IsaOffst_D_Rq 14;
BA_ "GenSigStartValueInteger" SG_ 968 IsaOffst_D_Rq 14;
BA_ "GenSigStartValue" SG_ 968 CurrentColor_CmdGage 8;
BA_ "GenSigStartValueInteger" SG_ 968 CurrentColor_CmdGage 8;
BA_ "GenSigStartValue" SG_ 968 BlendedColor_CmdGage 2;
BA_ "GenSigStartValueInteger" SG_ 968 BlendedColor_CmdGage 2;
BA_ "GenSigStartValue" SG_ 968 Current_Color_Cmd 8;
BA_ "GenSigStartValueInteger" SG_ 968 Current_Color_Cmd 8;
BA_ "GenSigStartValue" SG_ 968 BlendedColor_Cmd 2;
BA_ "GenSigStartValueInteger" SG_ 968 BlendedColor_Cmd 2;
BA_ "GenSigSendType" SG_ 1971 TesterPhysicalReqDCMG 3;
BA_ "GenSigSendType" SG_ 1890 TesterPhysicalReqDCMF 3;
BA_ "GenSigSendType" SG_ 1980 TesterPhysicalResDCMH 3;
BA_ "GenSigSendType" SG_ 1979 TesterPhysicalResDCMG 3;
BA_ "GenSigSendType" SG_ 852 SeatMasgPsngrRr_D_Rq 3;
BA_ "GenSigSendType" SG_ 852 SeatFnPsgr_D_Rq2 3;
BA_ "GenSigSendType" SG_ 852 SeatFnChngPsgr2_D_Rq2 3;
BA_ "GenSigSendType" SG_ 851 SeatMasgDrvRr_D_Rq 3;
BA_ "GenSigSendType" SG_ 851 SeatFnDrv_D_Rq2 3;
BA_ "GenSigSendType" SG_ 851 SeatFnChngDrv2_D_Rq2 3;
BA_ "U_U55X_MY2022_Tx" SG_ 876 SeatIntnsPsngrRr_D_Stat 1;
BA_ "GenSigSendType" SG_ 876 SeatIntnsPsngrRr_D_Stat 3;
BA_ "U_U55X_MY2022_Tx" SG_ 876 SeatMasgPsngrRr_D_Stat 1;
BA_ "GenSigSendType" SG_ 876 SeatMasgPsngrRr_D_Stat 3;
BA_ "U_U55X_MY2022_Tx" SG_ 876 SeatSwtchRr_B_Stat 1;
BA_ "GenSigSendType" SG_ 876 SeatSwtchRr_B_Stat 3;
BA_ "U_U55X_MY2022_Tx" SG_ 876 SeatPRr_B_Stat 1;
BA_ "GenSigSendType" SG_ 876 SeatPRr_B_Stat 3;
BA_ "U_U55X_MY2022_Tx" SG_ 876 SeatLmbrUpRr_Pc_Actl 1;
BA_ "GenSigSendType" SG_ 876 SeatLmbrUpRr_Pc_Actl 3;
BA_ "GenSigStartValue" SG_ 876 SeatLmbrUpRr_Pc_Actl 127;
BA_ "GenSigStartValueInteger" SG_ 876 SeatLmbrUpRr_Pc_Actl 127;
BA_ "U_U55X_MY2022_Tx" SG_ 876 SeatLmbrMidRr_Pc_Actl 1;
BA_ "GenSigSendType" SG_ 876 SeatLmbrMidRr_Pc_Actl 3;
BA_ "GenSigStartValue" SG_ 876 SeatLmbrMidRr_Pc_Actl 127;
BA_ "GenSigStartValueInteger" SG_ 876 SeatLmbrMidRr_Pc_Actl 127;
BA_ "U_U55X_MY2022_Tx" SG_ 876 SeatLmbrLoRr_Pc_Actl 1;
BA_ "GenSigSendType" SG_ 876 SeatLmbrLoRr_Pc_Actl 3;
BA_ "GenSigStartValue" SG_ 876 SeatLmbrLoRr_Pc_Actl 127;
BA_ "GenSigStartValueInteger" SG_ 876 SeatLmbrLoRr_Pc_Actl 127;
BA_ "U_U55X_MY2022_Tx" SG_ 876 SeatFnRr_D_Stat 1;
BA_ "GenSigSendType" SG_ 876 SeatFnRr_D_Stat 3;
BA_ "U_U55X_MY2022_Tx" SG_ 876 StmsCshnPsgr_D_Stat2 1;
BA_ "GenSigSendType" SG_ 876 StmsCshnPsgr_D_Stat2 3;
BA_ "U_U55X_MY2022_Tx" SG_ 876 StmsLmbrPsgr_D_Stat2 1;
BA_ "GenSigSendType" SG_ 876 StmsLmbrPsgr_D_Stat2 3;
BA_ "GenSigStartValue" SG_ 1045 VehStab_D_Stat 14;
BA_ "GenSigStartValueInteger" SG_ 1045 VehStab_D_Stat 14;
BA_ "GenSigStartValue" SG_ 1045 VehYawNonLin_W_Rq 4094;
BA_ "GenSigStartValueInteger" SG_ 1045 VehYawNonLin_W_Rq 4094;
BA_ "GenSigStartValue" SG_ 1045 VehYawLin_W_Rq 4094;
BA_ "GenSigStartValueInteger" SG_ 1045 VehYawLin_W_Rq 4094;
BA_ "U_U55X_MY2022_Rx" SG_ 1045 VehVActlBrk_No_Cs 1;
BA_ "U_CD542_MY2021_Rx" SG_ 1045 VehVActlBrk_No_Cs 1;
BA_ "U_T6_MCA_MY2020_Rx" SG_ 1045 VehVActlBrk_No_Cs 1;
BA_ "U_P702_MY2021_Rx" SG_ 1045 VehVActlBrk_No_Cs 1;
BA_ "MetaData" SG_ 1045 VehVActlBrk_No_Cs 1;
BA_ "U_U55X_MY2022_Rx" SG_ 1045 Veh_V_ActlBrk 1;
BA_ "U_CD542_MY2021_Rx" SG_ 1045 Veh_V_ActlBrk 1;
BA_ "U_T6_MCA_MY2020_Rx" SG_ 1045 Veh_V_ActlBrk 1;
BA_ "U_P702_MY2021_Rx" SG_ 1045 Veh_V_ActlBrk 1;
BA_ "U_U55X_MY2022_Rx" SG_ 1045 VehVActlBrk_No_Cnt 1;
BA_ "U_CD542_MY2021_Rx" SG_ 1045 VehVActlBrk_No_Cnt 1;
BA_ "U_T6_MCA_MY2020_Rx" SG_ 1045 VehVActlBrk_No_Cnt 1;
BA_ "U_P702_MY2021_Rx" SG_ 1045 VehVActlBrk_No_Cnt 1;
BA_ "MetaData" SG_ 1045 VehVActlBrk_No_Cnt 1;
BA_ "U_U55X_MY2022_Rx" SG_ 1045 VehVActlBrk_D_Qf 1;
BA_ "U_CD542_MY2021_Rx" SG_ 1045 VehVActlBrk_D_Qf 1;
BA_ "U_T6_MCA_MY2020_Rx" SG_ 1045 VehVActlBrk_D_Qf 1;
BA_ "U_P702_MY2021_Rx" SG_ 1045 VehVActlBrk_D_Qf 1;
BA_ "MetaData" SG_ 1045 VehVActlBrk_D_Qf 1;
BA_ "U_P702_MY2021_Tx" SG_ 1189 PwStepMsgTxt_D_Rq 1;
BA_ "U_U55X_MY2022_Tx" SG_ 1189 PwStepMsgTxt_D_Rq 1;
BA_ "GenSigSendType" SG_ 1189 PwStepMsgTxt_D_Rq 3;
BA_ "U_U55X_MY2022_Tx" SG_ 1189 Running_Board_Stat 1;
BA_ "U_P702_MY2021_Tx" SG_ 1189 Running_Board_Stat 1;
BA_ "GenSigSendType" SG_ 1189 Running_Board_Stat 3;
BA_ "U_P702_MY2021_Tx" SG_ 1189 PwStep_D_Stat 1;
BA_ "U_U55X_MY2022_Tx" SG_ 1189 PwStep_D_Stat 1;
BA_ "GenSigSendType" SG_ 1189 PwStep_D_Stat 3;
BA_ "U_T6_MCA_MY2020_Tx" SG_ 858 ClimtSyncRear_B_Stat 1;
BA_ "GenSigSendType" SG_ 858 ClimtSyncRear_B_Stat 3;
BA_ "U_T6_MCA_MY2020_Tx" SG_ 858 ClimtSeatHeatRr_B_Stat 1;
BA_ "GenSigSendType" SG_ 858 ClimtSeatHeatRr_B_Stat 3;
BA_ "U_T6_MCA_MY2020_Tx" SG_ 858 ClimtSeatHeatRl_B_Stat 1;
BA_ "GenSigSendType" SG_ 858 ClimtSeatHeatRl_B_Stat 3;
BA_ "U_T6_MCA_MY2020_Tx" SG_ 858 ClimtSeatCoolRr_B_Stat 1;
BA_ "GenSigSendType" SG_ 858 ClimtSeatCoolRr_B_Stat 3;
BA_ "U_T6_MCA_MY2020_Tx" SG_ 858 ClimtSeatCoolRl_B_Stat 1;
BA_ "GenSigSendType" SG_ 858 ClimtSeatCoolRl_B_Stat 3;
BA_ "U_T6_MCA_MY2020_Tx" SG_ 858 ClimtRearTe3rd_D_Stat 1;
BA_ "GenSigSendType" SG_ 858 ClimtRearTe3rd_D_Stat 3;
BA_ "U_T6_MCA_MY2020_Tx" SG_ 858 ClimtRearPw3rd_B_Stat 1;
BA_ "GenSigSendType" SG_ 858 ClimtRearPw3rd_B_Stat 3;
BA_ "U_T6_MCA_MY2020_Tx" SG_ 858 ClimtRearPnl3rd_B_Stat 1;
BA_ "GenSigSendType" SG_ 858 ClimtRearPnl3rd_B_Stat 3;
BA_ "U_T6_MCA_MY2020_Tx" SG_ 858 ClimtRearPf3rd_B_Stat 1;
BA_ "GenSigSendType" SG_ 858 ClimtRearPf3rd_B_Stat 3;
BA_ "U_T6_MCA_MY2020_Tx" SG_ 858 ClimtRearFlr3rd_B_Stat 1;
BA_ "GenSigSendType" SG_ 858 ClimtRearFlr3rd_B_Stat 3;
BA_ "U_T6_MCA_MY2020_Tx" SG_ 858 ClimtRearBlwr3rd_D_Stat 1;
BA_ "GenSigSendType" SG_ 858 ClimtRearBlwr3rd_D_Stat 3;
BA_ "U_T6_MCA_MY2020_Tx" SG_ 858 ClimtRearAuto3rd_B_Stat 1;
BA_ "GenSigSendType" SG_ 858 ClimtRearAuto3rd_B_Stat 3;
BA_ "U_T6_MCA_MY2020_Tx" SG_ 858 ClimtRearViewR_D_Stat 1;
BA_ "GenSigSendType" SG_ 858 ClimtRearViewR_D_Stat 3;
BA_ "U_U55X_MY2022_Tx" SG_ 858 ClimtRearTe_D_Stat 1;
BA_ "U_T6_MCA_MY2020_Tx" SG_ 858 ClimtRearTe_D_Stat 1;
BA_ "U_T6_MCA_MY2020_Rx" SG_ 858 ClimtRearTe_D_Stat 1;
BA_ "U_U55X_MY2022_Rx" SG_ 858 ClimtRearTe_D_Stat 1;
BA_ "GenSigSendType" SG_ 858 ClimtRearTe_D_Stat 3;
BA_ "U_U55X_MY2022_Tx" SG_ 858 ClimtRearTe_An_Actl 1;
BA_ "U_T6_MCA_MY2020_Tx" SG_ 858 ClimtRearTe_An_Actl 1;
BA_ "U_T6_MCA_MY2020_Rx" SG_ 858 ClimtRearTe_An_Actl 1;
BA_ "U_U55X_MY2022_Rx" SG_ 858 ClimtRearTe_An_Actl 1;
BA_ "GenSigSendType" SG_ 858 ClimtRearTe_An_Actl 3;
BA_ "GenSigStartValue" SG_ 858 ClimtRearTe_An_Actl 511;
BA_ "GenSigStartValueInteger" SG_ 858 ClimtRearTe_An_Actl 511;
BA_ "U_U55X_MY2022_Tx" SG_ 858 ClimtRearPw_B_Stat 1;
BA_ "U_T6_MCA_MY2020_Tx" SG_ 858 ClimtRearPw_B_Stat 1;
BA_ "U_T6_MCA_MY2020_Rx" SG_ 858 ClimtRearPw_B_Stat 1;
BA_ "U_U55X_MY2022_Rx" SG_ 858 ClimtRearPw_B_Stat 1;
BA_ "GenSigSendType" SG_ 858 ClimtRearPw_B_Stat 3;
BA_ "U_U55X_MY2022_Tx" SG_ 858 ClimtRearPnlFlr_B_Stat 1;
BA_ "U_T6_MCA_MY2020_Tx" SG_ 858 ClimtRearPnlFlr_B_Stat 1;
BA_ "U_T6_MCA_MY2020_Rx" SG_ 858 ClimtRearPnlFlr_B_Stat 1;
BA_ "U_U55X_MY2022_Rx" SG_ 858 ClimtRearPnlFlr_B_Stat 1;
BA_ "GenSigSendType" SG_ 858 ClimtRearPnlFlr_B_Stat 3;
BA_ "U_U55X_MY2022_Tx" SG_ 858 ClimtRearPnl_B_Stat 1;
BA_ "U_T6_MCA_MY2020_Tx" SG_ 858 ClimtRearPnl_B_Stat 1;
BA_ "U_T6_MCA_MY2020_Rx" SG_ 858 ClimtRearPnl_B_Stat 1;
BA_ "U_U55X_MY2022_Rx" SG_ 858 ClimtRearPnl_B_Stat 1;
BA_ "GenSigSendType" SG_ 858 ClimtRearPnl_B_Stat 3;
BA_ "U_U55X_MY2022_Tx" SG_ 858 ClimtRearFlr_B_Stat 1;
BA_ "U_T6_MCA_MY2020_Tx" SG_ 858 ClimtRearFlr_B_Stat 1;
BA_ "U_T6_MCA_MY2020_Rx" SG_ 858 ClimtRearFlr_B_Stat 1;
BA_ "U_U55X_MY2022_Rx" SG_ 858 ClimtRearFlr_B_Stat 1;
BA_ "GenSigSendType" SG_ 858 ClimtRearFlr_B_Stat 3;
BA_ "U_U55X_MY2022_Tx" SG_ 858 ClimtRearBlwr_D_Stat 1;
BA_ "U_T6_MCA_MY2020_Tx" SG_ 858 ClimtRearBlwr_D_Stat 1;
BA_ "U_T6_MCA_MY2020_Rx" SG_ 858 ClimtRearBlwr_D_Stat 1;
BA_ "U_U55X_MY2022_Rx" SG_ 858 ClimtRearBlwr_D_Stat 1;
BA_ "GenSigSendType" SG_ 858 ClimtRearBlwr_D_Stat 3;
BA_ "U_U55X_MY2022_Tx" SG_ 858 ClimtRearBlwr_An_Actl 1;
BA_ "U_T6_MCA_MY2020_Tx" SG_ 858 ClimtRearBlwr_An_Actl 1;
BA_ "U_T6_MCA_MY2020_Rx" SG_ 858 ClimtRearBlwr_An_Actl 1;
BA_ "U_U55X_MY2022_Rx" SG_ 858 ClimtRearBlwr_An_Actl 1;
BA_ "GenSigSendType" SG_ 858 ClimtRearBlwr_An_Actl 3;
BA_ "GenSigStartValue" SG_ 858 ClimtRearBlwr_An_Actl 511;
BA_ "GenSigStartValueInteger" SG_ 858 ClimtRearBlwr_An_Actl 511;
BA_ "U_U55X_MY2022_Tx" SG_ 858 ClimtRearAuto_B_Stat 1;
BA_ "U_T6_MCA_MY2020_Tx" SG_ 858 ClimtRearAuto_B_Stat 1;
BA_ "U_T6_MCA_MY2020_Rx" SG_ 858 ClimtRearAuto_B_Stat 1;
BA_ "U_U55X_MY2022_Rx" SG_ 858 ClimtRearAuto_B_Stat 1;
BA_ "GenSigSendType" SG_ 858 ClimtRearAuto_B_Stat 3;
BA_ "U_U55X_MY2022_Rx" SG_ 1925 TesterPhysicalReqRHVAC 1;
BA_ "U_T6_MCA_MY2020_Rx" SG_ 1925 TesterPhysicalReqRHVAC 1;
BA_ "GenSigSendType" SG_ 1925 TesterPhysicalReqRHVAC 3;
BA_ "U_U55X_MY2022_Tx" SG_ 1933 TesterPhysicalResRHVAC 1;
BA_ "U_T6_MCA_MY2020_Tx" SG_ 1933 TesterPhysicalResRHVAC 1;
BA_ "GenSigSendType" SG_ 1933 TesterPhysicalResRHVAC 3;
BA_ "U_CD764_MY2022_Tx" SG_ 2611120344 PARSEDPhysGWM_ECGtoDSM 1;
BA_ "U_U55X_MY2022_Tx" SG_ 2611120344 PARSEDPhysGWM_ECGtoDSM 1;
BA_ "U_CD542_MY2021_Tx" SG_ 2611120344 PARSEDPhysGWM_ECGtoDSM 1;
BA_ "ECGUsedTxSignal" SG_ 2611120344 PARSEDPhysGWM_ECGtoDSM 1;
BA_ "U_T6_MCA_MY2020_Tx" SG_ 2611120344 PARSEDPhysGWM_ECGtoDSM 1;
BA_ "U_U55X_MY2022_Rx" SG_ 2611120344 PARSEDPhysGWM_ECGtoDSM 1;
BA_ "U_CD542_MY2021_Rx" SG_ 2611120344 PARSEDPhysGWM_ECGtoDSM 1;
BA_ "U_T6_MCA_MY2020_Rx" SG_ 2611120344 PARSEDPhysGWM_ECGtoDSM 1;
BA_ "GenSigSendType" SG_ 2611120344 PARSEDPhysGWM_ECGtoDSM 3;
BA_ "U_U55X_MY2022_Tx" SG_ 2611175586 PARSEDPhysDSMtoGWM_ECG 1;
BA_ "U_CD542_MY2021_Tx" SG_ 2611175586 PARSEDPhysDSMtoGWM_ECG 1;
BA_ "U_T6_MCA_MY2020_Tx" SG_ 2611175586 PARSEDPhysDSMtoGWM_ECG 1;
BA_ "U_CD764_MY2022_Rx" SG_ 2611175586 PARSEDPhysDSMtoGWM_ECG 1;
BA_ "U_U55X_MY2022_Rx" SG_ 2611175586 PARSEDPhysDSMtoGWM_ECG 1;
BA_ "U_CD542_MY2021_Rx" SG_ 2611175586 PARSEDPhysDSMtoGWM_ECG 1;
BA_ "ECGUsedRxSignal" SG_ 2611175586 PARSEDPhysDSMtoGWM_ECG 1;
BA_ "U_T6_MCA_MY2020_Rx" SG_ 2611175586 PARSEDPhysDSMtoGWM_ECG 1;
BA_ "GenSigSendType" SG_ 2611175586 PARSEDPhysDSMtoGWM_ECG 3;
BA_ "U_U55X_MY2022_Tx" SG_ 2612224162 PARSEDPushDSMtoGWM_ECG 1;
BA_ "U_CD542_MY2021_Tx" SG_ 2612224162 PARSEDPushDSMtoGWM_ECG 1;
BA_ "U_T6_MCA_MY2020_Tx" SG_ 2612224162 PARSEDPushDSMtoGWM_ECG 1;
BA_ "U_CD764_MY2022_Rx" SG_ 2612224162 PARSEDPushDSMtoGWM_ECG 1;
BA_ "U_U55X_MY2022_Rx" SG_ 2612224162 PARSEDPushDSMtoGWM_ECG 1;
BA_ "U_CD542_MY2021_Rx" SG_ 2612224162 PARSEDPushDSMtoGWM_ECG 1;
BA_ "ECGUsedRxSignal" SG_ 2612224162 PARSEDPushDSMtoGWM_ECG 1;
BA_ "U_T6_MCA_MY2020_Rx" SG_ 2612224162 PARSEDPushDSMtoGWM_ECG 1;
BA_ "GenSigSendType" SG_ 2612224162 PARSEDPushDSMtoGWM_ECG 3;
BA_ "U_U55X_MY2022_Tx" SG_ 2610129112 OTAPhysGWM_ECGtoRTM 1;
BA_ "U_CD542_MY2021_Tx" SG_ 2610129112 OTAPhysGWM_ECGtoRTM 1;
BA_ "ECGUsedTxSignal" SG_ 2610129112 OTAPhysGWM_ECGtoRTM 1;
BA_ "U_T6_MCA_MY2020_Tx" SG_ 2610129112 OTAPhysGWM_ECGtoRTM 1;
BA_ "U_U55X_MY2022_Rx" SG_ 2610129112 OTAPhysGWM_ECGtoRTM 1;
BA_ "U_T6_MCA_MY2020_Rx" SG_ 2610129112 OTAPhysGWM_ECGtoRTM 1;
BA_ "GenSigSendType" SG_ 2610129112 OTAPhysGWM_ECGtoRTM 3;
BA_ "U_U55X_MY2022_Tx" SG_ 2610127066 OTAPhysRTMtoGWM_ECG 1;
BA_ "U_T6_MCA_MY2020_Tx" SG_ 2610127066 OTAPhysRTMtoGWM_ECG 1;
BA_ "U_U55X_MY2022_Rx" SG_ 2610127066 OTAPhysRTMtoGWM_ECG 1;
BA_ "U_CD542_MY2021_Rx" SG_ 2610127066 OTAPhysRTMtoGWM_ECG 1;
BA_ "ECGUsedRxSignal" SG_ 2610127066 OTAPhysRTMtoGWM_ECG 1;
BA_ "U_T6_MCA_MY2020_Rx" SG_ 2610127066 OTAPhysRTMtoGWM_ECG 1;
BA_ "GenSigSendType" SG_ 2610127066 OTAPhysRTMtoGWM_ECG 3;
BA_ "U_CD764_MY2022_Tx" SG_ 2610071768 OTAPhysGWM_ECGtoDSM 1;
BA_ "U_U55X_MY2022_Tx" SG_ 2610071768 OTAPhysGWM_ECGtoDSM 1;
BA_ "U_CD542_MY2021_Tx" SG_ 2610071768 OTAPhysGWM_ECGtoDSM 1;
BA_ "ECGUsedTxSignal" SG_ 2610071768 OTAPhysGWM_ECGtoDSM 1;
BA_ "U_T6_MCA_MY2020_Rx" SG_ 2610071768 OTAPhysGWM_ECGtoDSM 1;
BA_ "GenSigSendType" SG_ 2610071768 OTAPhysGWM_ECGtoDSM 3;
BA_ "U_T6_MCA_MY2020_Tx" SG_ 2610127010 OTAPhysDSMtoGWM_ECG 1;
BA_ "U_CD764_MY2022_Rx" SG_ 2610127010 OTAPhysDSMtoGWM_ECG 1;
BA_ "U_U55X_MY2022_Rx" SG_ 2610127010 OTAPhysDSMtoGWM_ECG 1;
BA_ "U_CD542_MY2021_Rx" SG_ 2610127010 OTAPhysDSMtoGWM_ECG 1;
BA_ "ECGUsedRxSignal" SG_ 2610127010 OTAPhysDSMtoGWM_ECG 1;
BA_ "GenSigSendType" SG_ 2610127010 OTAPhysDSMtoGWM_ECG 3;
BA_ "U_CD764_MY2022_Tx" SG_ 2611110104 PARSEDPhysGWMECGtoHVACRCCM 1;
BA_ "U_U55X_MY2022_Tx" SG_ 2611110104 PARSEDPhysGWMECGtoHVACRCCM 1;
BA_ "U_CD542_MY2021_Tx" SG_ 2611110104 PARSEDPhysGWMECGtoHVACRCCM 1;
BA_ "ECGUsedTxSignal" SG_ 2611110104 PARSEDPhysGWMECGtoHVACRCCM 1;
BA_ "U_T6_MCA_MY2020_Tx" SG_ 2611110104 PARSEDPhysGWMECGtoHVACRCCM 1;
BA_ "U_CD764_MY2022_Rx" SG_ 2611110104 PARSEDPhysGWMECGtoHVACRCCM 1;
BA_ "U_U55X_MY2022_Rx" SG_ 2611110104 PARSEDPhysGWMECGtoHVACRCCM 1;
BA_ "U_CD542_MY2021_Rx" SG_ 2611110104 PARSEDPhysGWMECGtoHVACRCCM 1;
BA_ "U_T6_MCA_MY2020_Rx" SG_ 2611110104 PARSEDPhysGWMECGtoHVACRCCM 1;
BA_ "GenSigSendType" SG_ 2611110104 PARSEDPhysGWMECGtoHVACRCCM 3;
BA_ "U_CD764_MY2022_Tx" SG_ 2612224152 PARSEPushHVACRCCMtoGWM 1;
BA_ "U_U55X_MY2022_Tx" SG_ 2612224152 PARSEPushHVACRCCMtoGWM 1;
BA_ "U_CD542_MY2021_Tx" SG_ 2612224152 PARSEPushHVACRCCMtoGWM 1;
BA_ "U_T6_MCA_MY2020_Tx" SG_ 2612224152 PARSEPushHVACRCCMtoGWM 1;
BA_ "U_CD764_MY2022_Rx" SG_ 2612224152 PARSEPushHVACRCCMtoGWM 1;
BA_ "U_U55X_MY2022_Rx" SG_ 2612224152 PARSEPushHVACRCCMtoGWM 1;
BA_ "U_CD542_MY2021_Rx" SG_ 2612224152 PARSEPushHVACRCCMtoGWM 1;
BA_ "ECGUsedRxSignal" SG_ 2612224152 PARSEPushHVACRCCMtoGWM 1;
BA_ "U_T6_MCA_MY2020_Rx" SG_ 2612224152 PARSEPushHVACRCCMtoGWM 1;
BA_ "GenSigSendType" SG_ 2612224152 PARSEPushHVACRCCMtoGWM 3;
BA_ "U_CD764_MY2022_Tx" SG_ 2611175576 PARSEDPhysHVACRCCMtoGWMECG 1;
BA_ "U_U55X_MY2022_Tx" SG_ 2611175576 PARSEDPhysHVACRCCMtoGWMECG 1;
BA_ "U_CD542_MY2021_Tx" SG_ 2611175576 PARSEDPhysHVACRCCMtoGWMECG 1;
BA_ "U_T6_MCA_MY2020_Tx" SG_ 2611175576 PARSEDPhysHVACRCCMtoGWMECG 1;
BA_ "U_CD764_MY2022_Rx" SG_ 2611175576 PARSEDPhysHVACRCCMtoGWMECG 1;
BA_ "U_U55X_MY2022_Rx" SG_ 2611175576 PARSEDPhysHVACRCCMtoGWMECG 1;
BA_ "U_CD542_MY2021_Rx" SG_ 2611175576 PARSEDPhysHVACRCCMtoGWMECG 1;
BA_ "ECGUsedRxSignal" SG_ 2611175576 PARSEDPhysHVACRCCMtoGWMECG 1;
BA_ "U_T6_MCA_MY2020_Rx" SG_ 2611175576 PARSEDPhysHVACRCCMtoGWMECG 1;
BA_ "GenSigSendType" SG_ 2611175576 PARSEDPhysHVACRCCMtoGWMECG 3;
BA_ "U_CD764_MY2022_Tx" SG_ 2610061528 OTAPhysGWM_ECGtoHVAC_RCCM 1;
BA_ "U_U55X_MY2022_Tx" SG_ 2610061528 OTAPhysGWM_ECGtoHVAC_RCCM 1;
BA_ "U_CD542_MY2021_Tx" SG_ 2610061528 OTAPhysGWM_ECGtoHVAC_RCCM 1;
BA_ "ECGUsedTxSignal" SG_ 2610061528 OTAPhysGWM_ECGtoHVAC_RCCM 1;
BA_ "U_T6_MCA_MY2020_Tx" SG_ 2610061528 OTAPhysGWM_ECGtoHVAC_RCCM 1;
BA_ "U_CD764_MY2022_Rx" SG_ 2610061528 OTAPhysGWM_ECGtoHVAC_RCCM 1;
BA_ "U_U55X_MY2022_Rx" SG_ 2610061528 OTAPhysGWM_ECGtoHVAC_RCCM 1;
BA_ "U_CD542_MY2021_Rx" SG_ 2610061528 OTAPhysGWM_ECGtoHVAC_RCCM 1;
BA_ "U_T6_MCA_MY2020_Rx" SG_ 2610061528 OTAPhysGWM_ECGtoHVAC_RCCM 1;
BA_ "GenSigSendType" SG_ 2610061528 OTAPhysGWM_ECGtoHVAC_RCCM 3;
BA_ "U_CD764_MY2022_Tx" SG_ 2610127000 OTAPhysHVAC_RCCMtoGWM_ECG 1;
BA_ "U_U55X_MY2022_Tx" SG_ 2610127000 OTAPhysHVAC_RCCMtoGWM_ECG 1;
BA_ "U_CD542_MY2021_Tx" SG_ 2610127000 OTAPhysHVAC_RCCMtoGWM_ECG 1;
BA_ "U_T6_MCA_MY2020_Tx" SG_ 2610127000 OTAPhysHVAC_RCCMtoGWM_ECG 1;
BA_ "U_CD764_MY2022_Rx" SG_ 2610127000 OTAPhysHVAC_RCCMtoGWM_ECG 1;
BA_ "U_U55X_MY2022_Rx" SG_ 2610127000 OTAPhysHVAC_RCCMtoGWM_ECG 1;
BA_ "U_CD542_MY2021_Rx" SG_ 2610127000 OTAPhysHVAC_RCCMtoGWM_ECG 1;
BA_ "ECGUsedRxSignal" SG_ 2610127000 OTAPhysHVAC_RCCMtoGWM_ECG 1;
BA_ "U_T6_MCA_MY2020_Rx" SG_ 2610127000 OTAPhysHVAC_RCCMtoGWM_ECG 1;
BA_ "GenSigSendType" SG_ 2610127000 OTAPhysHVAC_RCCMtoGWM_ECG 3;
BA_ "GenSigSendType" SG_ 959 TrnPrkSys_D_Actl 3;
BA_ "ContentDependant" SG_ 959 TrnPrkSys_D_Actl 1;
BA_ "ECGUsedRxSignal" SG_ 2610126913 OTAPhysSCMJtoGWM_ECG 1;
BA_ "GenSigSendType" SG_ 2610126913 OTAPhysSCMJtoGWM_ECG 3;
BA_ "U_CD764_MY2022_Tx" SG_ 2612002008 PARSEDFuncGWM_ECG 1;
BA_ "U_U55X_MY2022_Tx" SG_ 2612002008 PARSEDFuncGWM_ECG 1;
BA_ "U_CD542_MY2021_Tx" SG_ 2612002008 PARSEDFuncGWM_ECG 1;
BA_ "ECGUsedTxSignal" SG_ 2612002008 PARSEDFuncGWM_ECG 1;
BA_ "U_T6_MCA_MY2020_Tx" SG_ 2612002008 PARSEDFuncGWM_ECG 1;
BA_ "U_CD764_MY2022_Rx" SG_ 2612002008 PARSEDFuncGWM_ECG 1;
BA_ "U_U55X_MY2022_Rx" SG_ 2612002008 PARSEDFuncGWM_ECG 1;
BA_ "U_CD542_MY2021_Rx" SG_ 2612002008 PARSEDFuncGWM_ECG 1;
BA_ "U_T6_MCA_MY2020_Rx" SG_ 2612002008 PARSEDFuncGWM_ECG 1;
BA_ "GenSigSendType" SG_ 2612002008 PARSEDFuncGWM_ECG 3;
BA_ "U_CD764_MY2022_Tx" SG_ 2610953432 OTAFuncGWM_ECG 1;
BA_ "U_U55X_MY2022_Tx" SG_ 2610953432 OTAFuncGWM_ECG 1;
BA_ "U_CD542_MY2021_Tx" SG_ 2610953432 OTAFuncGWM_ECG 1;
BA_ "ECGUsedTxSignal" SG_ 2610953432 OTAFuncGWM_ECG 1;
BA_ "U_T6_MCA_MY2020_Tx" SG_ 2610953432 OTAFuncGWM_ECG 1;
BA_ "U_CD764_MY2022_Rx" SG_ 2610953432 OTAFuncGWM_ECG 1;
BA_ "U_U55X_MY2022_Rx" SG_ 2610953432 OTAFuncGWM_ECG 1;
BA_ "U_CD542_MY2021_Rx" SG_ 2610953432 OTAFuncGWM_ECG 1;
BA_ "U_T6_MCA_MY2020_Rx" SG_ 2610953432 OTAFuncGWM_ECG 1;
BA_ "GenSigSendType" SG_ 2610953432 OTAFuncGWM_ECG 3;
BA_ "ECGUsedRxSignal" SG_ 2611175489 PARSEDPhysSCMJtoGWM_ECG 1;
BA_ "GenSigSendType" SG_ 2611175489 PARSEDPhysSCMJtoGWM_ECG 3;
BA_ "GenSigStartValueInteger" SG_ 1255 BalrRight4Prev3Y_L_Actl 64;
BA_ "GenSigStartValueInteger" SG_ 1255 BalrRight4Prev3X_L_Actl 64;
BA_ "GenSigStartValueInteger" SG_ 1255 BalrRight4Prev2Y_L_Actl 64;
BA_ "GenSigStartValueInteger" SG_ 1255 BalrRight4Prev2X_L_Actl 64;
BA_ "GenSigStartValueInteger" SG_ 1255 BalrRight4Prev1Y_L_Actl 64;
BA_ "GenSigStartValueInteger" SG_ 1255 BalrRight4Prev1X_L_Actl 64;
BA_ "GenSigStartValueInteger" SG_ 1255 BalrRight4CurntY_L_Actl 64;
BA_ "GenSigStartValueInteger" SG_ 1255 BalrRight4CurntX_L_Actl 64;
BA_ "GenSigStartValueInteger" SG_ 1254 BalrRight3Prev3Y_L_Actl 64;
BA_ "GenSigStartValueInteger" SG_ 1254 BalrRight3Prev3X_L_Actl 64;
BA_ "GenSigStartValueInteger" SG_ 1254 BalrRight3Prev2Y_L_Actl 64;
BA_ "GenSigStartValueInteger" SG_ 1254 BalrRight3Prev2X_L_Actl 64;
BA_ "GenSigStartValueInteger" SG_ 1254 BalrRight3Prev1Y_L_Actl 64;
BA_ "GenSigStartValueInteger" SG_ 1254 BalrRight3Prev1X_L_Actl 64;
BA_ "GenSigStartValueInteger" SG_ 1254 BalrRight3CurntY_L_Actl 64;
BA_ "GenSigStartValueInteger" SG_ 1254 BalrRight3CurntX_L_Actl 64;
BA_ "GenSigStartValueInteger" SG_ 1253 BalrRight2Prev3Y_L_Actl 64;
BA_ "GenSigStartValueInteger" SG_ 1253 BalrRight2Prev3X_L_Actl 64;
BA_ "GenSigStartValueInteger" SG_ 1253 BalrRight2Prev2Y_L_Actl 64;
BA_ "GenSigStartValueInteger" SG_ 1253 BalrRight2Prev2X_L_Actl 64;
BA_ "GenSigStartValueInteger" SG_ 1253 BalrRight2Prev1Y_L_Actl 64;
BA_ "GenSigStartValueInteger" SG_ 1253 BalrRight2Prev1X_L_Actl 64;
BA_ "GenSigStartValueInteger" SG_ 1253 BalrRight2CurntY_L_Actl 64;
BA_ "GenSigStartValueInteger" SG_ 1253 BalrRight2CurntX_L_Actl 64;
BA_ "GenSigStartValueInteger" SG_ 1252 BalrRight1Prev3Y_L_Actl 64;
BA_ "GenSigStartValueInteger" SG_ 1252 BalrRight1Prev3X_L_Actl 64;
BA_ "GenSigStartValueInteger" SG_ 1252 BalrRight1Prev2Y_L_Actl 64;
BA_ "GenSigStartValueInteger" SG_ 1252 BalrRight1Prev2X_L_Actl 64;
BA_ "GenSigStartValueInteger" SG_ 1252 BalrRight1Prev1Y_L_Actl 64;
BA_ "GenSigStartValueInteger" SG_ 1252 BalrRight1Prev1X_L_Actl 64;
BA_ "GenSigStartValueInteger" SG_ 1252 BalrRight1CurntY_L_Actl 64;
BA_ "GenSigStartValueInteger" SG_ 1252 BalrRight1CurntX_L_Actl 64;
BA_ "GenSigStartValueInteger" SG_ 1251 BalrLeft4Prev3Y_L_Actl 64;
BA_ "GenSigStartValueInteger" SG_ 1251 BalrLeft4Prev3X_L_Actl 64;
BA_ "GenSigStartValueInteger" SG_ 1251 BalrLeft4Prev2Y_L_Actl 64;
BA_ "GenSigStartValueInteger" SG_ 1251 BalrLeft4Prev2X_L_Actl 64;
BA_ "GenSigStartValueInteger" SG_ 1251 BalrLeft4Prev1Y_L_Actl 64;
BA_ "GenSigStartValueInteger" SG_ 1251 BalrLeft4Prev1X_L_Actl 64;
BA_ "GenSigStartValueInteger" SG_ 1251 BalrLeft4CurntY_L_Actl 64;
BA_ "GenSigStartValueInteger" SG_ 1251 BalrLeft4CurntX_L_Actl 64;
BA_ "GenSigStartValueInteger" SG_ 1250 BalrLeft3Prev3Y_L_Actl 64;
BA_ "GenSigStartValueInteger" SG_ 1250 BalrLeft3Prev3X_L_Actl 64;
BA_ "GenSigStartValueInteger" SG_ 1250 BalrLeft3Prev2Y_L_Actl 64;
BA_ "GenSigStartValueInteger" SG_ 1250 BalrLeft3Prev2X_L_Actl 64;
BA_ "GenSigStartValueInteger" SG_ 1250 BalrLeft3Prev1Y_L_Actl 64;
BA_ "GenSigStartValueInteger" SG_ 1250 BalrLeft3Prev1X_L_Actl 64;
BA_ "GenSigStartValueInteger" SG_ 1250 BalrLeft3CurntY_L_Actl 64;
BA_ "GenSigStartValueInteger" SG_ 1250 BalrLeft3CurntX_L_Actl 64;
BA_ "GenSigStartValueInteger" SG_ 1249 BalrLeft2Prev3Y_L_Actl 64;
BA_ "GenSigStartValueInteger" SG_ 1249 BalrLeft2Prev3X_L_Actl 64;
BA_ "GenSigStartValueInteger" SG_ 1249 BalrLeft2Prev2Y_L_Actl 64;
BA_ "GenSigStartValueInteger" SG_ 1249 BalrLeft2Prev2X_L_Actl 64;
BA_ "GenSigStartValueInteger" SG_ 1249 BalrLeft2Prev1Y_L_Actl 64;
BA_ "GenSigStartValueInteger" SG_ 1249 BalrLeft2Prev1X_L_Actl 64;
BA_ "GenSigStartValueInteger" SG_ 1249 BalrLeft2CurntY_L_Actl 64;
BA_ "GenSigStartValueInteger" SG_ 1249 BalrLeft2CurntX_L_Actl 64;
BA_ "GenSigStartValueInteger" SG_ 1248 BalrLeft1CurntX_L_Actl 64;
BA_ "GenSigStartValueInteger" SG_ 1248 BalrLeft1Prev3Y_L_Actl 64;
BA_ "GenSigStartValueInteger" SG_ 1248 BalrLeft1Prev3X_L_Actl 64;
BA_ "GenSigStartValueInteger" SG_ 1248 BalrLeft1Prev2Y_L_Actl 64;
BA_ "GenSigStartValueInteger" SG_ 1248 BalrLeft1Prev2X_L_Actl 64;
BA_ "GenSigStartValueInteger" SG_ 1248 BalrLeft1Prev1Y_L_Actl 64;
BA_ "GenSigStartValueInteger" SG_ 1248 BalrLeft1Prev1X_L_Actl 64;
BA_ "GenSigStartValueInteger" SG_ 1248 BalrLeft1CurntY_L_Actl 64;
BA_ "U_T6_MCA_MY2020_Tx" SG_ 1998 TesterPhysicalResSODR 1;
BA_ "GenSigSendType" SG_ 1998 TesterPhysicalResSODR 3;
BA_ "U_T6_MCA_MY2020_Tx" SG_ 1996 TesterPhysicalResSODL 1;
BA_ "GenSigSendType" SG_ 1996 TesterPhysicalResSODL 3;
BA_ "U_T6_MCA_MY2020_Rx" SG_ 1990 TesterPhysicalReqSODR 1;
BA_ "GenSigSendType" SG_ 1990 TesterPhysicalReqSODR 3;
BA_ "U_T6_MCA_MY2020_Rx" SG_ 1988 TesterPhysicalReqSODL 1;
BA_ "GenSigSendType" SG_ 1988 TesterPhysicalReqSODL 3;
BA_ "GenSigSendType" SG_ 798 EmPrflNo_D_Rq 3;
BA_ "GenSigSendType" SG_ 798 EmPrflKeyAssoc_D_Rq 3;
BA_ "GenSigSendType" SG_ 798 ExitNotClrRight_B_Stat 3;
BA_ "GenSigSendType" SG_ 798 ExitNotClrLeft_B_Stat 3;
BA_ "U_CD764_MY2022_Rx" SG_ 798 ClimtCool_D_RqPt_UB 1;
BA_ "U_U55X_MY2022_Rx" SG_ 798 ClimtCool_D_RqPt_UB 1;
BA_ "U_CD764_MY2022_Rx" SG_ 798 ClimtCool_D_RqPt 1;
BA_ "U_U55X_MY2022_Rx" SG_ 798 ClimtCool_D_RqPt 1;
BA_ "GenSigSendType" SG_ 798 ClimtCool_D_RqPt 3;
BA_ "U_CD764_MY2022_Rx" SG_ 798 PudSptLghtRight_D_Rq_UB 1;
BA_ "U_U55X_MY2022_Rx" SG_ 798 PudSptLghtRight_D_Rq_UB 1;
BA_ "U_T6_MCA_MY2020_Rx" SG_ 798 PudSptLghtRight_D_Rq_UB 1;
BA_ "U_CD764_MY2022_Rx" SG_ 798 PudSptLghtLeft_D_Rq_UB 1;
BA_ "U_U55X_MY2022_Rx" SG_ 798 PudSptLghtLeft_D_Rq_UB 1;
BA_ "U_T6_MCA_MY2020_Rx" SG_ 798 PudSptLghtLeft_D_Rq_UB 1;
BA_ "U_CD764_MY2022_Rx" SG_ 798 PudSptLghtRight_D_Rq 1;
BA_ "U_U55X_MY2022_Rx" SG_ 798 PudSptLghtRight_D_Rq 1;
BA_ "U_T6_MCA_MY2020_Rx" SG_ 798 PudSptLghtRight_D_Rq 1;
BA_ "GenSigSendType" SG_ 798 PudSptLghtRight_D_Rq 3;
BA_ "WakeupSignal" SG_ 798 PudSptLghtRight_D_Rq 1;
BA_ "U_CD764_MY2022_Rx" SG_ 798 PwRnngBoardPoll_D_Stat_UB 1;
BA_ "U_U55X_MY2022_Rx" SG_ 798 PwRnngBoardPoll_D_Stat_UB 1;
BA_ "U_CD764_MY2022_Rx" SG_ 798 PwRnngBoardPoll_D_Stat 1;
BA_ "U_U55X_MY2022_Rx" SG_ 798 PwRnngBoardPoll_D_Stat 1;
BA_ "GenSigSendType" SG_ 798 PwRnngBoardPoll_D_Stat 3;
BA_ "WakeupSignal" SG_ 798 PwRnngBoardPoll_D_Stat 1;
BA_ "U_CD764_MY2022_Rx" SG_ 798 AirCondRec_B_RqVehEl_UB 1;
BA_ "U_U55X_MY2022_Rx" SG_ 798 AirCondRec_B_RqVehEl_UB 1;
BA_ "U_CD542_MY2021_Rx" SG_ 798 AirCondRec_B_RqVehEl_UB 1;
BA_ "U_T6_MCA_MY2020_Rx" SG_ 798 AirCondRec_B_RqVehEl_UB 1;
BA_ "U_CD764_MY2022_Rx" SG_ 798 AirCondRec_B_RqVehEl 1;
BA_ "U_U55X_MY2022_Rx" SG_ 798 AirCondRec_B_RqVehEl 1;
BA_ "U_CD542_MY2021_Rx" SG_ 798 AirCondRec_B_RqVehEl 1;
BA_ "U_T6_MCA_MY2020_Rx" SG_ 798 AirCondRec_B_RqVehEl 1;
BA_ "GenSigSendType" SG_ 798 AirCondRec_B_RqVehEl 3;
BA_ "U_U55X_MY2022_Rx" SG_ 798 RmtCtl_D_Stat 1;
BA_ "GenSigSendType" SG_ 798 RmtCtl_D_Stat 3;
BA_ "WakeupSignal" SG_ 798 RmtCtl_D_Stat 1;
BA_ "U_U55X_MY2022_Rx" SG_ 798 RmtCtl_D_Stat_UB 1;
BA_ "U_CD764_MY2022_Rx" SG_ 798 PudSptLghtLeft_D_Rq 1;
BA_ "U_U55X_MY2022_Rx" SG_ 798 PudSptLghtLeft_D_Rq 1;
BA_ "U_T6_MCA_MY2020_Rx" SG_ 798 PudSptLghtLeft_D_Rq 1;
BA_ "GenSigSendType" SG_ 798 PudSptLghtLeft_D_Rq 3;
BA_ "WakeupSignal" SG_ 798 PudSptLghtLeft_D_Rq 1;
BA_ "U_CD764_MY2022_Rx" SG_ 798 PoliceDmngLvl_D_Stat 1;
BA_ "U_U55X_MY2022_Rx" SG_ 798 PoliceDmngLvl_D_Stat 1;
BA_ "U_CD542_MY2021_Rx" SG_ 798 PoliceDmngLvl_D_Stat 1;
BA_ "U_T6_MCA_MY2020_Rx" SG_ 798 PoliceDmngLvl_D_Stat 1;
BA_ "GenSigSendType" SG_ 798 PoliceDmngLvl_D_Stat 3;
BA_ "U_CD764_MY2022_Rx" SG_ 798 VehWlcmFrwlMde_D_Stat_UB 1;
BA_ "U_U55X_MY2022_Rx" SG_ 798 VehWlcmFrwlMde_D_Stat_UB 1;
BA_ "U_T6_MCA_MY2020_Rx" SG_ 798 VehWlcmFrwlMde_D_Stat_UB 1;
BA_ "U_CD764_MY2022_Rx" SG_ 798 VehWlcmFrwl_D_Stat_UB 1;
BA_ "U_U55X_MY2022_Rx" SG_ 798 VehWlcmFrwl_D_Stat_UB 1;
BA_ "U_T6_MCA_MY2020_Rx" SG_ 798 VehWlcmFrwl_D_Stat_UB 1;
BA_ "U_CD764_MY2022_Rx" SG_ 798 VehWlcmFrwlMde_D_Stat 1;
BA_ "U_U55X_MY2022_Rx" SG_ 798 VehWlcmFrwlMde_D_Stat 1;
BA_ "U_T6_MCA_MY2020_Rx" SG_ 798 VehWlcmFrwlMde_D_Stat 1;
BA_ "GenSigSendType" SG_ 798 VehWlcmFrwlMde_D_Stat 3;
BA_ "WakeupSignal" SG_ 798 VehWlcmFrwlMde_D_Stat 1;
BA_ "U_CD764_MY2022_Rx" SG_ 798 VehWlcmFrwl_D_Stat 1;
BA_ "U_U55X_MY2022_Rx" SG_ 798 VehWlcmFrwl_D_Stat 1;
BA_ "U_T6_MCA_MY2020_Rx" SG_ 798 VehWlcmFrwl_D_Stat 1;
BA_ "GenSigSendType" SG_ 798 VehWlcmFrwl_D_Stat 3;
BA_ "WakeupSignal" SG_ 798 VehWlcmFrwl_D_Stat 1;
BA_ "U_CD764_MY2022_Rx" SG_ 798 PoliceDmngLvl_D_Stat_UB 1;
BA_ "U_U55X_MY2022_Rx" SG_ 798 PoliceDmngLvl_D_Stat_UB 1;
BA_ "U_CD542_MY2021_Rx" SG_ 798 PoliceDmngLvl_D_Stat_UB 1;
BA_ "U_T6_MCA_MY2020_Rx" SG_ 798 PoliceDmngLvl_D_Stat_UB 1;
BA_ "MetaData" SG_ 302 CanMsg12E_No_Crc 1;
BA_ "ContentDependant" SG_ 302 CanMsg12E_No_Crc 1;
BA_ "MetaData" SG_ 302 CanMsg12E_No_Cnt 1;
BA_ "ContentDependant" SG_ 302 CanMsg12E_No_Cnt 1;
BA_ "WakeupSignal" SG_ 302 TrnkFrontRleas_B_Stat 1;
BA_ "GenSigStartValue" SG_ 374 TrnRng_D_Rq 14;
BA_ "ContentDependant" SG_ 374 TrnRng_D_Rq 1;
BA_ "GenSigStartValueInteger" SG_ 374 TrnRng_D_Rq 14;
BA_ "ContentDependant" SG_ 374 TrnPrkSys_D_Actl 1;
BA_ "ContentDependant" SG_ 374 GearLvr_D_ActlDrv 1;
BA_ "MetaData" SG_ 374 GearPos_No_Cs 1;
BA_ "ContentDependant" SG_ 374 GearPos_No_Cs 1;
BA_ "GenSigStartValue" SG_ 374 GearPos_D_Trg 15;
BA_ "ContentDependant" SG_ 374 GearPos_D_Trg 1;
BA_ "GenSigStartValueInteger" SG_ 374 GearPos_D_Trg 15;
BA_ "MetaData" SG_ 374 GearPos_No_Cnt 1;
BA_ "ContentDependant" SG_ 374 GearPos_No_Cnt 1;
BA_ "GenSigStartValue" SG_ 374 GearPos_D_Actl 15;
BA_ "ContentDependant" SG_ 374 GearPos_D_Actl 1;
BA_ "GenSigStartValueInteger" SG_ 374 GearPos_D_Actl 15;
BA_ "U_CD764_MY2022_Rx" SG_ 300 TrukBedLght_B_Stat2 1;
BA_ "ECGUsedRxSignal" SG_ 300 TrukBedLght_B_Stat2 1;
BA_ "GenSigSendType" SG_ 300 TrukBedLght_B_Stat2 3;
BA_ "WakeupSignal" SG_ 300 TrukBedLght_B_Stat2 1;
BA_ "U_CD764_MY2022_Tx" SG_ 670 DrHandleOuterRl_D_Stat 1;
BA_ "GenSigSendType" SG_ 670 DrHandleOuterRl_D_Stat 3;
BA_ "U_CD764_MY2022_Tx" SG_ 670 DrHandleOuterFl_D_Stat 1;
BA_ "GenSigSendType" SG_ 670 DrHandleOuterFl_D_Stat 3;
BA_ "U_CD764_MY2022_Tx" SG_ 669 DrHandleOuterRr_D_Stat 1;
BA_ "GenSigSendType" SG_ 669 DrHandleOuterRr_D_Stat 3;
BA_ "U_CD764_MY2022_Tx" SG_ 669 DrHandleOuterFr_D_Stat 1;
BA_ "GenSigSendType" SG_ 669 DrHandleOuterFr_D_Stat 3;
BA_ "ECGUsedRxSignal" SG_ 2612224065 PARSEDPushSCMJtoGWM_ECG 1;
BA_ "GenSigSendType" SG_ 2612224065 PARSEDPushSCMJtoGWM_ECG 3;
BA_ "ECGUsedTxSignal" SG_ 2612069592 PARSEDPushFcGWM_ECGtoSCMJ 1;
BA_ "U_CD764_MY2022_Tx" SG_ 1413 PDM_GWOnBoardTester 1;
BA_ "U_U55X_MY2022_Tx" SG_ 1413 PDM_GWOnBoardTester 1;
BA_ "U_CD542_MY2021_Tx" SG_ 1413 PDM_GWOnBoardTester 1;
BA_ "U_T6_MCA_MY2020_Tx" SG_ 1413 PDM_GWOnBoardTester 1;
BA_ "U_P702_MY2021_Tx" SG_ 1413 PDM_GWOnBoardTester 1;
BA_ "GenSigStartValue" SG_ 1413 PDM_GWOnBoardTester 255;
BA_ "ContentDependant" SG_ 1413 PDM_GWOnBoardTester 1;
BA_ "GenSigStartValueInteger" SG_ 1413 PDM_GWOnBoardTester 255;
BA_ "U_CD764_MY2022_Tx" SG_ 1413 PDM_GWNMProxy 1;
BA_ "U_U55X_MY2022_Tx" SG_ 1413 PDM_GWNMProxy 1;
BA_ "U_CD542_MY2021_Tx" SG_ 1413 PDM_GWNMProxy 1;
BA_ "U_T6_MCA_MY2020_Tx" SG_ 1413 PDM_GWNMProxy 1;
BA_ "U_P702_MY2021_Tx" SG_ 1413 PDM_GWNMProxy 1;
BA_ "GenSigStartValue" SG_ 1413 PDM_GWNMProxy 255;
BA_ "ContentDependant" SG_ 1413 PDM_GWNMProxy 1;
BA_ "GenSigStartValueInteger" SG_ 1413 PDM_GWNMProxy 255;
BA_ "U_CD764_MY2022_Tx" SG_ 1413 PDM_AutoSarNMReserved4 1;
BA_ "U_U55X_MY2022_Tx" SG_ 1413 PDM_AutoSarNMReserved4 1;
BA_ "U_CD542_MY2021_Tx" SG_ 1413 PDM_AutoSarNMReserved4 1;
BA_ "U_T6_MCA_MY2020_Tx" SG_ 1413 PDM_AutoSarNMReserved4 1;
BA_ "U_P702_MY2021_Tx" SG_ 1413 PDM_AutoSarNMReserved4 1;
BA_ "GenSigStartValue" SG_ 1413 PDM_AutoSarNMReserved4 255;
BA_ "ContentDependant" SG_ 1413 PDM_AutoSarNMReserved4 1;
BA_ "GenSigStartValueInteger" SG_ 1413 PDM_AutoSarNMReserved4 255;
BA_ "U_CD764_MY2022_Tx" SG_ 1413 PDM_AutoSarNMReserved3 1;
BA_ "U_U55X_MY2022_Tx" SG_ 1413 PDM_AutoSarNMReserved3 1;
BA_ "U_CD542_MY2021_Tx" SG_ 1413 PDM_AutoSarNMReserved3 1;
BA_ "U_T6_MCA_MY2020_Tx" SG_ 1413 PDM_AutoSarNMReserved3 1;
BA_ "U_P702_MY2021_Tx" SG_ 1413 PDM_AutoSarNMReserved3 1;
BA_ "GenSigStartValue" SG_ 1413 PDM_AutoSarNMReserved3 255;
BA_ "ContentDependant" SG_ 1413 PDM_AutoSarNMReserved3 1;
BA_ "GenSigStartValueInteger" SG_ 1413 PDM_AutoSarNMReserved3 255;
BA_ "U_CD764_MY2022_Tx" SG_ 1413 PDM_AutoSarNMReserved2 1;
BA_ "U_U55X_MY2022_Tx" SG_ 1413 PDM_AutoSarNMReserved2 1;
BA_ "U_CD542_MY2021_Tx" SG_ 1413 PDM_AutoSarNMReserved2 1;
BA_ "U_T6_MCA_MY2020_Tx" SG_ 1413 PDM_AutoSarNMReserved2 1;
BA_ "U_P702_MY2021_Tx" SG_ 1413 PDM_AutoSarNMReserved2 1;
BA_ "GenSigStartValue" SG_ 1413 PDM_AutoSarNMReserved2 255;
BA_ "ContentDependant" SG_ 1413 PDM_AutoSarNMReserved2 1;
BA_ "GenSigStartValueInteger" SG_ 1413 PDM_AutoSarNMReserved2 255;
BA_ "U_CD764_MY2022_Tx" SG_ 1413 PDM_AutoSarNMReserved1 1;
BA_ "U_U55X_MY2022_Tx" SG_ 1413 PDM_AutoSarNMReserved1 1;
BA_ "U_CD542_MY2021_Tx" SG_ 1413 PDM_AutoSarNMReserved1 1;
BA_ "U_T6_MCA_MY2020_Tx" SG_ 1413 PDM_AutoSarNMReserved1 1;
BA_ "U_P702_MY2021_Tx" SG_ 1413 PDM_AutoSarNMReserved1 1;
BA_ "GenSigStartValue" SG_ 1413 PDM_AutoSarNMReserved1 255;
BA_ "ContentDependant" SG_ 1413 PDM_AutoSarNMReserved1 1;
BA_ "GenSigStartValueInteger" SG_ 1413 PDM_AutoSarNMReserved1 255;
BA_ "U_CD764_MY2022_Tx" SG_ 1413 PDM_AutoSarNMNodeId 1;
BA_ "U_U55X_MY2022_Tx" SG_ 1413 PDM_AutoSarNMNodeId 1;
BA_ "U_CD542_MY2021_Tx" SG_ 1413 PDM_AutoSarNMNodeId 1;
BA_ "U_T6_MCA_MY2020_Tx" SG_ 1413 PDM_AutoSarNMNodeId 1;
BA_ "U_P702_MY2021_Tx" SG_ 1413 PDM_AutoSarNMNodeId 1;
BA_ "GenSigStartValue" SG_ 1413 PDM_AutoSarNMNodeId 133;
BA_ "ContentDependant" SG_ 1413 PDM_AutoSarNMNodeId 1;
BA_ "GenSigStartValueInteger" SG_ 1413 PDM_AutoSarNMNodeId 133;
BA_ "U_CD764_MY2022_Tx" SG_ 1413 PDM_AutoSarNMControl 1;
BA_ "U_U55X_MY2022_Tx" SG_ 1413 PDM_AutoSarNMControl 1;
BA_ "U_CD542_MY2021_Tx" SG_ 1413 PDM_AutoSarNMControl 1;
BA_ "U_T6_MCA_MY2020_Tx" SG_ 1413 PDM_AutoSarNMControl 1;
BA_ "U_P702_MY2021_Tx" SG_ 1413 PDM_AutoSarNMControl 1;
BA_ "ContentDependant" SG_ 1413 PDM_AutoSarNMControl 1;
BA_ "U_CD764_MY2022_Tx" SG_ 1412 DDM_GWOnBoardTester 1;
BA_ "U_U55X_MY2022_Tx" SG_ 1412 DDM_GWOnBoardTester 1;
BA_ "U_CD542_MY2021_Tx" SG_ 1412 DDM_GWOnBoardTester 1;
BA_ "U_T6_MCA_MY2020_Tx" SG_ 1412 DDM_GWOnBoardTester 1;
BA_ "U_P702_MY2021_Tx" SG_ 1412 DDM_GWOnBoardTester 1;
BA_ "U_CX727_MY2021_Tx" SG_ 1412 DDM_GWOnBoardTester 1;
BA_ "GenSigStartValue" SG_ 1412 DDM_GWOnBoardTester 255;
BA_ "ContentDependant" SG_ 1412 DDM_GWOnBoardTester 1;
BA_ "GenSigStartValueInteger" SG_ 1412 DDM_GWOnBoardTester 255;
BA_ "U_CD764_MY2022_Tx" SG_ 1412 DDM_GWNMProxy 1;
BA_ "U_U55X_MY2022_Tx" SG_ 1412 DDM_GWNMProxy 1;
BA_ "U_CD542_MY2021_Tx" SG_ 1412 DDM_GWNMProxy 1;
BA_ "U_T6_MCA_MY2020_Tx" SG_ 1412 DDM_GWNMProxy 1;
BA_ "U_P702_MY2021_Tx" SG_ 1412 DDM_GWNMProxy 1;
BA_ "U_CX727_MY2021_Tx" SG_ 1412 DDM_GWNMProxy 1;
BA_ "GenSigStartValue" SG_ 1412 DDM_GWNMProxy 255;
BA_ "ContentDependant" SG_ 1412 DDM_GWNMProxy 1;
BA_ "GenSigStartValueInteger" SG_ 1412 DDM_GWNMProxy 255;
BA_ "U_CD764_MY2022_Tx" SG_ 1412 DDM_AutoSarNMReserved4 1;
BA_ "U_U55X_MY2022_Tx" SG_ 1412 DDM_AutoSarNMReserved4 1;
BA_ "U_CD542_MY2021_Tx" SG_ 1412 DDM_AutoSarNMReserved4 1;
BA_ "U_T6_MCA_MY2020_Tx" SG_ 1412 DDM_AutoSarNMReserved4 1;
BA_ "U_P702_MY2021_Tx" SG_ 1412 DDM_AutoSarNMReserved4 1;
BA_ "U_CX727_MY2021_Tx" SG_ 1412 DDM_AutoSarNMReserved4 1;
BA_ "GenSigStartValue" SG_ 1412 DDM_AutoSarNMReserved4 255;
BA_ "ContentDependant" SG_ 1412 DDM_AutoSarNMReserved4 1;
BA_ "GenSigStartValueInteger" SG_ 1412 DDM_AutoSarNMReserved4 255;
BA_ "U_CD764_MY2022_Tx" SG_ 1412 DDM_AutoSarNMReserved3 1;
BA_ "U_U55X_MY2022_Tx" SG_ 1412 DDM_AutoSarNMReserved3 1;
BA_ "U_CD542_MY2021_Tx" SG_ 1412 DDM_AutoSarNMReserved3 1;
BA_ "U_T6_MCA_MY2020_Tx" SG_ 1412 DDM_AutoSarNMReserved3 1;
BA_ "U_P702_MY2021_Tx" SG_ 1412 DDM_AutoSarNMReserved3 1;
BA_ "U_CX727_MY2021_Tx" SG_ 1412 DDM_AutoSarNMReserved3 1;
BA_ "GenSigStartValue" SG_ 1412 DDM_AutoSarNMReserved3 255;
BA_ "ContentDependant" SG_ 1412 DDM_AutoSarNMReserved3 1;
BA_ "GenSigStartValueInteger" SG_ 1412 DDM_AutoSarNMReserved3 255;
BA_ "U_CD764_MY2022_Tx" SG_ 1412 DDM_AutoSarNMReserved2 1;
BA_ "U_U55X_MY2022_Tx" SG_ 1412 DDM_AutoSarNMReserved2 1;
BA_ "U_CD542_MY2021_Tx" SG_ 1412 DDM_AutoSarNMReserved2 1;
BA_ "U_T6_MCA_MY2020_Tx" SG_ 1412 DDM_AutoSarNMReserved2 1;
BA_ "U_P702_MY2021_Tx" SG_ 1412 DDM_AutoSarNMReserved2 1;
BA_ "U_CX727_MY2021_Tx" SG_ 1412 DDM_AutoSarNMReserved2 1;
BA_ "GenSigStartValue" SG_ 1412 DDM_AutoSarNMReserved2 255;
BA_ "ContentDependant" SG_ 1412 DDM_AutoSarNMReserved2 1;
BA_ "GenSigStartValueInteger" SG_ 1412 DDM_AutoSarNMReserved2 255;
BA_ "U_CD764_MY2022_Tx" SG_ 1412 DDM_AutoSarNMReserved1 1;
BA_ "U_U55X_MY2022_Tx" SG_ 1412 DDM_AutoSarNMReserved1 1;
BA_ "U_CD542_MY2021_Tx" SG_ 1412 DDM_AutoSarNMReserved1 1;
BA_ "U_T6_MCA_MY2020_Tx" SG_ 1412 DDM_AutoSarNMReserved1 1;
BA_ "U_P702_MY2021_Tx" SG_ 1412 DDM_AutoSarNMReserved1 1;
BA_ "U_CX727_MY2021_Tx" SG_ 1412 DDM_AutoSarNMReserved1 1;
BA_ "GenSigStartValue" SG_ 1412 DDM_AutoSarNMReserved1 255;
BA_ "ContentDependant" SG_ 1412 DDM_AutoSarNMReserved1 1;
BA_ "GenSigStartValueInteger" SG_ 1412 DDM_AutoSarNMReserved1 255;
BA_ "U_CD764_MY2022_Tx" SG_ 1412 DDM_AutoSarNMNodeId 1;
BA_ "U_U55X_MY2022_Tx" SG_ 1412 DDM_AutoSarNMNodeId 1;
BA_ "U_CD542_MY2021_Tx" SG_ 1412 DDM_AutoSarNMNodeId 1;
BA_ "U_T6_MCA_MY2020_Tx" SG_ 1412 DDM_AutoSarNMNodeId 1;
BA_ "U_P702_MY2021_Tx" SG_ 1412 DDM_AutoSarNMNodeId 1;
BA_ "U_CX727_MY2021_Tx" SG_ 1412 DDM_AutoSarNMNodeId 1;
BA_ "GenSigStartValue" SG_ 1412 DDM_AutoSarNMNodeId 132;
BA_ "ContentDependant" SG_ 1412 DDM_AutoSarNMNodeId 1;
BA_ "GenSigStartValueInteger" SG_ 1412 DDM_AutoSarNMNodeId 132;
BA_ "U_CD764_MY2022_Tx" SG_ 1412 DDM_AutoSarNMControl 1;
BA_ "U_U55X_MY2022_Tx" SG_ 1412 DDM_AutoSarNMControl 1;
BA_ "U_CD542_MY2021_Tx" SG_ 1412 DDM_AutoSarNMControl 1;
BA_ "U_T6_MCA_MY2020_Tx" SG_ 1412 DDM_AutoSarNMControl 1;
BA_ "U_P702_MY2021_Tx" SG_ 1412 DDM_AutoSarNMControl 1;
BA_ "U_CX727_MY2021_Tx" SG_ 1412 DDM_AutoSarNMControl 1;
BA_ "ContentDependant" SG_ 1412 DDM_AutoSarNMControl 1;
BA_ "GenSigSendType" SG_ 1079 ApaMde_D_Stat 3;
BA_ "U_T6_MCA_MY2020_Rx" SG_ 1079 TrlrAidEnbl_D2_Stat_UB 1;
BA_ "U_T6_MCA_MY2020_Rx" SG_ 1079 TrlrAidEnbl_D2_Stat 1;
BA_ "GenSigSendType" SG_ 1079 PoliceAux4Swtch_B_Stat 3;
BA_ "GenSigSendType" SG_ 1079 PoliceAux3Swtch_B_Stat 3;
BA_ "GenSigSendType" SG_ 1079 PoliceAux2Swtch_B_Stat 3;
BA_ "GenSigSendType" SG_ 1079 PoliceAux1Swtch_B_Stat 3;
BA_ "GenSigSendType" SG_ 1079 GenericSwtch3_No_Actl 3;
BA_ "GenSigSendType" SG_ 1079 GenericSwtch2_No_Actl 3;
BA_ "ContentDependant" SG_ 1079 GenericSwtch2_No_Actl 1;
BA_ "GenSigSendType" SG_ 1079 GenericSwtch1_No_Actl 3;
BA_ "GenSigSendType" SG_ 1079 RbaSys_D_Stat 3;
BA_ "GenSigStartValue" SG_ 1079 RbaSys_D_Stat 2;
BA_ "GenSigStartValueInteger" SG_ 1079 RbaSys_D_Stat 2;
BA_ "U_CD764_MY2022_Rx" SG_ 1079 HybMdeStat_D_Dsply_UB 1;
BA_ "U_U55X_MY2022_Rx" SG_ 1079 HybMdeStat_D_Dsply_UB 1;
BA_ "U_CD542_MY2021_Rx" SG_ 1079 HybMdeStat_D_Dsply_UB 1;
BA_ "U_P702_MY2021_Rx" SG_ 1079 HybMdeStat_D_Dsply_UB 1;
BA_ "U_CX727_MY2021_Rx" SG_ 1079 HybMdeStat_D_Dsply_UB 1;
BA_ "GenSigSendType" SG_ 1079 Rba_D_Stat 3;
BA_ "GenSigStartValue" SG_ 1079 Rba_D_Stat 1;
BA_ "GenSigStartValueInteger" SG_ 1079 Rba_D_Stat 1;
BA_ "GenSigSendType" SG_ 1079 BalrMde_D_Rq 3;
BA_ "U_CD764_MY2022_Rx" SG_ 1079 ChrgGoTTouchEnbl_B_Rq 1;
BA_ "U_U55X_MY2022_Rx" SG_ 1079 ChrgGoTTouchEnbl_B_Rq 1;
BA_ "U_CD542_MY2021_Rx" SG_ 1079 ChrgGoTTouchEnbl_B_Rq 1;
BA_ "U_CX727_MY2021_Rx" SG_ 1079 ChrgGoTTouchEnbl_B_Rq 1;
BA_ "GenSigSendType" SG_ 1079 ChrgGoTTouchEnbl_B_Rq 3;
BA_ "U_CD764_MY2022_Rx" SG_ 1079 ChrgGoTExtHtrEnbl_B_Rq 1;
BA_ "U_U55X_MY2022_Rx" SG_ 1079 ChrgGoTExtHtrEnbl_B_Rq 1;
BA_ "U_CD542_MY2021_Rx" SG_ 1079 ChrgGoTExtHtrEnbl_B_Rq 1;
BA_ "U_CX727_MY2021_Rx" SG_ 1079 ChrgGoTExtHtrEnbl_B_Rq 1;
BA_ "GenSigSendType" SG_ 1079 ChrgGoTExtHtrEnbl_B_Rq 3;
BA_ "U_CD764_MY2022_Rx" SG_ 1079 ChrgGoTTouchEnbl_B_Rq_UB 1;
BA_ "U_U55X_MY2022_Rx" SG_ 1079 ChrgGoTTouchEnbl_B_Rq_UB 1;
BA_ "U_CD542_MY2021_Rx" SG_ 1079 ChrgGoTTouchEnbl_B_Rq_UB 1;
BA_ "U_CX727_MY2021_Rx" SG_ 1079 ChrgGoTTouchEnbl_B_Rq_UB 1;
BA_ "U_CD764_MY2022_Rx" SG_ 1079 ChrgGoTExtHtrEnbl_B_Rq_UB 1;
BA_ "U_U55X_MY2022_Rx" SG_ 1079 ChrgGoTExtHtrEnbl_B_Rq_UB 1;
BA_ "U_CD542_MY2021_Rx" SG_ 1079 ChrgGoTExtHtrEnbl_B_Rq_UB 1;
BA_ "U_CX727_MY2021_Rx" SG_ 1079 ChrgGoTExtHtrEnbl_B_Rq_UB 1;
BA_ "GenSigSendType" SG_ 1079 LcwaAlrtRight_B_Rq 3;
BA_ "GenSigSendType" SG_ 1079 LcwaAlrtLeft_B_Rq 3;
BA_ "U_CX727_MY2021_Rx" SG_ 1079 ApaSteScanMde_D_Stat 1;
BA_ "GenSigSendType" SG_ 1079 ApaSteScanMde_D_Stat 3;
BA_ "U_CX727_MY2021_Rx" SG_ 1079 ApaSteScanMde_D_Stat_UB 1;
BA_ "U_CD764_MY2022_Rx" SG_ 1079 BattTracClimtDis_B_Stat_UB 1;
BA_ "U_U55X_MY2022_Rx" SG_ 1079 BattTracClimtDis_B_Stat_UB 1;
BA_ "U_CD542_MY2021_Rx" SG_ 1079 BattTracClimtDis_B_Stat_UB 1;
BA_ "U_T6_MCA_MY2020_Rx" SG_ 1079 BattTracClimtDis_B_Stat_UB 1;
BA_ "U_CD764_MY2022_Rx" SG_ 1079 BattTracClimtDis_B_Stat 1;
BA_ "U_U55X_MY2022_Rx" SG_ 1079 BattTracClimtDis_B_Stat 1;
BA_ "U_CD542_MY2021_Rx" SG_ 1079 BattTracClimtDis_B_Stat 1;
BA_ "U_T6_MCA_MY2020_Rx" SG_ 1079 BattTracClimtDis_B_Stat 1;
BA_ "GenSigSendType" SG_ 1079 BattTracClimtDis_B_Stat 3;
BA_ "GenSigSendType" SG_ 1079 BalrSwtch_D_Stat 3;
BA_ "GenSigStartValue" SG_ 1079 BalrSwtch_D_Stat 1;
BA_ "GenSigStartValueInteger" SG_ 1079 BalrSwtch_D_Stat 1;
BA_ "U_T6_MCA_MY2020_Rx" SG_ 1079 TrlrAidMsgTxt_D2_Rq_UB 1;
BA_ "U_P702_MY2021_Rx" SG_ 1079 TrlrAidMsgTxt_D2_Rq_UB 1;
BA_ "U_T6_MCA_MY2020_Rx" SG_ 1079 TrlrAidMsgTxt_D2_Rq 1;
BA_ "U_P702_MY2021_Rx" SG_ 1079 TrlrAidMsgTxt_D2_Rq 1;
BA_ "GenSigSendType" SG_ 1079 TrlrAidMsgTxt_D2_Rq 3;
BA_ "U_CD764_MY2022_Rx" SG_ 1079 HybMdeStat_D_Dsply 1;
BA_ "U_U55X_MY2022_Rx" SG_ 1079 HybMdeStat_D_Dsply 1;
BA_ "U_CD542_MY2021_Rx" SG_ 1079 HybMdeStat_D_Dsply 1;
BA_ "U_P702_MY2021_Rx" SG_ 1079 HybMdeStat_D_Dsply 1;
BA_ "U_CX727_MY2021_Rx" SG_ 1079 HybMdeStat_D_Dsply 1;
BA_ "GenSigSendType" SG_ 1079 HybMdeStat_D_Dsply 3;
BA_ "U_U55X_MY2022_Tx" SG_ 875 SeatIntnsDrvRr_D_Stat 1;
BA_ "GenSigSendType" SG_ 875 SeatIntnsDrvRr_D_Stat 3;
BA_ "U_U55X_MY2022_Tx" SG_ 875 SeatMasgDrvRr_D_Stat 1;
BA_ "GenSigSendType" SG_ 875 SeatMasgDrvRr_D_Stat 3;
BA_ "U_U55X_MY2022_Tx" SG_ 875 SeatSwtchRl_B_Stat 1;
BA_ "GenSigSendType" SG_ 875 SeatSwtchRl_B_Stat 3;
BA_ "U_U55X_MY2022_Tx" SG_ 875 SeatPRl_B_Stat 1;
BA_ "GenSigSendType" SG_ 875 SeatPRl_B_Stat 3;
BA_ "U_U55X_MY2022_Tx" SG_ 875 SeatLmbrUpRl_Pc_Actl 1;
BA_ "GenSigSendType" SG_ 875 SeatLmbrUpRl_Pc_Actl 3;
BA_ "GenSigStartValue" SG_ 875 SeatLmbrUpRl_Pc_Actl 127;
BA_ "GenSigStartValueInteger" SG_ 875 SeatLmbrUpRl_Pc_Actl 127;
BA_ "U_U55X_MY2022_Tx" SG_ 875 SeatLmbrMidRl_Pc_Actl 1;
BA_ "GenSigSendType" SG_ 875 SeatLmbrMidRl_Pc_Actl 3;
BA_ "GenSigStartValue" SG_ 875 SeatLmbrMidRl_Pc_Actl 127;
BA_ "GenSigStartValueInteger" SG_ 875 SeatLmbrMidRl_Pc_Actl 127;
BA_ "U_U55X_MY2022_Tx" SG_ 875 SeatLmbrLoRl_Pc_Actl 1;
BA_ "GenSigSendType" SG_ 875 SeatLmbrLoRl_Pc_Actl 3;
BA_ "GenSigStartValue" SG_ 875 SeatLmbrLoRl_Pc_Actl 127;
BA_ "GenSigStartValueInteger" SG_ 875 SeatLmbrLoRl_Pc_Actl 127;
BA_ "U_U55X_MY2022_Tx" SG_ 875 SeatFnRl_D_Stat 1;
BA_ "GenSigSendType" SG_ 875 SeatFnRl_D_Stat 3;
BA_ "U_U55X_MY2022_Tx" SG_ 875 StmsLmbrDrv_D_Stat2 1;
BA_ "GenSigSendType" SG_ 875 StmsLmbrDrv_D_Stat2 3;
BA_ "U_U55X_MY2022_Tx" SG_ 875 StmsCshnDrv_D_Stat2 1;
BA_ "GenSigSendType" SG_ 875 StmsCshnDrv_D_Stat2 3;
BA_ "U_U55X_MY2022_Tx" SG_ 875 SeatAirAmb_P_Actl2 1;
BA_ "U_U55X_MY2022_Rx" SG_ 875 SeatAirAmb_P_Actl2 1;
BA_ "GenSigSendType" SG_ 1797 TesterPhysicalReqSFMB 3;
BA_ "U_T6_MCA_MY2020_Tx" SG_ 941 CtaTrgtRightY_V_Actl 1;
BA_ "U_CX727_MY2021_Tx" SG_ 941 CtaTrgtRightY_V_Actl 1;
BA_ "U_T6_MCA_MY2020_Rx" SG_ 941 CtaTrgtRightY_V_Actl 1;
BA_ "U_CX727_MY2021_Rx" SG_ 941 CtaTrgtRightY_V_Actl 1;
BA_ "GenSigStartValueInteger" SG_ 941 CtaTrgtRightY_V_Actl 32767;
BA_ "U_T6_MCA_MY2020_Tx" SG_ 941 CtaTrgtRightY_L_Actl 1;
BA_ "U_CX727_MY2021_Tx" SG_ 941 CtaTrgtRightY_L_Actl 1;
BA_ "U_T6_MCA_MY2020_Rx" SG_ 941 CtaTrgtRightY_L_Actl 1;
BA_ "U_CX727_MY2021_Rx" SG_ 941 CtaTrgtRightY_L_Actl 1;
BA_ "GenSigStartValueInteger" SG_ 941 CtaTrgtRightY_L_Actl 32767;
BA_ "U_T6_MCA_MY2020_Tx" SG_ 941 CtaTrgtRightX_V_Actl 1;
BA_ "U_CX727_MY2021_Tx" SG_ 941 CtaTrgtRightX_V_Actl 1;
BA_ "U_T6_MCA_MY2020_Rx" SG_ 941 CtaTrgtRightX_V_Actl 1;
BA_ "U_CX727_MY2021_Rx" SG_ 941 CtaTrgtRightX_V_Actl 1;
BA_ "GenSigStartValueInteger" SG_ 941 CtaTrgtRightX_V_Actl 32767;
BA_ "U_T6_MCA_MY2020_Tx" SG_ 941 CtaTrgtRightX_L_Actl 1;
BA_ "U_CX727_MY2021_Tx" SG_ 941 CtaTrgtRightX_L_Actl 1;
BA_ "U_T6_MCA_MY2020_Rx" SG_ 941 CtaTrgtRightX_L_Actl 1;
BA_ "U_CX727_MY2021_Rx" SG_ 941 CtaTrgtRightX_L_Actl 1;
BA_ "GenSigStartValueInteger" SG_ 941 CtaTrgtRightX_L_Actl 56174;
BA_ "U_T6_MCA_MY2020_Tx" SG_ 940 CtaTrgtLeftY_V_Actl 1;
BA_ "U_CX727_MY2021_Tx" SG_ 940 CtaTrgtLeftY_V_Actl 1;
BA_ "U_T6_MCA_MY2020_Rx" SG_ 940 CtaTrgtLeftY_V_Actl 1;
BA_ "U_CX727_MY2021_Rx" SG_ 940 CtaTrgtLeftY_V_Actl 1;
BA_ "GenSigStartValueInteger" SG_ 940 CtaTrgtLeftY_V_Actl 32767;
BA_ "U_T6_MCA_MY2020_Tx" SG_ 940 CtaTrgtLeftY_L_Actl 1;
BA_ "U_CX727_MY2021_Tx" SG_ 940 CtaTrgtLeftY_L_Actl 1;
BA_ "U_T6_MCA_MY2020_Rx" SG_ 940 CtaTrgtLeftY_L_Actl 1;
BA_ "U_CX727_MY2021_Rx" SG_ 940 CtaTrgtLeftY_L_Actl 1;
BA_ "GenSigStartValueInteger" SG_ 940 CtaTrgtLeftY_L_Actl 32767;
BA_ "U_T6_MCA_MY2020_Tx" SG_ 940 CtaTrgtLeftX_V_Actl 1;
BA_ "U_CX727_MY2021_Tx" SG_ 940 CtaTrgtLeftX_V_Actl 1;
BA_ "U_T6_MCA_MY2020_Rx" SG_ 940 CtaTrgtLeftX_V_Actl 1;
BA_ "U_CX727_MY2021_Rx" SG_ 940 CtaTrgtLeftX_V_Actl 1;
BA_ "GenSigStartValueInteger" SG_ 940 CtaTrgtLeftX_V_Actl 32767;
BA_ "U_T6_MCA_MY2020_Tx" SG_ 940 CtaTrgtLeftX_L_Actl 1;
BA_ "U_CX727_MY2021_Tx" SG_ 940 CtaTrgtLeftX_L_Actl 1;
BA_ "U_T6_MCA_MY2020_Rx" SG_ 940 CtaTrgtLeftX_L_Actl 1;
BA_ "U_CX727_MY2021_Rx" SG_ 940 CtaTrgtLeftX_L_Actl 1;
BA_ "GenSigStartValueInteger" SG_ 940 CtaTrgtLeftX_L_Actl 56174;
BA_ "GenSigStartValue" SG_ 1095 HeadLghtOn_D_Rq 1;
BA_ "GenSigStartValueInteger" SG_ 1095 HeadLghtOn_D_Rq 1;
BA_ "WakeupSignal" SG_ 1095 HeadLghtOn_D_Rq 1;
BA_ "U_U55X_MY2022_Rx" SG_ 1095 RstrtSetting_T_Actl 1;
BA_ "U_T6_MCA_MY2020_Rx" SG_ 1095 RstrtSetting_T_Actl 1;
BA_ "U_P702_MY2021_Rx" SG_ 1095 RstrtSetting_T_Actl 1;
BA_ "U_CX727_MY2021_Rx" SG_ 1095 RstrtSetting_T_Actl 1;
BA_ "U_U55X_MY2022_Rx" SG_ 1095 Rstrt_T_Actl 1;
BA_ "U_T6_MCA_MY2020_Rx" SG_ 1095 Rstrt_T_Actl 1;
BA_ "U_P702_MY2021_Rx" SG_ 1095 Rstrt_T_Actl 1;
BA_ "U_CX727_MY2021_Rx" SG_ 1095 Rstrt_T_Actl 1;
BA_ "GenSigStartValue" SG_ 948 Tire_Press_Placrd_Rear 255;
BA_ "GenSigStartValueInteger" SG_ 948 Tire_Press_Placrd_Rear 255;
BA_ "GenSigStartValue" SG_ 948 Tire_Press_Placrd_Frnt 255;
BA_ "GenSigStartValueInteger" SG_ 948 Tire_Press_Placrd_Frnt 255;
BA_ "U_U55X_MY2022_Rx" SG_ 948 Tire_Press_ILR_Stat 1;
BA_ "U_T6_MCA_MY2020_Rx" SG_ 948 Tire_Press_ILR_Stat 1;
BA_ "U_P702_MY2021_Rx" SG_ 948 Tire_Press_ILR_Stat 1;
BA_ "U_CX727_MY2021_Rx" SG_ 948 Tire_Press_ILR_Stat 1;
BA_ "U_U55X_MY2022_Rx" SG_ 948 Tire_Press_IRR_Stat 1;
BA_ "U_T6_MCA_MY2020_Rx" SG_ 948 Tire_Press_IRR_Stat 1;
BA_ "U_P702_MY2021_Rx" SG_ 948 Tire_Press_IRR_Stat 1;
BA_ "U_CX727_MY2021_Rx" SG_ 948 Tire_Press_IRR_Stat 1;
BA_ "U_U55X_MY2022_Rx" SG_ 948 Tire_Press_LR_OLR_Stat 1;
BA_ "U_T6_MCA_MY2020_Rx" SG_ 948 Tire_Press_LR_OLR_Stat 1;
BA_ "U_P702_MY2021_Rx" SG_ 948 Tire_Press_LR_OLR_Stat 1;
BA_ "U_CX727_MY2021_Rx" SG_ 948 Tire_Press_LR_OLR_Stat 1;
BA_ "U_U55X_MY2022_Rx" SG_ 948 Tire_Press_RR_ORR_Stat 1;
BA_ "U_T6_MCA_MY2020_Rx" SG_ 948 Tire_Press_RR_ORR_Stat 1;
BA_ "U_P702_MY2021_Rx" SG_ 948 Tire_Press_RR_ORR_Stat 1;
BA_ "U_CX727_MY2021_Rx" SG_ 948 Tire_Press_RR_ORR_Stat 1;
BA_ "U_U55X_MY2022_Rx" SG_ 948 Tire_Press_RF_Stat 1;
BA_ "U_T6_MCA_MY2020_Rx" SG_ 948 Tire_Press_RF_Stat 1;
BA_ "U_P702_MY2021_Rx" SG_ 948 Tire_Press_RF_Stat 1;
BA_ "U_CX727_MY2021_Rx" SG_ 948 Tire_Press_RF_Stat 1;
BA_ "U_U55X_MY2022_Rx" SG_ 948 Tire_Press_LF_Stat 1;
BA_ "U_T6_MCA_MY2020_Rx" SG_ 948 Tire_Press_LF_Stat 1;
BA_ "U_P702_MY2021_Rx" SG_ 948 Tire_Press_LF_Stat 1;
BA_ "U_CX727_MY2021_Rx" SG_ 948 Tire_Press_LF_Stat 1;
BA_ "U_U55X_MY2022_Rx" SG_ 948 Tire_Press_System_Stat 1;
BA_ "U_T6_MCA_MY2020_Rx" SG_ 948 Tire_Press_System_Stat 1;
BA_ "U_P702_MY2021_Rx" SG_ 948 Tire_Press_System_Stat 1;
BA_ "U_CX727_MY2021_Rx" SG_ 948 Tire_Press_System_Stat 1;
BA_ "U_U55X_MY2022_Rx" SG_ 948 Tire_Press_Telltale 1;
BA_ "U_T6_MCA_MY2020_Rx" SG_ 948 Tire_Press_Telltale 1;
BA_ "U_P702_MY2021_Rx" SG_ 948 Tire_Press_Telltale 1;
BA_ "U_CX727_MY2021_Rx" SG_ 948 Tire_Press_Telltale 1;
BA_ "U_U55X_MY2022_Rx" SG_ 948 TirePReset_D_Stat 1;
BA_ "U_T6_MCA_MY2020_Rx" SG_ 948 TirePReset_D_Stat 1;
BA_ "U_P702_MY2021_Rx" SG_ 948 TirePReset_D_Stat 1;
BA_ "U_CX727_MY2021_Rx" SG_ 948 TirePReset_D_Stat 1;
BA_ "U_U55X_MY2022_Tx" SG_ 1361 BCMB_Network_Mgmt 1;
BA_ "GenSigSendType" SG_ 1361 BCMB_Network_Mgmt 3;
BA_ "ContentDependant" SG_ 840 FohT2Friday_T_Rq 1;
BA_ "ContentDependant" SG_ 840 FohT1Friday_T_Rq 1;
BA_ "ContentDependant" SG_ 840 FohT2Wednesday_T_Rq 1;
BA_ "ContentDependant" SG_ 840 FohT2Tuesday_T_Rq 1;
BA_ "ContentDependant" SG_ 840 FohT2Thursday_T_Rq 1;
BA_ "ContentDependant" SG_ 840 FohT2Sunday_T_Rq 1;
BA_ "ContentDependant" SG_ 840 FohT2Saturday_T_Rq 1;
BA_ "ContentDependant" SG_ 840 FohT2Monday_T_Rq 1;
BA_ "ContentDependant" SG_ 840 FohT1Wednesday_T_Rq 1;
BA_ "ContentDependant" SG_ 840 FohT1Tuesday_T_Rq 1;
BA_ "ContentDependant" SG_ 840 FohT1Thursday_T_Rq 1;
BA_ "ContentDependant" SG_ 840 FohT1Sunday_T_Rq 1;
BA_ "ContentDependant" SG_ 840 FohT1Saturday_T_Rq 1;
BA_ "ContentDependant" SG_ 840 FohT1Monday_T_Rq 1;
BA_ "U_CD542_MY2021_Rx" SG_ 132 GlblClkYr_No_Actl 1;
BA_ "U_T6_MCA_MY2020_Rx" SG_ 132 GlblClkYr_No_Actl 1;
BA_ "U_P702_MY2021_Rx" SG_ 132 GlblClkYr_No_Actl 1;
BA_ "U_CD542_MY2021_Rx" SG_ 132 GlblClkScnd_No_Actl 1;
BA_ "U_T6_MCA_MY2020_Rx" SG_ 132 GlblClkScnd_No_Actl 1;
BA_ "U_P702_MY2021_Rx" SG_ 132 GlblClkScnd_No_Actl 1;
BA_ "U_CD542_MY2021_Rx" SG_ 132 GlblClkMnte_No_Actl 1;
BA_ "U_T6_MCA_MY2020_Rx" SG_ 132 GlblClkMnte_No_Actl 1;
BA_ "U_P702_MY2021_Rx" SG_ 132 GlblClkMnte_No_Actl 1;
BA_ "U_CD542_MY2021_Rx" SG_ 132 GlblClkHr_No_Actl 1;
BA_ "U_T6_MCA_MY2020_Rx" SG_ 132 GlblClkHr_No_Actl 1;
BA_ "U_P702_MY2021_Rx" SG_ 132 GlblClkHr_No_Actl 1;
BA_ "U_CD542_MY2021_Rx" SG_ 132 GlblClkDay_No_Actl 1;
BA_ "U_T6_MCA_MY2020_Rx" SG_ 132 GlblClkDay_No_Actl 1;
BA_ "U_P702_MY2021_Rx" SG_ 132 GlblClkDay_No_Actl 1;
BA_ "GenSigSendType" SG_ 1796 TesterPhysicalReqSFMA 3;
BA_ "U_U55X_MY2022_Rx" SG_ 1927 TesterPhysicalReqSCMJ 1;
BA_ "U_T6_MCA_MY2020_Rx" SG_ 1927 TesterPhysicalReqSCMJ 1;
BA_ "GenSigSendType" SG_ 1927 TesterPhysicalReqSCMJ 3;
BA_ "U_U55X_MY2022_Tx" SG_ 1935 TesterPhysicalResSCMJ 1;
BA_ "U_T6_MCA_MY2020_Tx" SG_ 1935 TesterPhysicalResSCMJ 1;
BA_ "GenSigSendType" SG_ 1935 TesterPhysicalResSCMJ 3;
BA_ "U_U55X_MY2022_Tx" SG_ 1514 SCMJ_GWOnBoardTester 1;
BA_ "U_T6_MCA_MY2020_Tx" SG_ 1514 SCMJ_GWOnBoardTester 1;
BA_ "GenSigStartValue" SG_ 1514 SCMJ_GWOnBoardTester 255;
BA_ "ContentDependant" SG_ 1514 SCMJ_GWOnBoardTester 1;
BA_ "GenSigStartValueInteger" SG_ 1514 SCMJ_GWOnBoardTester 255;
BA_ "U_U55X_MY2022_Tx" SG_ 1514 SCMJ_GWNMProxy 1;
BA_ "U_T6_MCA_MY2020_Tx" SG_ 1514 SCMJ_GWNMProxy 1;
BA_ "GenSigStartValue" SG_ 1514 SCMJ_GWNMProxy 255;
BA_ "ContentDependant" SG_ 1514 SCMJ_GWNMProxy 1;
BA_ "GenSigStartValueInteger" SG_ 1514 SCMJ_GWNMProxy 255;
BA_ "U_U55X_MY2022_Tx" SG_ 1514 SCMJ_AutoSarNMReserved4 1;
BA_ "U_T6_MCA_MY2020_Tx" SG_ 1514 SCMJ_AutoSarNMReserved4 1;
BA_ "GenSigStartValue" SG_ 1514 SCMJ_AutoSarNMReserved4 255;
BA_ "ContentDependant" SG_ 1514 SCMJ_AutoSarNMReserved4 1;
BA_ "GenSigStartValueInteger" SG_ 1514 SCMJ_AutoSarNMReserved4 255;
BA_ "U_U55X_MY2022_Tx" SG_ 1514 SCMJ_AutoSarNMReserved3 1;
BA_ "U_T6_MCA_MY2020_Tx" SG_ 1514 SCMJ_AutoSarNMReserved3 1;
BA_ "GenSigStartValue" SG_ 1514 SCMJ_AutoSarNMReserved3 255;
BA_ "ContentDependant" SG_ 1514 SCMJ_AutoSarNMReserved3 1;
BA_ "GenSigStartValueInteger" SG_ 1514 SCMJ_AutoSarNMReserved3 255;
BA_ "U_U55X_MY2022_Tx" SG_ 1514 SCMJ_AutoSarNMReserved2 1;
BA_ "U_T6_MCA_MY2020_Tx" SG_ 1514 SCMJ_AutoSarNMReserved2 1;
BA_ "GenSigStartValue" SG_ 1514 SCMJ_AutoSarNMReserved2 255;
BA_ "ContentDependant" SG_ 1514 SCMJ_AutoSarNMReserved2 1;
BA_ "GenSigStartValueInteger" SG_ 1514 SCMJ_AutoSarNMReserved2 255;
BA_ "U_U55X_MY2022_Tx" SG_ 1514 SCMJ_AutoSarNMReserved1 1;
BA_ "U_T6_MCA_MY2020_Tx" SG_ 1514 SCMJ_AutoSarNMReserved1 1;
BA_ "GenSigStartValue" SG_ 1514 SCMJ_AutoSarNMReserved1 255;
BA_ "ContentDependant" SG_ 1514 SCMJ_AutoSarNMReserved1 1;
BA_ "GenSigStartValueInteger" SG_ 1514 SCMJ_AutoSarNMReserved1 255;
BA_ "U_U55X_MY2022_Tx" SG_ 1514 SCMJ_AutoSarNMNodeId 1;
BA_ "U_T6_MCA_MY2020_Tx" SG_ 1514 SCMJ_AutoSarNMNodeId 1;
BA_ "GenSigStartValue" SG_ 1514 SCMJ_AutoSarNMNodeId 234;
BA_ "ContentDependant" SG_ 1514 SCMJ_AutoSarNMNodeId 1;
BA_ "GenSigStartValueInteger" SG_ 1514 SCMJ_AutoSarNMNodeId 234;
BA_ "U_U55X_MY2022_Tx" SG_ 1514 SCMJ_AutoSarNMControl 1;
BA_ "U_T6_MCA_MY2020_Tx" SG_ 1514 SCMJ_AutoSarNMControl 1;
BA_ "ContentDependant" SG_ 1514 SCMJ_AutoSarNMControl 1;
BA_ "WakeupSignal" SG_ 945 PwLoApim_T_Actl 1;
BA_ "WakeupSignal" SG_ 945 PrkLckCtlMsgTxt_D2_Rq 1;
BA_ "WakeupSignal" SG_ 945 KeyPadCodeDgt6_D_Dsply 1;
BA_ "WakeupSignal" SG_ 945 KeyPadCodeDgt5_D_Dsply 1;
BA_ "WakeupSignal" SG_ 945 KeyPadCodeDgt4_D_Dsply 1;
BA_ "WakeupSignal" SG_ 945 KeyPadCodeDgt3_D_Dsply 1;
BA_ "WakeupSignal" SG_ 945 KeyPadCodeDgt2_D_Dsply 1;
BA_ "WakeupSignal" SG_ 945 KeyPadCodeDgt1_D_Dsply 1;
BA_ "U_CD764_MY2022_Rx" SG_ 945 KeyOffMde_D_Actl 1;
BA_ "U_P702_MY2021_Rx" SG_ 945 KeyOffMde_D_Actl 1;
BA_ "U_U55X_MY2022_Rx" SG_ 945 KeyOffMde_D_Actl 1;
BA_ "U_CD542_MY2021_Rx" SG_ 945 KeyOffMde_D_Actl 1;
BA_ "U_CX727_MY2021_Rx" SG_ 945 KeyOffMde_D_Actl 1;
BA_ "U_T6_MCA_MY2020_Rx" SG_ 945 KeyOffMde_D_Actl 1;
BA_ "GenSigSendType" SG_ 945 KeyOffMde_D_Actl 3;
BA_ "GenSigSendType" SG_ 1804 TesterPhysicalResSFMA 3;
BA_ "U_CD764_MY2022_Rx" SG_ 981 PreCondActv_B_Actl_UB 1;
BA_ "U_U55X_MY2022_Rx" SG_ 981 PreCondActv_B_Actl_UB 1;
BA_ "U_CD542_MY2021_Rx" SG_ 981 PreCondActv_B_Actl_UB 1;
BA_ "U_T6_MCA_MY2020_Rx" SG_ 981 PreCondActv_B_Actl_UB 1;
BA_ "U_CX727_MY2021_Rx" SG_ 981 PreCondActv_B_Actl_UB 1;
BA_ "U_CD764_MY2022_Rx" SG_ 981 HvacPrecondRecirc_D_Rq_UB 1;
BA_ "U_U55X_MY2022_Rx" SG_ 981 HvacPrecondRecirc_D_Rq_UB 1;
BA_ "U_CD542_MY2021_Rx" SG_ 981 HvacPrecondRecirc_D_Rq_UB 1;
BA_ "U_CX727_MY2021_Rx" SG_ 981 HvacPrecondRecirc_D_Rq_UB 1;
BA_ "U_CD764_MY2022_Rx" SG_ 981 HvacPrecondMode2_D_Rq_UB 1;
BA_ "U_U55X_MY2022_Rx" SG_ 981 HvacPrecondMode2_D_Rq_UB 1;
BA_ "U_CD542_MY2021_Rx" SG_ 981 HvacPrecondMode2_D_Rq_UB 1;
BA_ "U_CX727_MY2021_Rx" SG_ 981 HvacPrecondMode2_D_Rq_UB 1;
BA_ "U_CD764_MY2022_Rx" SG_ 981 HvacPrecondBlwr2_D_Rq_UB 1;
BA_ "U_U55X_MY2022_Rx" SG_ 981 HvacPrecondBlwr2_D_Rq_UB 1;
BA_ "U_CD542_MY2021_Rx" SG_ 981 HvacPrecondBlwr2_D_Rq_UB 1;
BA_ "U_CX727_MY2021_Rx" SG_ 981 HvacPrecondBlwr2_D_Rq_UB 1;
BA_ "U_CD764_MY2022_Rx" SG_ 981 HvacPrecondAC_D_Rq_UB 1;
BA_ "U_U55X_MY2022_Rx" SG_ 981 HvacPrecondAC_D_Rq_UB 1;
BA_ "U_CD542_MY2021_Rx" SG_ 981 HvacPrecondAC_D_Rq_UB 1;
BA_ "U_CX727_MY2021_Rx" SG_ 981 HvacPrecondAC_D_Rq_UB 1;
BA_ "U_CD764_MY2022_Rx" SG_ 981 HvacPrecond_Te_Rq_UB 1;
BA_ "U_U55X_MY2022_Rx" SG_ 981 HvacPrecond_Te_Rq_UB 1;
BA_ "U_CD542_MY2021_Rx" SG_ 981 HvacPrecond_Te_Rq_UB 1;
BA_ "U_CX727_MY2021_Rx" SG_ 981 HvacPrecond_Te_Rq_UB 1;
BA_ "U_CD764_MY2022_Rx" SG_ 981 DrvCondTpRrDefrs_B_Rq_UB 1;
BA_ "U_U55X_MY2022_Rx" SG_ 981 DrvCondTpRrDefrs_B_Rq_UB 1;
BA_ "U_CD542_MY2021_Rx" SG_ 981 DrvCondTpRrDefrs_B_Rq_UB 1;
BA_ "U_CX727_MY2021_Rx" SG_ 981 DrvCondTpRrDefrs_B_Rq_UB 1;
BA_ "U_CD764_MY2022_Rx" SG_ 981 PreCondActv_B_Actl 1;
BA_ "U_U55X_MY2022_Rx" SG_ 981 PreCondActv_B_Actl 1;
BA_ "U_CD542_MY2021_Rx" SG_ 981 PreCondActv_B_Actl 1;
BA_ "U_T6_MCA_MY2020_Rx" SG_ 981 PreCondActv_B_Actl 1;
BA_ "U_CX727_MY2021_Rx" SG_ 981 PreCondActv_B_Actl 1;
BA_ "U_CD764_MY2022_Rx" SG_ 981 HvacPrecondRecirc_D_Rq 1;
BA_ "U_U55X_MY2022_Rx" SG_ 981 HvacPrecondRecirc_D_Rq 1;
BA_ "U_CD542_MY2021_Rx" SG_ 981 HvacPrecondRecirc_D_Rq 1;
BA_ "U_CX727_MY2021_Rx" SG_ 981 HvacPrecondRecirc_D_Rq 1;
BA_ "U_CD764_MY2022_Rx" SG_ 981 HvacPrecondMode2_D_Rq 1;
BA_ "U_U55X_MY2022_Rx" SG_ 981 HvacPrecondMode2_D_Rq 1;
BA_ "U_CD542_MY2021_Rx" SG_ 981 HvacPrecondMode2_D_Rq 1;
BA_ "U_CX727_MY2021_Rx" SG_ 981 HvacPrecondMode2_D_Rq 1;
BA_ "ContentDependant" SG_ 981 HvacPrecondMode2_D_Rq 1;
BA_ "WakeupSignal" SG_ 981 HvacPrecondMode2_D_Rq 1;
BA_ "U_CD764_MY2022_Rx" SG_ 981 HvacPrecondBlwr2_D_Rq 1;
BA_ "U_U55X_MY2022_Rx" SG_ 981 HvacPrecondBlwr2_D_Rq 1;
BA_ "U_CD542_MY2021_Rx" SG_ 981 HvacPrecondBlwr2_D_Rq 1;
BA_ "U_CX727_MY2021_Rx" SG_ 981 HvacPrecondBlwr2_D_Rq 1;
BA_ "ContentDependant" SG_ 981 HvacPrecondBlwr2_D_Rq 1;
BA_ "WakeupSignal" SG_ 981 HvacPrecondBlwr2_D_Rq 1;
BA_ "U_CD764_MY2022_Rx" SG_ 981 HvacPrecondAC_D_Rq 1;
BA_ "U_U55X_MY2022_Rx" SG_ 981 HvacPrecondAC_D_Rq 1;
BA_ "U_CD542_MY2021_Rx" SG_ 981 HvacPrecondAC_D_Rq 1;
BA_ "U_CX727_MY2021_Rx" SG_ 981 HvacPrecondAC_D_Rq 1;
BA_ "U_CD764_MY2022_Rx" SG_ 981 HvacPrecond_Te_Rq 1;
BA_ "U_U55X_MY2022_Rx" SG_ 981 HvacPrecond_Te_Rq 1;
BA_ "U_CD542_MY2021_Rx" SG_ 981 HvacPrecond_Te_Rq 1;
BA_ "U_CX727_MY2021_Rx" SG_ 981 HvacPrecond_Te_Rq 1;
BA_ "GenSigStartValue" SG_ 981 HvacPrecond_Te_Rq 2;
BA_ "GenSigStartValueInteger" SG_ 981 HvacPrecond_Te_Rq 2;
BA_ "U_CD764_MY2022_Rx" SG_ 981 DrvCondTpRrDefrs_B_Rq 1;
BA_ "U_U55X_MY2022_Rx" SG_ 981 DrvCondTpRrDefrs_B_Rq 1;
BA_ "U_CD542_MY2021_Rx" SG_ 981 DrvCondTpRrDefrs_B_Rq 1;
BA_ "U_CX727_MY2021_Rx" SG_ 981 DrvCondTpRrDefrs_B_Rq 1;
BA_ "U_U55X_MY2022_Tx" SG_ 1446 RGTM_GWOnBoardTester 1;
BA_ "U_CD542_MY2021_Tx" SG_ 1446 RGTM_GWOnBoardTester 1;
BA_ "U_T6_MCA_MY2020_Tx" SG_ 1446 RGTM_GWOnBoardTester 1;
BA_ "U_CX727_MY2021_Tx" SG_ 1446 RGTM_GWOnBoardTester 1;
BA_ "GenSigStartValue" SG_ 1446 RGTM_GWOnBoardTester 255;
BA_ "ContentDependant" SG_ 1446 RGTM_GWOnBoardTester 1;
BA_ "GenSigStartValueInteger" SG_ 1446 RGTM_GWOnBoardTester 255;
BA_ "U_U55X_MY2022_Tx" SG_ 1446 RGTM_GWNMProxy 1;
BA_ "U_CD542_MY2021_Tx" SG_ 1446 RGTM_GWNMProxy 1;
BA_ "U_T6_MCA_MY2020_Tx" SG_ 1446 RGTM_GWNMProxy 1;
BA_ "U_CX727_MY2021_Tx" SG_ 1446 RGTM_GWNMProxy 1;
BA_ "GenSigStartValue" SG_ 1446 RGTM_GWNMProxy 255;
BA_ "ContentDependant" SG_ 1446 RGTM_GWNMProxy 1;
BA_ "GenSigStartValueInteger" SG_ 1446 RGTM_GWNMProxy 255;
BA_ "U_U55X_MY2022_Tx" SG_ 1446 RGTM_AutoSarNMReserved4 1;
BA_ "U_CD542_MY2021_Tx" SG_ 1446 RGTM_AutoSarNMReserved4 1;
BA_ "U_T6_MCA_MY2020_Tx" SG_ 1446 RGTM_AutoSarNMReserved4 1;
BA_ "U_CX727_MY2021_Tx" SG_ 1446 RGTM_AutoSarNMReserved4 1;
BA_ "GenSigStartValue" SG_ 1446 RGTM_AutoSarNMReserved4 255;
BA_ "ContentDependant" SG_ 1446 RGTM_AutoSarNMReserved4 1;
BA_ "GenSigStartValueInteger" SG_ 1446 RGTM_AutoSarNMReserved4 255;
BA_ "U_U55X_MY2022_Tx" SG_ 1446 RGTM_AutoSarNMReserved3 1;
BA_ "U_CD542_MY2021_Tx" SG_ 1446 RGTM_AutoSarNMReserved3 1;
BA_ "U_T6_MCA_MY2020_Tx" SG_ 1446 RGTM_AutoSarNMReserved3 1;
BA_ "U_CX727_MY2021_Tx" SG_ 1446 RGTM_AutoSarNMReserved3 1;
BA_ "GenSigStartValue" SG_ 1446 RGTM_AutoSarNMReserved3 255;
BA_ "ContentDependant" SG_ 1446 RGTM_AutoSarNMReserved3 1;
BA_ "GenSigStartValueInteger" SG_ 1446 RGTM_AutoSarNMReserved3 255;
BA_ "U_U55X_MY2022_Tx" SG_ 1446 RGTM_AutoSarNMReserved2 1;
BA_ "U_CD542_MY2021_Tx" SG_ 1446 RGTM_AutoSarNMReserved2 1;
BA_ "U_T6_MCA_MY2020_Tx" SG_ 1446 RGTM_AutoSarNMReserved2 1;
BA_ "U_CX727_MY2021_Tx" SG_ 1446 RGTM_AutoSarNMReserved2 1;
BA_ "GenSigStartValue" SG_ 1446 RGTM_AutoSarNMReserved2 255;
BA_ "ContentDependant" SG_ 1446 RGTM_AutoSarNMReserved2 1;
BA_ "GenSigStartValueInteger" SG_ 1446 RGTM_AutoSarNMReserved2 255;
BA_ "U_U55X_MY2022_Tx" SG_ 1446 RGTM_AutoSarNMReserved1 1;
BA_ "U_CD542_MY2021_Tx" SG_ 1446 RGTM_AutoSarNMReserved1 1;
BA_ "U_T6_MCA_MY2020_Tx" SG_ 1446 RGTM_AutoSarNMReserved1 1;
BA_ "U_CX727_MY2021_Tx" SG_ 1446 RGTM_AutoSarNMReserved1 1;
BA_ "GenSigStartValue" SG_ 1446 RGTM_AutoSarNMReserved1 255;
BA_ "ContentDependant" SG_ 1446 RGTM_AutoSarNMReserved1 1;
BA_ "GenSigStartValueInteger" SG_ 1446 RGTM_AutoSarNMReserved1 255;
BA_ "U_U55X_MY2022_Tx" SG_ 1446 RGTM_AutoSarNMNodeId 1;
BA_ "U_CD542_MY2021_Tx" SG_ 1446 RGTM_AutoSarNMNodeId 1;
BA_ "U_T6_MCA_MY2020_Tx" SG_ 1446 RGTM_AutoSarNMNodeId 1;
BA_ "U_CX727_MY2021_Tx" SG_ 1446 RGTM_AutoSarNMNodeId 1;
BA_ "GenSigStartValue" SG_ 1446 RGTM_AutoSarNMNodeId 166;
BA_ "ContentDependant" SG_ 1446 RGTM_AutoSarNMNodeId 1;
BA_ "GenSigStartValueInteger" SG_ 1446 RGTM_AutoSarNMNodeId 166;
BA_ "U_U55X_MY2022_Tx" SG_ 1446 RGTM_AutoSarNMControl 1;
BA_ "U_CD542_MY2021_Tx" SG_ 1446 RGTM_AutoSarNMControl 1;
BA_ "U_T6_MCA_MY2020_Tx" SG_ 1446 RGTM_AutoSarNMControl 1;
BA_ "U_CX727_MY2021_Tx" SG_ 1446 RGTM_AutoSarNMControl 1;
BA_ "ContentDependant" SG_ 1446 RGTM_AutoSarNMControl 1;
BA_ "GenSigSendType" SG_ 1898 TesterPhysicalResDCMF 3;
BA_ "U_U55X_MY2022_Rx" SG_ 1959 TesterPhysicalReqFCIM 1;
BA_ "U_T6_MCA_MY2020_Rx" SG_ 1959 TesterPhysicalReqFCIM 1;
BA_ "GenSigSendType" SG_ 1959 TesterPhysicalReqFCIM 3;
BA_ "U_U55X_MY2022_Tx" SG_ 1967 TesterPhysicalResFCIM 1;
BA_ "U_T6_MCA_MY2020_Tx" SG_ 1967 TesterPhysicalResFCIM 1;
BA_ "GenSigSendType" SG_ 1967 TesterPhysicalResFCIM 3;
BA_ "U_U55X_MY2022_Tx" SG_ 1501 FCIM_GWOnBoardTester 1;
BA_ "U_T6_MCA_MY2020_Tx" SG_ 1501 FCIM_GWOnBoardTester 1;
BA_ "GenSigStartValue" SG_ 1501 FCIM_GWOnBoardTester 255;
BA_ "ContentDependant" SG_ 1501 FCIM_GWOnBoardTester 1;
BA_ "GenSigStartValueInteger" SG_ 1501 FCIM_GWOnBoardTester 255;
BA_ "U_U55X_MY2022_Tx" SG_ 1501 FCIM_GWNMProxy 1;
BA_ "U_T6_MCA_MY2020_Tx" SG_ 1501 FCIM_GWNMProxy 1;
BA_ "GenSigStartValue" SG_ 1501 FCIM_GWNMProxy 255;
BA_ "ContentDependant" SG_ 1501 FCIM_GWNMProxy 1;
BA_ "GenSigStartValueInteger" SG_ 1501 FCIM_GWNMProxy 255;
BA_ "U_U55X_MY2022_Tx" SG_ 1501 FCIM_AutoSarNMReserved4 1;
BA_ "U_T6_MCA_MY2020_Tx" SG_ 1501 FCIM_AutoSarNMReserved4 1;
BA_ "GenSigStartValue" SG_ 1501 FCIM_AutoSarNMReserved4 255;
BA_ "ContentDependant" SG_ 1501 FCIM_AutoSarNMReserved4 1;
BA_ "GenSigStartValueInteger" SG_ 1501 FCIM_AutoSarNMReserved4 255;
BA_ "U_U55X_MY2022_Tx" SG_ 1501 FCIM_AutoSarNMReserved3 1;
BA_ "U_T6_MCA_MY2020_Tx" SG_ 1501 FCIM_AutoSarNMReserved3 1;
BA_ "GenSigStartValue" SG_ 1501 FCIM_AutoSarNMReserved3 255;
BA_ "ContentDependant" SG_ 1501 FCIM_AutoSarNMReserved3 1;
BA_ "GenSigStartValueInteger" SG_ 1501 FCIM_AutoSarNMReserved3 255;
BA_ "U_U55X_MY2022_Tx" SG_ 1501 FCIM_AutoSarNMReserved2 1;
BA_ "U_T6_MCA_MY2020_Tx" SG_ 1501 FCIM_AutoSarNMReserved2 1;
BA_ "GenSigStartValue" SG_ 1501 FCIM_AutoSarNMReserved2 255;
BA_ "ContentDependant" SG_ 1501 FCIM_AutoSarNMReserved2 1;
BA_ "GenSigStartValueInteger" SG_ 1501 FCIM_AutoSarNMReserved2 255;
BA_ "U_U55X_MY2022_Tx" SG_ 1501 FCIM_AutoSarNMReserved1 1;
BA_ "U_T6_MCA_MY2020_Tx" SG_ 1501 FCIM_AutoSarNMReserved1 1;
BA_ "GenSigStartValue" SG_ 1501 FCIM_AutoSarNMReserved1 255;
BA_ "ContentDependant" SG_ 1501 FCIM_AutoSarNMReserved1 1;
BA_ "GenSigStartValueInteger" SG_ 1501 FCIM_AutoSarNMReserved1 255;
BA_ "U_U55X_MY2022_Tx" SG_ 1501 FCIM_AutoSarNMNodeId 1;
BA_ "U_T6_MCA_MY2020_Tx" SG_ 1501 FCIM_AutoSarNMNodeId 1;
BA_ "GenSigStartValue" SG_ 1501 FCIM_AutoSarNMNodeId 221;
BA_ "ContentDependant" SG_ 1501 FCIM_AutoSarNMNodeId 1;
BA_ "GenSigStartValueInteger" SG_ 1501 FCIM_AutoSarNMNodeId 150;
BA_ "U_U55X_MY2022_Tx" SG_ 1501 FCIM_AutoSarNMControl 1;
BA_ "U_T6_MCA_MY2020_Tx" SG_ 1501 FCIM_AutoSarNMControl 1;
BA_ "ContentDependant" SG_ 1501 FCIM_AutoSarNMControl 1;
VAL_ 883 PmCabn10Mnte_Conc_Actl 511 "Faulty" 510 "NoDataExists" ;
VAL_ 883 PmCabn08Mnte_Conc_Actl 511 "Faulty" 510 "NoDataExists" ;
VAL_ 883 PmCabn06Mnte_Conc_Actl 511 "Faulty" 510 "NoDataExists" ;
VAL_ 883 PmCabn04Mnte_Conc_Actl 511 "Faulty" 510 "NoDataExists" ;
VAL_ 883 PmCabn02Mnte_Conc_Actl 511 "Faulty" 510 "NoDataExists" ;
VAL_ 884 UltraFreshCabn_D_Stat 7 "NotUsed_2" 6 "NotUsed_1" 5 "NotSupported" 4 "Interrupted" 3 "Complete" 2 "Active" 1 "Inactive" 0 "Null" ;
VAL_ 884 PmSnsCabn_D_Stat 7 "NotUsed_1" 6 "IntermittentInhibit" 5 "NoIssue" 4 "BlankField" 3 "ReplaceSensor" 2 "CleanSensor" 1 "Unsupported" 0 "Initializing" ;
VAL_ 884 PmCabn_Conc_Actl 511 "Faulty" 510 "NoDataExists" ;
VAL_ 884 PmCabn20Mnte_Conc_Actl 511 "Faulty" 510 "NoDataExists" ;
VAL_ 884 PmCabn18Mnte_Conc_Actl 511 "Faulty" 510 "NoDataExists" ;
VAL_ 884 PmCabn16Mnte_Conc_Actl 511 "Faulty" 510 "NoDataExists" ;
VAL_ 884 PmCabn14Mnte_Conc_Actl 511 "Faulty" 510 "NoDataExists" ;
VAL_ 884 PmCabn12Mnte_Conc_Actl 511 "Faulty" 510 "NoDataExists" ;
VAL_ 674 RearAudioCtlLck_D_Stat 2 "Unlocked" 1 "Locked" 0 "Null" ;
VAL_ 674 RACM_Coding_BtnID_D 1 "Pressed" 0 "Not_Pressed" ;
VAL_ 674 RACM_Coding_BtnID_C 1 "Pressed" 0 "Not_Pressed" ;
VAL_ 674 RACM_Coding_BtnID_B 1 "Pressed" 0 "Not_Pressed" ;
VAL_ 674 RACM_Coding_BtnID_A 1 "Pressed" 0 "Not_Pressed" ;
VAL_ 674 ArmrestStwdRear_B_Stat 1 "Yes" 0 "No" ;
VAL_ 841 FohAddHeater_D_Stat 3 "NotUsed" 2 "On" 1 "Off" 0 "NoModeSelected" ;
VAL_ 1075 ACU_RadioSeekMode2_St 16 "ContAutoDown" 15 "ContAutoUp" 14 "PISeek" 13 "TpSeek" 12 "Autostore" 11 "PtySeekDown" 10 "PtySeekUp" 9 "ScanDown" 8 "ScanUp" 7 "ContManualDown" 6 "ContManualUp" 5 "ManSingleStepDown" 4 "ManSingleStepUp" 3 "AutoDown" 2 "AutoUp" 1 "SeekOff" 0 "Invalid" ;
VAL_ 1075 ACU_CurrTUBand_St 10 "SAT2" 9 "SAT1" 8 "DAB2" 7 "DAB1" 6 "Fm3" 5 "AmAst" 4 "Am" 3 "FmAst" 2 "Fm2" 1 "Fm1" 0 "Invalid" 13 "reserved1" 15 "reserved_last" 12 "DAB3" 11 "SAT3" ;
VAL_ 1075 ACU_RadioSeekMode2_St_UB 1 "Fresh_data" 0 "Unchanged_data" ;
VAL_ 1075 ACU_CurrTUBand_St_UB 1 "Fresh_data" 0 "Unchanged_data" ;
VAL_ 1075 ACU_CurrentFreq_St_UB 1 "Fresh_data" 0 "Unchanged_data" ;
VAL_ 1075 CtaBrk_D_Stat_UB 1 "Fresh_data" 0 "Unchanged_data" ;
VAL_ 1075 CtaBrk_D_Stat 3 "Denied" 2 "Active" 1 "Open" 0 "Closed" ;
VAL_ 1075 SelDrvMdePt_D_Rq_UB 1 "Fresh_data" 0 "Unchanged_data" ;
VAL_ 1075 SelDrvMdePt_D_Rq 31 "Faulty" 30 "NotUsed15" 29 "NotUsed14" 28 "NotUsed13" 27 "NotUsed12" 26 "NotUsed11" 25 "NotUsed10" 24 "NotUsed9" 23 "NotUsed8" 22 "NotUsed7" 21 "CustomMode" 20 "TrackMode" 19 "OnePedalDrive" 18 "EvLaterChargerMode" 17 "EvNowMode" 16 "DragMode" 15 "HighSpeedDesertMode_Baja" 14 "SportAdaptiveMode" 13 "NotAvailable_13" 12 "NotAvailable_12" 11 "NotAvailable_11" 10 "NotAvailable_10" 9 "RockCrawlMode" 8 "MudRutsMode" 7 "SandMode" 6 "EconomyMode" 5 "GrassGravelSnow" 4 "NotAvailable_04" 3 "TowHaulMode" 2 "NotAvailable_02" 1 "SportMode" 0 "NormalMode" ;
VAL_ 1075 PrkAidSnsRrCrnr_D_Stat 15 "Zone_15" 14 "Zone_14" 13 "Zone_13" 12 "Zone_12" 11 "Zone_11" 10 "Zone_10" 9 "Zone_9" 8 "Zone_8" 7 "Zone_7" 6 "Zone_6" 5 "Zone_5" 4 "Zone_4" 3 "Zone_3" 2 "Zone_2" 1 "Zone_1" 0 "Off" ;
VAL_ 1075 PrkAidSnsRrCntr_D_Stat 15 "Zone_15" 14 "Zone_14" 13 "Zone_13" 12 "Zone_12" 11 "Zone_11" 10 "Zone_10" 9 "Zone_9" 8 "Zone_8" 7 "Zone_7" 6 "Zone_6" 5 "Zone_5" 4 "Zone_4" 3 "Zone_3" 2 "Zone_2" 1 "Zone_1" 0 "Off" ;
VAL_ 1075 PrkAidSnsRlCrnr_D_Stat 15 "Zone_15" 14 "Zone_14" 13 "Zone_13" 12 "Zone_12" 11 "Zone_11" 10 "Zone_10" 9 "Zone_9" 8 "Zone_8" 7 "Zone_7" 6 "Zone_6" 5 "Zone_5" 4 "Zone_4" 3 "Zone_3" 2 "Zone_2" 1 "Zone_1" 0 "Off" ;
VAL_ 1075 PrkAidSnsRlCntr_D_Stat 15 "Zone_15" 14 "Zone_14" 13 "Zone_13" 12 "Zone_12" 11 "Zone_11" 10 "Zone_10" 9 "Zone_9" 8 "Zone_8" 7 "Zone_7" 6 "Zone_6" 5 "Zone_5" 4 "Zone_4" 3 "Zone_3" 2 "Zone_2" 1 "Zone_1" 0 "Off" ;
VAL_ 1075 PrkAidSnsRrCrnr_D_Stat_UB 1 "Fresh_data" 0 "Unchanged_data" ;
VAL_ 1075 PrkAidSnsRrCntr_D_Stat_UB 1 "Fresh_data" 0 "Unchanged_data" ;
VAL_ 1075 PrkAidSnsRlCntr_D_Stat_UB 1 "Fresh_data" 0 "Unchanged_data" ;
VAL_ 1075 PrkAidSnsRlCrnr_D_Stat_UB 1 "Fresh_data" 0 "Unchanged_data" ;
VAL_ 1075 BttOn_B_Rq_UB 1 "Fresh_data" 0 "Unchanged_data" ;
VAL_ 1075 Btt_L_Actl_UB 1 "Fresh_data" 0 "Unchanged_data" ;
VAL_ 1075 BttOn_B_Rq 1 "On" 0 "Off" ;
VAL_ 1075 Btt_L_Actl 127 "Faulty" 126 "NoDataExists" ;
VAL_ 1075 ArmrestStwdRear_B_Stat_UB 1 "Fresh_data" 0 "Unchanged_data" ;
VAL_ 1075 ArmrestStwdRear_B_Stat 1 "Yes" 0 "No" ;
VAL_ 1166 DrHandleInnrRr_B_Stat 1 "Pulled" 0 "AtRest" ;
VAL_ 1166 DrLatchRrMsgTxt_D_Rq 7 "Message7" 6 "Message6" 5 "Message5" 4 "Message4" 3 "Message3" 2 "Message2" 1 "Message1" 0 "NoMessage" ;
VAL_ 1166 DrLatchRr_B_Falt 1 "Yes" 0 "No" ;
VAL_ 1166 DrLatchLckRr_B_Stat 1 "Locked" 0 "Unlock" ;
VAL_ 1166 ChildLckFdbckRr_B_Stat 1 "Locked" 0 "Unlock" ;
VAL_ 1165 DrHandleInnrRl_B_Stat 1 "Pulled" 0 "AtRest" ;
VAL_ 1165 DrLatchRlMsgTxt_D_Rq 7 "Message7" 6 "Message6" 5 "Message5" 4 "Message4" 3 "Message3" 2 "Message2" 1 "Message1" 0 "NoMessage" ;
VAL_ 1165 DrLatchRl_B_Falt 1 "Yes" 0 "No" ;
VAL_ 1165 DrLatchLckRl_B_Stat 1 "Locked" 0 "Unlock" ;
VAL_ 1165 ChildLckFdbckRl_B_Stat 1 "Locked" 0 "Unlock" ;
VAL_ 1164 DrHandleInnrFr_B_Stat 1 "Pulled" 0 "AtRest" ;
VAL_ 1164 DrLatchLckFr_B_Stat 1 "Locked" 0 "Unlock" ;
VAL_ 1164 DrLatchFrMsgTxt_D_Rq 7 "Message7" 6 "Message6" 5 "Message5" 4 "Message4" 3 "Message3" 2 "Message2" 1 "Message1" 0 "NoMessage" ;
VAL_ 1164 DrLatchFr_B_Falt 1 "Yes" 0 "No" ;
VAL_ 1163 DrHandleInnrFl_B_Stat 1 "Pulled" 0 "AtRest" ;
VAL_ 1163 DrLatchLckFl_B_Stat 1 "Locked" 0 "Unlock" ;
VAL_ 1163 DrLatchFlMsgTxt_D_Rq 7 "Message7" 6 "Message6" 5 "Message5" 4 "Message4" 3 "Message3" 2 "Message2" 1 "Message1" 0 "NoMessage" ;
VAL_ 1163 DrLatchFl_B_Falt 1 "Yes" 0 "No" ;
VAL_ 1162 SteClmnPos_D_Stat 7 "NotUsed3" 6 "NotUsed2" 5 "Error" 4 "Drive" 3 "Moving" 2 "Pending" 1 "EasyEntry" 0 "Null" ;
VAL_ 1162 PersIndexBcmb_D_Actl 7 "Unused_3" 6 "Unused_2" 5 "Unused_1" 4 "Vehicle" 3 "PERS_4" 2 "PERS_3" 1 "PERS_2" 0 "PERS_1" ;
VAL_ 1162 MemDrvDeny_B_StatCapm 1 "Yes" 0 "No" ;
VAL_ 1162 Cancl_Auto_Movmnt_CAPM 1 "Cancel" 0 "Null" ;
VAL_ 978 CnvtTopTWarn_B_Falt 1 "Yes" 0 "No" ;
VAL_ 978 CnvtTopTOvr_B_Falt 1 "Yes" 0 "No" ;
VAL_ 978 CnvtTopTDir_B_Falt 1 "Yes" 0 "No" ;
VAL_ 978 CnvtTopStall_B_Falt 1 "Yes" 0 "No" ;
VAL_ 978 CnvtTopSns_B_Falt 1 "Yes" 0 "No" ;
VAL_ 978 CnvtTopRvrse_B_Stat 1 "Yes" 0 "No" ;
VAL_ 978 CnvtTopRngOpen_B_Stat 1 "Active" 0 "Inactive" ;
VAL_ 978 CnvtTopRngClose_B_Stat 1 "Active" 0 "Inactive" ;
VAL_ 978 CnvtTopRestrc_B_Falt 1 "Yes" 0 "No" ;
VAL_ 978 CnvtTopRdy_B_Stat 1 "Yes" 0 "No" ;
VAL_ 978 CnvtTopPosSet_B_Stat 1 "Yes" 0 "No" ;
VAL_ 978 CnvtTopPos_D_Stat 15 "Faulty" 14 "NotUsed7" 13 "NotUsed6" 12 "NotUsed5" 11 "NotUsed4" 10 "NotUsed3" 9 "NotUsed2" 8 "NotUsed1" 7 "ShutdownComplete" 6 "NoNormalised" 5 "Moving" 4 "PositionIntermediate" 3 "PositionOpenTarget" 2 "PositionOpenPosition" 1 "PositionClosePosition" 0 "PositionCloseTarget" ;
VAL_ 978 CnvtTopPos_B_Falt 1 "Yes" 0 "No" ;
VAL_ 978 CnvtTopOut_B_Falt 1 "Yes" 0 "No" ;
VAL_ 978 CnvtTopOpen_D_Stat 3 "Faulty" 2 "NotUsed" 1 "Active" 0 "Inactive" ;
VAL_ 978 CnvtTopOpen_B_Stat 1 "Yes" 0 "No" ;
VAL_ 978 CnvtTopNom_B_Stat 1 "Yes" 0 "No" ;
VAL_ 978 CnvtTopDir_B_Falt 1 "Yes" 0 "No" ;
VAL_ 978 CnvtTopComplt_D_Stat 7 "DenormalizingReady" 6 "NormalizingReady" 5 "RunoutComplete" 4 "StopByPositioning" 3 "StopByFault" 2 "StopByPinch" 1 "StopByStall" 0 "StopByRequest" ;
VAL_ 978 CnvtTopCnfm_B_Stat 1 "Yes" 0 "No" ;
VAL_ 978 CnvtTopClose_D_Stat 3 "Faulty" 2 "NotUsed" 1 "Active" 0 "Inactive" ;
VAL_ 978 CnvtTopActv_B_Stat 1 "Yes" 0 "No" ;
VAL_ 978 TonneuCapMde_D_Stat 3 "Faulty" 2 "NotUsed" 1 "Installed" 0 "NotInstalled" ;
VAL_ 977 CnvtTopTrgt_D_Rq 7 "NotUsed4" 6 "NotUsed3" 5 "NotUsed2" 4 "NotUsed1" 3 "OpenTarget" 2 "OpenPosition" 1 "ClosePosition" 0 "CloseTarget" ;
VAL_ 977 CnvtTopSleepActv_B_Rq 1 "Active" 0 "Inactive" ;
VAL_ 977 CnvtTopPar_D_Rq 7 "NotUsed" 6 "ForceIncrease3" 5 "ForceIncrease2" 4 "ForceIncrease1" 3 "NoAdapt" 2 "Teach" 1 "NoPwmNoAp" 0 "Normal" ;
VAL_ 977 CnvtTopBrkActv_B_Rq 1 "Active" 0 "Inactive" ;
VAL_ 977 CnvtTop_D_Rq 7 "NotUsed" 6 "ResetErrorFlags" 5 "DiscardNormalization" 4 "SetNormalization" 3 "DirectDriveClose" 2 "DirectDriveOpen" 1 "DirectPosition" 0 "Stop" ;
VAL_ 977 CnvtTopPos_Up_Stat 1 "Up" 0 "Not_Up" ;
VAL_ 977 CnvtTopMsgTxt_D_Rq 3 "NotSecure" 2 "NotAvailable" 1 "RemoveCaps" 0 "NoWarning" ;
VAL_ 977 WndwCnvtTopDrop_B_Cmd 1 "Yes" 0 "No" ;
VAL_ 977 CnvtTopPos_Dn_Stat 1 "Down" 0 "Not_Down" ;
VAL_ 968 BrkDrvMde_D_Rq 7 "Faulty" 6 "RockCrawl" 5 "Baja" 4 "DragOrMudAndSand" 3 "Track" 2 "Snow_Wet" 1 "Sport" 0 "Normal" ;
VAL_ 968 LnchCtl_D_Rq 3 "NotUsed2" 2 "NotUsed1" 1 "LC_On" 0 "LC_Off" ;
VAL_ 968 SlMde_D_Rq 3 "IsaNotConfigured" 2 "Manual_Mode" 1 "Auto_Mode" 0 "Null" ;
VAL_ 968 IsaOffst_D_Rq 15 "Faulty" 14 "Null" 13 "Thirteen" 12 "Twelve" 11 "Eleven" 10 "Ten" 9 "Nine" 8 "Eight" 7 "Seven" 6 "Six" 5 "Five" 4 "Four" 3 "Three" 2 "Two" 1 "One" 0 "Zero" ;
VAL_ 968 CurrentColor_CmdGage 15 "NotUsed7" 14 "NotUsed6" 13 "NotUsed5" 12 "NotUsed4" 11 "NotUsed3" 10 "NotUsed2" 9 "NotUsed1" 8 "Null" 7 "Color7" 6 "Color6" 5 "Color5" 4 "Color4" 3 "Color3" 2 "Color2" 1 "Color1" 0 "Off" ;
VAL_ 968 BlendedColor_CmdGage 3 "NotUsed" 2 "Null" 1 "On" 0 "Off" ;
VAL_ 968 BlendColorRed_CmdGage 15 "NotUsed10" 14 "NotUsed9" 13 "NotUsed8" 12 "NotUsed7" 11 "NotUsed6" 10 "NotUsed5" 9 "NotUsed4" 8 "NotUsed3" 7 "NotUsed2" 6 "NotUsed1" 5 "_5" 4 "_4" 3 "_3" 2 "_2" 1 "_1" 0 "Null" ;
VAL_ 968 BlendColorGrn_CmdGage 15 "NotUsed10" 14 "NotUsed9" 13 "NotUsed8" 12 "NotUsed7" 11 "NotUsed6" 10 "NotUsed5" 9 "NotUsed4" 8 "NotUsed3" 7 "NotUsed2" 6 "NotUsed1" 5 "_5" 4 "_4" 3 "_3" 2 "_2" 1 "_1" 0 "Null" ;
VAL_ 968 BlendColorBlue_CmdGage 15 "NotUsed10" 14 "NotUsed9" 13 "NotUsed8" 12 "NotUsed7" 11 "NotUsed6" 10 "NotUsed5" 9 "NotUsed4" 8 "NotUsed3" 7 "NotUsed2" 6 "NotUsed1" 5 "_5" 4 "_4" 3 "_3" 2 "_2" 1 "_1" 0 "Null" ;
VAL_ 968 Dimming_Level_Cmd 3 "Low" 2 "Not_Used" 1 "High" 0 "Null" ;
VAL_ 968 Current_Color_Cmd 15 "NotUsed7" 14 "NotUsed6" 13 "NotUsed5" 12 "NotUsed4" 11 "NotUsed3" 10 "NotUsed2" 9 "NotUsed1" 8 "Null" 7 "Color7" 6 "Color6" 5 "Color5" 4 "Color4" 3 "Color3" 2 "Color2" 1 "Color1" 0 "Off" ;
VAL_ 968 BlendedColorRed_Cmd 15 "NotUsed10" 14 "NotUsed9" 13 "NotUsed8" 12 "NotUsed7" 11 "NotUsed6" 10 "NotUsed5" 9 "NotUsed4" 8 "NotUsed3" 7 "NotUsed2" 6 "NotUsed1" 5 "_5" 4 "_4" 3 "_3" 2 "_2" 1 "_1" 0 "Null" ;
VAL_ 968 BlendedColorGreen_Cmd 15 "NotUsed10" 14 "NotUsed9" 13 "NotUsed8" 12 "NotUsed7" 11 "NotUsed6" 10 "NotUsed5" 9 "NotUsed4" 8 "NotUsed3" 7 "NotUsed2" 6 "NotUsed1" 5 "_5" 4 "_4" 3 "_3" 2 "_2" 1 "_1" 0 "Null" ;
VAL_ 968 BlendedColorBlue_Cmd 15 "NotUsed10" 14 "NotUsed9" 13 "NotUsed8" 12 "NotUsed7" 11 "NotUsed6" 10 "NotUsed5" 9 "NotUsed4" 8 "NotUsed3" 7 "NotUsed2" 6 "NotUsed1" 5 "_5" 4 "_4" 3 "_3" 2 "_2" 1 "_1" 0 "Null" ;
VAL_ 968 BlendedColor_Cmd 3 "NotUsed" 2 "Null" 1 "On" 0 "Off" ;
VAL_ 968 SuspDrvMde_D_Rq 7 "Faulty" 6 "NotUsed2" 5 "NotUsed1" 4 "Drag" 3 "Track" 2 "Snow_Wet" 1 "Sport" 0 "Normal" ;
VAL_ 852 SeatMasgPsngrRr_D_Rq 15 "NotUsed_10" 14 "NotUsed_9" 13 "NotUsed_8" 12 "NotUsed_7" 11 "NotUsed_6" 10 "Pattern10" 9 "Pattern9" 8 "Pattern8" 7 "Pattern7" 6 "Pattern6" 5 "Pattern5" 4 "Pattern4" 3 "Pattern3" 2 "Pattern2" 1 "Pattern1" 0 "Null" ;
VAL_ 852 SeatFnPsgr_D_Rq2 7 "CushionMassage" 6 "LumbarMassage" 5 "UpperBolster" 4 "LowerBolster" 3 "UpperLumbar" 2 "MiddleLumbar" 1 "LowerLumbar" 0 "Null" ;
VAL_ 852 SeatFnChngPsgr2_D_Rq2 15 "Faulty" 14 "NotUsed9" 13 "NotUsed8" 12 "NotUsed7" 11 "NotUsed6" 10 "NotUsed5" 9 "NotUsed4" 8 "NotUsed3" 7 "NotUsed2" 6 "High" 5 "Low" 4 "Off" 3 "Decrease" 2 "Increase" 1 "NotUsed1" 0 "Inactive" ;
VAL_ 851 SeatMasgDrvRr_D_Rq 15 "NotUsed_10" 14 "NotUsed_9" 13 "NotUsed_8" 12 "NotUsed_7" 11 "NotUsed_6" 10 "Pattern10" 9 "Pattern9" 8 "Pattern8" 7 "Pattern7" 6 "Pattern6" 5 "Pattern5" 4 "Pattern4" 3 "Pattern3" 2 "Pattern2" 1 "Pattern1" 0 "Null" ;
VAL_ 851 SeatFnDrv_D_Rq2 7 "CushionMassage" 6 "LumbarMassage" 5 "UpperBolster" 4 "LowerBolster" 3 "UpperLumbar" 2 "MiddleLumbar" 1 "LowerLumbar" 0 "Null" ;
VAL_ 851 SeatFnChngDrv2_D_Rq2 15 "Faulty" 14 "NotUsed9" 13 "NotUsed8" 12 "NotUsed7" 11 "NotUsed6" 10 "NotUsed5" 9 "NotUsed4" 8 "NotUsed3" 7 "NotUsed2" 6 "High" 5 "Low" 4 "Off" 3 "Decrease" 2 "Increase" 1 "NotUsed1" 0 "Inactive" ;
VAL_ 876 SeatIntnsPsngrRr_D_Stat 7 "NotUsed_3" 6 "NotUsed_2" 5 "NotUsed_1" 4 "High" 3 "Medium" 2 "Low" 1 "Off" 0 "Null" ;
VAL_ 876 SeatMasgPsngrRr_D_Stat 15 "NotUsed_10" 14 "NotUsed_9" 13 "NotUsed_8" 12 "NotUsed_7" 11 "NotUsed_6" 10 "Pattern10" 9 "Pattern9" 8 "Pattern8" 7 "Pattern7" 6 "Pattern6" 5 "Pattern5" 4 "Pattern4" 3 "Pattern3" 2 "Pattern2" 1 "Pattern1" 0 "Null" ;
VAL_ 876 SeatSwtchRr_B_Stat 1 "On" 0 "Off" ;
VAL_ 876 SeatPRr_B_Stat 1 "Updating" 0 "NotUpdating" ;
VAL_ 876 SeatFnRr_D_Stat 7 "CushionMassage" 6 "LumbarMassage" 5 "UpperBolster" 4 "LowerBolster" 3 "UpperLumbar" 2 "MiddleLumbar" 1 "LowerLumbar" 0 "Null" ;
VAL_ 876 StmsCshnPsgr_D_Stat2 3 "High" 2 "Low" 1 "Off" 0 "Null" ;
VAL_ 876 StmsLmbrPsgr_D_Stat2 3 "High" 2 "Low" 1 "Off" 0 "Null" ;
VAL_ 1045 VehStab_D_Stat 15 "Faulty" 14 "No_Data_Exists" 13 "NotUsed6" 12 "NotUsed5" 11 "NotUsed4" 10 "NotUsed3" 9 "NotUsed2" 8 "Combined_OS_and_US" 7 "High_SSRA_no_OS" 6 "Straight" 5 "Post_Oversteer" 4 "Post_Transition" 3 "Countersteer" 2 "Understeer" 1 "Oversteer" 0 "Linear" ;
VAL_ 1045 BrkFluidLvl_D_Stat 3 "Invalid" 2 "Unknown" 1 "Low" 0 "OK" ;
VAL_ 1045 VehYawNonLin_W_Rq 4095 "Fault" 4094 "Unknown" ;
VAL_ 1045 VehYawLin_W_Rq 4095 "Fault" 4094 "Unknown" ;
VAL_ 1045 VehVActlBrk_D_Qf 3 "OK" 2 "Not_Within_Specifications" 1 "No_Data_Exists" 0 "Faulty" ;
VAL_ 1045 LsmcBrkDecel_D_Stat 7 "NotUsed_3" 6 "NotUsed_2" 5 "NotUsed_1" 4 "Denied" 3 "FaultDegraded" 2 "FaultExt" 1 "On" 0 "Off" ;
VAL_ 1189 PwStepMsgTxt_D_Rq 1 "DriveInhibited" 0 "NoMessage" 3 "NotUsed" 2 "Malfunction" ;
VAL_ 1189 Running_Board_Stat 3 "Unused" 2 "Manually_Deployed" 1 "All_Enabled" 0 "All_Disabled" ;
VAL_ 1189 PwStep_D_Stat 3 "PositionNotKnown" 2 "StepsNotStowed" 1 "StepsStowed" 0 "Off" ;
VAL_ 858 ClimtSyncRear_B_Stat 1 "Pressed" 0 "Not_Pressed" ;
VAL_ 858 ClimtSeatHeatRr_B_Stat 1 "Pressed" 0 "Not_Pressed" ;
VAL_ 858 ClimtSeatHeatRl_B_Stat 1 "Pressed" 0 "Not_Pressed" ;
VAL_ 858 ClimtSeatCoolRr_B_Stat 1 "Pressed" 0 "Not_Pressed" ;
VAL_ 858 ClimtSeatCoolRl_B_Stat 1 "Pressed" 0 "Not_Pressed" ;
VAL_ 858 ClimtRearTe3rd_D_Stat 3 "NotUsed" 2 "Decrement" 1 "Increment" 0 "Inactive" ;
VAL_ 858 ClimtRearPw3rd_B_Stat 1 "Pressed" 0 "Not_Pressed" ;
VAL_ 858 ClimtRearPnl3rd_B_Stat 1 "Pressed" 0 "Not_Pressed" ;
VAL_ 858 ClimtRearPf3rd_B_Stat 1 "Pressed" 0 "Not_Pressed" ;
VAL_ 858 ClimtRearFlr3rd_B_Stat 1 "Pressed" 0 "Not_Pressed" ;
VAL_ 858 ClimtRearBlwr3rd_D_Stat 3 "NotUsed" 2 "Decrement" 1 "Increment" 0 "Inactive" ;
VAL_ 858 ClimtRearAuto3rd_B_Stat 1 "Pressed" 0 "Not_Pressed" ;
VAL_ 858 ClimtRearViewR_D_Stat 3 "ThirdRow" 2 "SecondRow" 1 "Both" 0 "NotDisplayed" ;
VAL_ 858 ClimtRearTe_D_Stat 3 "NotUsed" 2 "Decrement" 1 "Increment" 0 "Inactive" ;
VAL_ 858 ClimtRearTe_An_Actl 511 "Faulty" ;
VAL_ 858 ClimtRearPw_B_Stat 1 "Pressed" 0 "Not_Pressed" ;
VAL_ 858 ClimtRearPnlFlr_B_Stat 1 "Pressed" 0 "Not_Pressed" ;
VAL_ 858 ClimtRearPnl_B_Stat 1 "Pressed" 0 "Not_Pressed" ;
VAL_ 858 ClimtRearFlr_B_Stat 1 "Pressed" 0 "Not_Pressed" ;
VAL_ 858 ClimtRearBlwr_D_Stat 3 "NotUsed" 2 "Decrement" 1 "Increment" 0 "Inactive" ;
VAL_ 858 ClimtRearBlwr_An_Actl 511 "Faulty" ;
VAL_ 858 ClimtRearAuto_B_Stat 1 "Pressed" 0 "Not_Pressed" ;
VAL_ 959 TrnPrkSys_D_Actl_UB 1 "Fresh_data" 0 "Unchanged_data" ;
VAL_ 959 TrnPrkSys_D_Actl 15 "Faulty" 14 "NotUsed_5" 13 "NotUsed_4" 12 "NotUsed_3" 11 "NotUsed_2" 10 "NotUsed_1" 9 "FrequencyError" 8 "OutOfRangeHigh" 7 "OutOfRangeLow" 6 "Override" 5 "OutOfPark" 4 "TransitionCloseToOutOfPark" 3 "AtNoSpring" 2 "TransitionCloseToPark" 1 "Park" 0 "NotKnown" ;
VAL_ 1255 BalrRight4Threat_D_Stat 1 "Yes" 0 "No" ;
VAL_ 1255 BalrRight4Fast_B_Stat 1 "Yes" 0 "No" ;
VAL_ 1255 BalrRight4Dsply_B_Stat 1 "Yes" 0 "No" ;
VAL_ 1254 BalrRight3Threat_D_Stat 1 "Yes" 0 "No" ;
VAL_ 1254 BalrRight3Fast_B_Stat 1 "Yes" 0 "No" ;
VAL_ 1254 BalrRight3Dsply_B_Stat 1 "Yes" 0 "No" ;
VAL_ 1253 BalrRight2Threat_D_Stat 1 "Yes" 0 "No" ;
VAL_ 1253 BalrRight2Fast_B_Stat 1 "Yes" 0 "No" ;
VAL_ 1253 BalrRight2Dsply_B_Stat 1 "Yes" 0 "No" ;
VAL_ 1252 BalrRight1Threat_D_Stat 1 "Yes" 0 "No" ;
VAL_ 1252 BalrRight1Fast_B_Stat 1 "Yes" 0 "No" ;
VAL_ 1252 BalrRight1Dsply_B_Stat 1 "Yes" 0 "No" ;
VAL_ 1251 BalrLeft4Threat_D_Stat 1 "Yes" 0 "No" ;
VAL_ 1251 BalrLeft4Fast_B_Stat 1 "Yes" 0 "No" ;
VAL_ 1251 BalrLeft4Dsply_B_Stat 1 "Yes" 0 "No" ;
VAL_ 1250 BalrLeft3Threat_D_Stat 1 "Yes" 0 "No" ;
VAL_ 1250 BalrLeft3Fast_B_Stat 1 "Yes" 0 "No" ;
VAL_ 1250 BalrLeft3Dsply_B_Stat 1 "Yes" 0 "No" ;
VAL_ 1249 BalrLeft2Threat_D_Stat 1 "Yes" 0 "No" ;
VAL_ 1249 BalrLeft2Fast_B_Stat 1 "Yes" 0 "No" ;
VAL_ 1249 BalrLeft2Dsply_B_Stat 1 "Yes" 0 "No" ;
VAL_ 1248 BalrLeft1Threat_D_Stat 1 "Yes" 0 "No" ;
VAL_ 1248 BalrLeft1Fast_B_Stat 1 "Yes" 0 "No" ;
VAL_ 1248 BalrLeft1Dsply_B_Stat 1 "Yes" 0 "No" ;
VAL_ 798 EmPrflNo_D_Rq_UB 1 "Fresh_data" 0 "Unchanged_data" ;
VAL_ 798 EmPrflNo_D_Rq 7 "NotUsed_3" 6 "NotUsed_2" 5 "NotUsed_1" 4 "Pers4" 3 "Pers3" 2 "Pers2" 1 "Pers1" 0 "Null" ;
VAL_ 798 EmPrflKeyAssoc_D_Rq_UB 1 "Fresh_data" 0 "Unchanged_data" ;
VAL_ 798 EmPrflKeyAssoc_D_Rq 7 "NotUsed_3" 6 "DisassociatePhone" 5 "EnterPhoneAssociation" 4 "OverwriteKey" 3 "DisassociateKey" 2 "ExitKeyAssociation" 1 "EnterKeyAssociation" 0 "Null" ;
VAL_ 798 ExitNotClrRight_B_Stat_UB 1 "Fresh_data" 0 "Unchanged_data" ;
VAL_ 798 ExitNotClrLeft_B_Stat_UB 1 "Fresh_data" 0 "Unchanged_data" ;
VAL_ 798 ExitNotClrRight_B_Stat 1 "True" 0 "False" ;
VAL_ 798 ExitNotClrLeft_B_Stat 1 "True" 0 "False" ;
VAL_ 798 ClimtCool_D_RqPt_UB 1 "Fresh_data" 0 "Unchanged_data" ;
VAL_ 798 ClimtCool_D_RqPt 3 "NotUsed_2" 2 "NotUsed_1" 1 "On" 0 "Off" ;
VAL_ 798 PudSptLghtRight_D_Rq_UB 1 "Fresh_data" 0 "Unchanged_data" ;
VAL_ 798 PudSptLghtLeft_D_Rq_UB 1 "Fresh_data" 0 "Unchanged_data" ;
VAL_ 798 PudSptLghtRight_D_Rq 3 "NotUsed" 2 "On" 1 "Off" 0 "Null" ;
VAL_ 798 PwRnngBoardPoll_D_Stat_UB 1 "Fresh_data" 0 "Unchanged_data" ;
VAL_ 798 PwRnngBoardPoll_D_Stat 3 "NotUsed" 2 "PkPresent" 1 "PkNotPresent" 0 "NotPolling" ;
VAL_ 798 AirCondRec_B_RqVehEl_UB 1 "Fresh_data" 0 "Unchanged_data" ;
VAL_ 798 AirCondRec_B_RqVehEl 1 "Yes" 0 "No" ;
VAL_ 798 RmtCtl_D_Stat 15 "Faulty" 14 "NotUsed_5" 13 "NotUsed_4" 12 "NotUsed_3" 11 "NotUsed_2" 10 "NotUsed_1" 9 "Shutdown" 8 "ManeuverFinished" 7 "ReadyForResume" 6 "Pause" 5 "Maneuvering" 4 "ReadyForManeuvering" 3 "Activation" 2 "Initialize" 1 "Preparation" 0 "Disabled" ;
VAL_ 798 RmtCtl_D_Stat_UB 1 "Fresh_data" 0 "Unchanged_data" ;
VAL_ 798 PudSptLghtLeft_D_Rq 3 "NotUsed" 2 "On" 1 "Off" 0 "Null" ;
VAL_ 798 PoliceDmngLvl_D_Stat 7 "NotUsed" 6 "Off_Night" 5 "Off_Day" 4 "Low1Night" 3 "Low1Day" 2 "Inactive" 1 "Decommissioned" 0 "Null" ;
VAL_ 798 VehWlcmFrwlMde_D_Stat_UB 1 "Fresh_data" 0 "Unchanged_data" ;
VAL_ 798 VehWlcmFrwl_D_Stat_UB 1 "Fresh_data" 0 "Unchanged_data" ;
VAL_ 798 VehWlcmFrwlMde_D_Stat 7 "IlluminatedExit" 6 "CourtesyLightingDelayExt" 5 "CourtesyLightingExtended" 4 "CourtesyLightingDelayAll" 3 "CourtesyLightingAll" 2 "IlluminatedEntry" 1 "Approach" 0 "Null" ;
VAL_ 798 VehWlcmFrwl_D_Stat 3 "RunStart" 2 "Farewell" 1 "Welcome" 0 "Null" ;
VAL_ 798 PoliceDmngLvl_D_Stat_UB 1 "Fresh_data" 0 "Unchanged_data" ;
VAL_ 302 TrnkFrontRleas_B_Stat 1 "Request" 0 "NoRequest" ;
VAL_ 374 GearEngag_D_Actl 7 "Undefined" 6 "Fwd_Clutch_Fully_Engaged" 5 "Neutral_Idle" 4 "Disengaged_to_Neutral_Idle" 3 "Disengaged_to_Neutral_Park" 2 "Engagement_in_Progress" 1 "InitializeFwdClutchEngagmt" 0 "Park_Neutral" ;
VAL_ 374 TrnRng_D_Rq 15 "Fault" 14 "Unknown_Position" 13 "NotUsed_2" 12 "NotUsed_1" 11 "Range6" 10 "Range5" 9 "Range4" 8 "Range3_M3_L3" 7 "Range2_M2_L2" 6 "Range1_M1_L1" 5 "Low" 4 "Sport_DriveSport_Mposition" 3 "Drive" 2 "Neutral" 1 "Reverse" 0 "Park" ;
VAL_ 374 TrnPrkSys_D_Actl 15 "Faulty" 14 "NotUsed_5" 13 "NotUsed_4" 12 "NotUsed_3" 11 "NotUsed_2" 10 "NotUsed_1" 9 "FrequencyError" 8 "OutOfRangeHigh" 7 "OutOfRangeLow" 6 "Override" 5 "OutOfPark" 4 "TransitionCloseToOutOfPark" 3 "AtNoSpring" 2 "TransitionCloseToPark" 1 "Park" 0 "NotKnown" ;
VAL_ 374 GearLvr_D_ActlDrv 15 "Fault" 14 "Unknown_Position" 13 "NotUsed_2" 12 "NotUsed_1" 11 "Range6" 10 "Range5" 9 "Range4" 8 "Range3_M3_L3" 7 "Range2_M2_L2" 6 "Range1_M1_L1" 5 "Low" 4 "Sport_DriveSport_Mposition" 3 "Drive" 2 "Neutral" 1 "Reverse" 0 "Park" ;
VAL_ 374 GearPos_D_Trg 15 "Unknown" 14 "Reverse" 13 "Undefined_5" 12 "Undefined_4" 11 "Undefined_3" 10 "Tenth" 9 "Ninth" 8 "Eighth" 7 "Seventh" 6 "Sixth" 5 "Fifth" 4 "Fourth" 3 "Third" 2 "Second" 1 "First" 0 "Neutral" ;
VAL_ 374 GearPos_D_Actl 15 "Unknown" 14 "Reverse" 13 "Undefined_5" 12 "Undefined_4" 11 "Undefined_3" 10 "Tenth" 9 "Ninth" 8 "Eighth" 7 "Seventh" 6 "Sixth" 5 "Fifth" 4 "Fourth" 3 "Third" 2 "Second" 1 "First" 0 "Neutral" ;
VAL_ 300 TrukBedLght_B_Stat2 1 "On" 0 "Off" ;
VAL_ 662 Running_Board_Cmd2 3 "Unused" 2 "Manually_Deployed" 1 "All_Enabled" 0 "All_Disabled" ;
VAL_ 662 Third_Rear_Set_Temp 31 "HI" 30 "29_5" 29 "29_0" 28 "28_5" 27 "28_0" 26 "27_5" 25 "27_0" 24 "26_5" 23 "26_0" 22 "25_5" 21 "25_0" 20 "24_5" 19 "24_0" 18 "23_5" 17 "23_0" 16 "22_5" 15 "22_0" 14 "21_5" 13 "21_0" 12 "20_5" 11 "20_0" 10 "19_5" 9 "19_0" 8 "18_5" 7 "18_0" 6 "17_5" 5 "17_0" 4 "16_5" 3 "16_0" 2 "15_5" 1 "LO" 0 "No_Request" ;
VAL_ 662 Third_Rear_Blower_Speed 15 "NotUsed_6" 14 "NotUsed_5" 13 "NotUsed_4" 12 "NotUsed_3" 11 "NotUsed_2" 10 "Zero_Blower" 9 "Max_Blower" 8 "Min_Blower" 7 "Blower_Speed_7" 6 "Blower_Speed_6" 5 "Blower_Speed_5" 4 "Blower_Speed_4" 3 "Blower_Speed_3" 2 "Blower_Speed_2" 1 "Blower_Speed_1" 0 "No_Request" ;
VAL_ 662 Rear_Temp 15 "NotUsed_6" 14 "NotUsed_5" 13 "NotUsed_4" 12 "NotUsed_3" 11 "NotUsed_2" 10 "NotUsed_1" 9 "Max_Heating" 8 "Level_3_Heating" 7 "Level_2_Heating" 6 "Level_1_Heating" 5 "No_Heating_Cooling" 4 "Level_1_Cooling" 3 "Level_2_Cooling" 2 "Level_3_Cooling" 1 "Max_Cooling" 0 "No_Request" ;
VAL_ 662 Rear_Set_Temp 31 "HI" 30 "29_5" 29 "29_0" 28 "28_5" 27 "28_0" 26 "27_5" 25 "27_0" 24 "26_5" 23 "26_0" 22 "25_5" 21 "25_0" 20 "24_5" 19 "24_0" 18 "23_5" 17 "23_0" 16 "22_5" 15 "22_0" 14 "21_5" 13 "21_0" 12 "20_5" 11 "20_0" 10 "19_5" 9 "19_0" 8 "18_5" 7 "18_0" 6 "17_5" 5 "17_0" 4 "16_5" 3 "16_0" 2 "15_5" 1 "LO" 0 "No_Request" ;
VAL_ 662 Rear_Blower_Speed 15 "NotUsed_6" 14 "NotUsed_5" 13 "NotUsed_4" 12 "NotUsed_3" 11 "NotUsed_2" 10 "Zero_Blower" 9 "Max_Blower" 8 "Min_Blower" 7 "Blower_Speed_7" 6 "Blower_Speed_6" 5 "Blower_Speed_5" 4 "Blower_Speed_4" 3 "Blower_Speed_3" 2 "Blower_Speed_2" 1 "Blower_Speed_1" 0 "No_Request" ;
VAL_ 670 DrHandleOuterRl_D_Stat 7 "NotUsed" 6 "Transition" 5 "FlushFault" 4 "DeployFault2" 3 "DeployFault1" 2 "Flush" 1 "Deploy" 0 "None" ;
VAL_ 670 DrHandleOuterFl_D_Stat 7 "NotUsed" 6 "Transition" 5 "FlushFault" 4 "DeployFault2" 3 "DeployFault1" 2 "Flush" 1 "Deploy" 0 "None" ;
VAL_ 669 DrHandleOuterRr_D_Stat 7 "NotUsed" 6 "Transition" 5 "FlushFault" 4 "DeployFault2" 3 "DeployFault1" 2 "Flush" 1 "Deploy" 0 "None" ;
VAL_ 669 DrHandleOuterFr_D_Stat 7 "NotUsed" 6 "Transition" 5 "FlushFault" 4 "DeployFault2" 3 "DeployFault1" 2 "Flush" 1 "Deploy" 0 "None" ;
VAL_ 1079 ApaMde_D_Stat_UB 1 "Fresh_data" 0 "Unchanged_data" ;
VAL_ 1079 ApaMde_D_Stat 7 "NotUsed" 6 "RePA" 5 "ParkIn" 4 "POA" 3 "PPA" 2 "SAPP" 1 "Off" 0 "Null" ;
VAL_ 1079 TrlrAidEnbl_D2_Stat_UB 1 "Fresh_data" 0 "Unchanged_data" ;
VAL_ 1079 TrlrAidEnbl_D2_Stat 7 "NotUsed_1" 6 "TbaActiveExpertActive" 5 "TbaActiveExpertAvail" 4 "TbaOffTrgActive" 3 "TbaOffTrgSetup" 2 "TbaSetup" 1 "TbaActive" 0 "Inactive" ;
VAL_ 1079 PoliceAux4Swtch_B_Stat_UB 1 "Fresh_data" 0 "Unchanged_data" ;
VAL_ 1079 PoliceAux3Swtch_B_Stat_UB 1 "Fresh_data" 0 "Unchanged_data" ;
VAL_ 1079 PoliceAux2Swtch_B_Stat_UB 1 "Fresh_data" 0 "Unchanged_data" ;
VAL_ 1079 PoliceAux1Swtch_B_Stat_UB 1 "Fresh_data" 0 "Unchanged_data" ;
VAL_ 1079 PoliceAux4Swtch_B_Stat 1 "Switch_Active" 0 "Switch_Not_Active" ;
VAL_ 1079 PoliceAux3Swtch_B_Stat 1 "Switch_Active" 0 "Switch_Not_Active" ;
VAL_ 1079 PoliceAux2Swtch_B_Stat 1 "Switch_Active" 0 "Switch_Not_Active" ;
VAL_ 1079 PoliceAux1Swtch_B_Stat 1 "Switch_Active" 0 "Switch_Not_Active" ;
VAL_ 1079 GenericSwtch3_No_Actl_UB 1 "Fresh_data" 0 "Unchanged_data" ;
VAL_ 1079 GenericSwtch2_No_Actl_UB 1 "Fresh_data" 0 "Unchanged_data" ;
VAL_ 1079 GenericSwtch1_No_Actl_UB 1 "Fresh_data" 0 "Unchanged_data" ;
VAL_ 1079 RbaSys_D_Stat_UB 1 "Fresh_data" 0 "Unchanged_data" ;
VAL_ 1079 RbaSys_D_Stat 3 "Faulty" 2 "Available" 1 "Suspended" 0 "Disabled" ;
VAL_ 1079 HybMdeStat_D_Dsply_UB 1 "Fresh_data" 0 "Unchanged_data" ;
VAL_ 1079 Rba_D_Stat 3 "NotUsed" 2 "Disabled" 1 "On" 0 "Off" ;
VAL_ 1079 Rba_D_Stat_UB 1 "Fresh_data" 0 "Unchanged_data" ;
VAL_ 1079 BalrMde_D_Rq_UB 1 "Fresh_data" 0 "Unchanged_data" ;
VAL_ 1079 BalrSwtch_D_Stat_UB 1 "Fresh_data" 0 "Unchanged_data" ;
VAL_ 1079 BalrMde_D_Rq 3 "High" 2 "Medium" 1 "Low" 0 "Null" ;
VAL_ 1079 ChrgGoTTouchEnbl_B_Rq 1 "Request" 0 "NoRequest" ;
VAL_ 1079 ChrgGoTExtHtrEnbl_B_Rq 1 "Request" 0 "NoRequest" ;
VAL_ 1079 ChrgGoTTouchEnbl_B_Rq_UB 1 "Fresh_data" 0 "Unchanged_data" ;
VAL_ 1079 ChrgGoTExtHtrEnbl_B_Rq_UB 1 "Fresh_data" 0 "Unchanged_data" ;
VAL_ 1079 LcwaAlrtRight_B_Rq_UB 1 "Fresh_data" 0 "Unchanged_data" ;
VAL_ 1079 LcwaAlrtLeft_B_Rq_UB 1 "Fresh_data" 0 "Unchanged_data" ;
VAL_ 1079 LcwaAlrtRight_B_Rq 1 "Yes" 0 "No" ;
VAL_ 1079 LcwaAlrtLeft_B_Rq 1 "Yes" 0 "No" ;
VAL_ 1079 ApaSteScanMde_D_Stat 3 "Steering" 2 "Scanning" 1 "NotScanning" 0 "Null" ;
VAL_ 1079 ApaSteScanMde_D_Stat_UB 1 "Fresh_data" 0 "Unchanged_data" ;
VAL_ 1079 BattTracClimtDis_B_Stat_UB 1 "Fresh_data" 0 "Unchanged_data" ;
VAL_ 1079 BattTracClimtDis_B_Stat 1 "Enable" 0 "Disable" ;
VAL_ 1079 BalrSwtch_D_Stat 3 "NotUsed" 2 "Pressed" 1 "NotPressed" 0 "Null" ;
VAL_ 1079 TrlrAidMsgTxt_D2_Rq_UB 1 "Fresh_data" 0 "Unchanged_data" ;
VAL_ 1079 TrlrAidMsgTxt_D2_Rq 63 "Message63" 62 "Message62" 61 "Message61" 60 "Message60" 55 "Message55" 50 "Message50" 45 "Message45" 40 "Message40" 35 "Message35" 31 "Message31" 30 "Message30" 29 "Message29" 28 "Message28" 27 "Message27" 26 "Message26" 25 "Message25" 24 "Message24" 23 "Message23" 22 "Message22" 21 "Message21" 20 "Message20" 19 "Message19" 18 "Message18" 17 "Message17" 16 "Message16" 15 "Message15" 14 "Message14" 13 "Message13" 12 "Message12" 11 "Message11" 10 "Message10" 9 "Message9" 8 "Message8" 7 "Message7" 6 "Message6" 5 "Message5" 4 "Message4" 3 "Message3" 2 "Message2" 1 "Message1" 0 "NoMessage" ;
VAL_ 1079 HybMdeStat_D_Dsply 7 "NotUsed2" 6 "EV_Charge" 5 "EV_Override" 4 "Forced_EV_Mode" 3 "Forced_Charge_Sustain_Mode" 2 "Auto_Charge_Sustain_Mode" 1 "Auto_Charge_Deplete_Mode" 0 "Null_State" ;
VAL_ 875 SeatIntnsDrvRr_D_Stat 7 "NotUsed_3" 6 "NotUsed_2" 5 "NotUsed_1" 4 "High" 3 "Medium" 2 "Low" 1 "Off" 0 "Null" ;
VAL_ 875 SeatMasgDrvRr_D_Stat 15 "NotUsed_10" 14 "NotUsed_9" 13 "NotUsed_8" 12 "NotUsed_7" 11 "NotUsed_6" 10 "Pattern10" 9 "Pattern9" 8 "Pattern8" 7 "Pattern7" 6 "Pattern6" 5 "Pattern5" 4 "Pattern4" 3 "Pattern3" 2 "Pattern2" 1 "Pattern1" 0 "Null" ;
VAL_ 875 SeatSwtchRl_B_Stat 1 "On" 0 "Off" ;
VAL_ 875 SeatPRl_B_Stat 1 "Updating" 0 "NotUpdating" ;
VAL_ 875 SeatFnRl_D_Stat 7 "CushionMassage" 6 "LumbarMassage" 5 "UpperBolster" 4 "LowerBolster" 3 "UpperLumbar" 2 "MiddleLumbar" 1 "LowerLumbar" 0 "Null" ;
VAL_ 875 StmsLmbrDrv_D_Stat2 3 "High" 2 "Low" 1 "Off" 0 "Null" ;
VAL_ 875 StmsCshnDrv_D_Stat2 3 "High" 2 "Low" 1 "Off" 0 "Null" ;
VAL_ 1095 Pers4Phone_D_Stat 7 "SevenPhoneAssociated" 6 "SixPhoneAssociated" 5 "FivePhoneAssociated" 4 "FourPhoneAssociated" 3 "ThreePhoneAssociated" 2 "TwoPhoneAssociated" 1 "OnePhoneAssociated" 0 "NoPhoneAssociated" ;
VAL_ 1095 Pers3Phone_D_Stat 7 "SevenPhoneAssociated" 6 "SixPhoneAssociated" 5 "FivePhoneAssociated" 4 "FourPhoneAssociated" 3 "ThreePhoneAssociated" 2 "TwoPhoneAssociated" 1 "OnePhoneAssociated" 0 "NoPhoneAssociated" ;
VAL_ 1095 Pers2Phone_D_Stat 7 "SevenPhoneAssociated" 6 "SixPhoneAssociated" 5 "FivePhoneAssociated" 4 "FourPhoneAssociated" 3 "ThreePhoneAssociated" 2 "TwoPhoneAssociated" 1 "OnePhoneAssociated" 0 "NoPhoneAssociated" ;
VAL_ 1095 Pers1Phone_D_Stat 7 "SevenPhoneAssociated" 6 "SixPhoneAssociated" 5 "FivePhoneAssociated" 4 "FourPhoneAssociated" 3 "ThreePhoneAssociated" 2 "TwoPhoneAssociated" 1 "OnePhoneAssociated" 0 "NoPhoneAssociated" ;
VAL_ 1095 HeadLghtOn_D_Rq 7 "NotUsed2" 6 "NotUsed1" 5 "DrlBoth" 4 "DrlRight" 3 "DrlLeft" 2 "High" 1 "Low" 0 "Off" ;
VAL_ 1095 PepsKeyActv_D_Stat 15 "NotUsed11" 14 "NotUsed10" 13 "NotUsed9" 12 "NotUsed8" 11 "NotUsed7" 10 "NotUsed6" 9 "NotUsed5" 8 "Key4Active" 7 "NotUsed4" 6 "NotUsed3" 5 "NotUsed2" 4 "Key3Active" 3 "NotUsed1" 2 "Key2Active" 1 "Key1Active" 0 "NoKeyActive" ;
VAL_ 1095 VehLck_D_Dsply 3 "Faulty" 2 "Unlock" 1 "Lock" 0 "Off" ;
VAL_ 948 Tire_Press_ILR_Stat 4 "Alert" 15 "Not_Supported" 3 "Fault" 2 "Low" 1 "Normal" 0 "Unknown" ;
VAL_ 948 Tire_Press_IRR_Stat 4 "Alert" 15 "Not_Supported" 3 "Fault" 2 "Low" 1 "Normal" 0 "Unknown" ;
VAL_ 948 Tire_Press_LR_OLR_Stat 4 "Alert" 15 "Not_Supported" 3 "Fault" 2 "Low" 1 "Normal" 0 "Unknown" ;
VAL_ 948 Tire_Press_RR_ORR_Stat 4 "Alert" 15 "Not_Supported" 3 "Fault" 2 "Low" 1 "Normal" 0 "Unknown" ;
VAL_ 948 Tire_Press_RF_Stat 4 "Alert" 15 "Not_Supported" 3 "Fault" 2 "Low" 1 "Normal" 0 "Unknown" ;
VAL_ 948 Tire_Press_LF_Stat 4 "Alert" 15 "Not_Supported" 3 "Fault" 2 "Low" 1 "Normal" 0 "Unknown" ;
VAL_ 948 Tire_Press_System_Stat 13 "Training_Complete" 12 "Train_InsideLeftRear_tire" 11 "Train_OutsideLeftRear_tire" 10 "Train_LeftRear_tire" 9 "Train_InsideRtRear_tire" 8 "Train_OutsideRtRear_tire" 7 "Train_RightRear_tire" 14 "Tires_not_trained" 6 "Train_RightFront_tire" 5 "Train_LeftFront_tire" 4 "Systm_Activ_Composite_Stat" 3 "Low_Composite_Stat" 2 "Sensr_Fault_Composite_Stat" 1 "Systm_Fault_Composite_Stat" 0 "Unknown_Composite_Stat" ;
VAL_ 948 Tire_Press_Telltale 3 "Not_Used" 2 "Flash" 1 "On" 0 "Off" ;
VAL_ 948 TirePReset_D_Stat 3 "Not_Used" 2 "Nack" 1 "Ack" 0 "Null" ;
VAL_ 840 FohAddHeater_D_Rq 3 "NotUsed" 2 "On" 1 "Off" 0 "NoModeSelected" ;
VAL_ 840 FohT2Friday_T_Rq 1 "Enable" 0 "Disable" ;
VAL_ 840 FohT1Friday_T_Rq 1 "Enable" 0 "Disable" ;
VAL_ 840 FohT2Wednesday_T_Rq 1 "Enable" 0 "Disable" ;
VAL_ 840 FohT2Tuesday_T_Rq 1 "Enable" 0 "Disable" ;
VAL_ 840 FohT2Thursday_T_Rq 1 "Enable" 0 "Disable" ;
VAL_ 840 FohT2Sunday_T_Rq 1 "Enable" 0 "Disable" ;
VAL_ 840 FohT2Saturday_T_Rq 1 "Enable" 0 "Disable" ;
VAL_ 840 FohT2Monday_T_Rq 1 "Enable" 0 "Disable" ;
VAL_ 840 FohT1Wednesday_T_Rq 1 "Enable" 0 "Disable" ;
VAL_ 840 FohT1Tuesday_T_Rq 1 "Enable" 0 "Disable" ;
VAL_ 840 FohT1Thursday_T_Rq 1 "Enable" 0 "Disable" ;
VAL_ 840 FohT1Sunday_T_Rq 1 "Enable" 0 "Disable" ;
VAL_ 840 FohT1Saturday_T_Rq 1 "Enable" 0 "Disable" ;
VAL_ 840 FohT1Monday_T_Rq 1 "Enable" 0 "Disable" ;
VAL_ 945 PrkLckCtlMsgTxt_D2_Rq 7 "Message7" 6 "Message6" 5 "Message5" 4 "Message4" 3 "Message3" 2 "Message2" 1 "Message1" 0 "NoMessage" ;
VAL_ 945 KeyPadCodeDgt7_D_Dsply 15 "NotUsed_4" 14 "NotUsed_3" 13 "NotUsed_2" 12 "NotUsed_1" 11 "Button7_8and9_0" 10 "Button0" 9 "Button9_0or9" 8 "Button8" 7 "Button7_8or7" 6 "Button6" 5 "Button5_6or5" 4 "Button4" 3 "Button3_4or3" 2 "Button2" 1 "Button1_2or1" 0 "EndofString" ;
VAL_ 945 KeyPadCodeDgt6_D_Dsply 15 "NotUsed_4" 14 "NotUsed_3" 13 "NotUsed_2" 12 "NotUsed_1" 11 "Button7_8and9_0" 10 "Button0" 9 "Button9_0or9" 8 "Button8" 7 "Button7_8or7" 6 "Button6" 5 "Button5_6or5" 4 "Button4" 3 "Button3_4or3" 2 "Button2" 1 "Button1_2or1" 0 "EndofString" ;
VAL_ 945 KeyPadCodeDgt5_D_Dsply 15 "NotUsed_4" 14 "NotUsed_3" 13 "NotUsed_2" 12 "NotUsed_1" 11 "Button7_8and9_0" 10 "Button0" 9 "Button9_0or9" 8 "Button8" 7 "Button7_8or7" 6 "Button6" 5 "Button5_6or5" 4 "Button4" 3 "Button3_4or3" 2 "Button2" 1 "Button1_2or1" 0 "EndofString" ;
VAL_ 945 KeyPadCodeDgt4_D_Dsply 15 "NotUsed_4" 14 "NotUsed_3" 13 "NotUsed_2" 12 "NotUsed_1" 11 "Button7_8and9_0" 10 "Button0" 9 "Button9_0or9" 8 "Button8" 7 "Button7_8or7" 6 "Button6" 5 "Button5_6or5" 4 "Button4" 3 "Button3_4or3" 2 "Button2" 1 "Button1_2or1" 0 "EndofString" ;
VAL_ 945 KeyPadCodeDgt3_D_Dsply 15 "NotUsed_4" 14 "NotUsed_3" 13 "NotUsed_2" 12 "NotUsed_1" 11 "Button7_8and9_0" 10 "Button0" 9 "Button9_0or9" 8 "Button8" 7 "Button7_8or7" 6 "Button6" 5 "Button5_6or5" 4 "Button4" 3 "Button3_4or3" 2 "Button2" 1 "Button1_2or1" 0 "EndofString" ;
VAL_ 945 KeyPadCodeDgt2_D_Dsply 15 "NotUsed_4" 14 "NotUsed_3" 13 "NotUsed_2" 12 "NotUsed_1" 11 "Button7_8and9_0" 10 "Button0" 9 "Button9_0or9" 8 "Button8" 7 "Button7_8or7" 6 "Button6" 5 "Button5_6or5" 4 "Button4" 3 "Button3_4or3" 2 "Button2" 1 "Button1_2or1" 0 "EndofString" ;
VAL_ 945 KeyPadCodeDgt1_D_Dsply 15 "NotUsed_4" 14 "NotUsed_3" 13 "NotUsed_2" 12 "NotUsed_1" 11 "Button7_8and9_0" 10 "Button0" 9 "Button9_0or9" 8 "Button8" 7 "Button7_8or7" 6 "Button6" 5 "Button5_6or5" 4 "Button4" 3 "Button3_4or3" 2 "Button2" 1 "Button1_2or1" 0 "EndofString" ;
VAL_ 945 KeyOffMde_D_Actl 15 "NotUsed_11" 14 "NotUsed_10" 13 "NotUsed_9" 12 "NotUsed_8" 11 "NotUsed_7" 10 "NotUsed_6" 9 "NotUsed_5" 8 "NotUsed_4" 7 "NotUsed_3" 6 "NotUsed_2" 5 "NotUsed_1" 4 "CriticalBattery" 3 "Hibernate" 2 "Transport" 1 "Factory" 0 "Normal" ;
VAL_ 945 PrkLckCtlLatch_B_Rq 1 "On" 0 "Off" ;
VAL_ 981 PreCondActv_B_Actl_UB 1 "Fresh_data" 0 "Unchanged_data" ;
VAL_ 981 HvacPrecondRecirc_D_Rq_UB 1 "Fresh_data" 0 "Unchanged_data" ;
VAL_ 981 HvacPrecondMode2_D_Rq_UB 1 "Fresh_data" 0 "Unchanged_data" ;
VAL_ 981 HvacPrecondBlwr2_D_Rq_UB 1 "Fresh_data" 0 "Unchanged_data" ;
VAL_ 981 HvacPrecondAC_D_Rq_UB 1 "Fresh_data" 0 "Unchanged_data" ;
VAL_ 981 HvacPrecond_Te_Rq_UB 1 "Fresh_data" 0 "Unchanged_data" ;
VAL_ 981 DrvCondTpRrDefrs_B_Rq_UB 1 "Fresh_data" 0 "Unchanged_data" ;
VAL_ 981 PreCondActv_B_Actl 1 "On" 0 "Off" ;
VAL_ 981 HvacPrecondRecirc_D_Rq 3 "Last_User_Setting" 2 "Auto" 1 "Recirc" 0 "Outside" ;
VAL_ 981 HvacPrecondMode2_D_Rq 15 "NotUsed4" 14 "NotUsed3" 13 "NotUsed2" 12 "NotUsed1" 11 "Last_User_Settings" 10 "Auto" 9 "Max_Defrost" 8 "Windshield_Panel_Floor" 7 "Windshield_Panel" 6 "Windshield" 5 "Windshield_Floor" 4 "Floor" 3 "Panel_Floor" 2 "Panel" 1 "MAX_AC" 0 "Off" ;
VAL_ 981 HvacPrecondBlwr2_D_Rq 15 "NotUsed6" 14 "NotUsed5" 13 "NotUsed4" 12 "NotUsed3" 11 "NotUsed2" 10 "NotUsed1" 9 "Last_User_Setting" 8 "Auto" 7 "Speed7" 6 "Speed6" 5 "Speed5" 4 "Speed4" 3 "Speed3" 2 "Speed2" 1 "Speed1" 0 "Off" ;
VAL_ 981 HvacPrecondAC_D_Rq 3 "Last_User_Setting" 2 "Auto" 1 "On" 0 "Off" ;
VAL_ 981 DrvCondTpRrDefrs_B_Rq 1 "On" 0 "Off" ;
